VERSION ""

NS_ :

BS_:

BU_: PowertrainControlModule AtmosphericSensor SafetyRestraintSystem2 Aftertreatment_2_GasOutlet Aftertreatment_2_GasIntake DieselParticulateFilterControl Turbocharger SafetyRestraintSystem1 CabDisplay2 Aftertreatment_1_GasOutlet Aftertreatment_1_GasIntake OnBoardDataLogger OffBoardDiagnosticTool2 OffBoardDiagnosticTool1 FileServer ParkingBrakeController SeatController2 FanDriveController SteeringColumnUnit CommunicationUnitRadio CommunicationUnitSatellite CommunicationUnitCellular PropulsionBatteryCharger ChassisController2 ChassisController1 EngineValveControl AuxiliaryHeater2 AuxiliaryHeater1 ClutchUnit RampControl InformationSystem1 SuspensionSystemController2 OilSensor VehicleDynamicStability ExhaustEmissionController TransmissionDisplay2 TransmissionDisplay1 ClimateControl2 WaterPumpController RearAxleSteeringController LightingOperatorControl SeatController1 IgnitionController2 IgnitionController1 TirePressureController CabController2 CabController1 PneumaticSystemController SuspensionSystemController1 HydraulicPumpController EnduranceBrakingSystem RetarderExhaustEngine2 OnBoardDiagnosticUnit HeadwayController RetarderExhaustEngine1 CabDisplay1 ManagementComputer VirtualTerminal OffVehicleGateway PowerTakeOffFront HitchControl AuxiliaryValveControl BodyController TractorTrailerBridge1 StarterSystem ElectricalSystem VehicleSecurity VehicleNavigation AerodynamicControl ElectricalChargingSystem ClimateControl1 TripRecorder InstrumentCluster SuspensionDriveAxle2 SuspensionDriveAxle1 SuspensionSteerAxle SteeringController FuelSystem CruiseControl RetarderDriveline RetarderEngine BrakesDriveAxle2 BrakesDriveAxle1 BrakesSystemController BrakesSteerAxle AxleDrive2 AxleDrive1 AxleSteering PowerTakeOff ShiftConsoleSecondary ShiftConsolePrimary Transmission2 Transmission1 Engine2 Engine1

BO_ 2365446142 EJM1: 8 Vector__XXX
 SG_ Joystick1Button13PressedStatus : 62|2@1+ (1,0) [0|3] "" Vector__XXX
 SG_ Joystick1Button14PressedStatus : 60|2@1+ (1,0) [0|3] "" Vector__XXX
 SG_ Joystick1Button15PressedStatus : 58|2@1+ (1,0) [0|3] "" Vector__XXX
 SG_ Joystick1Button16PressedStatus : 56|2@1+ (1,0) [0|3] "" Vector__XXX
 SG_ Jystick1GripXAxisDetentPosStatus : 54|2@1+ (1,0) [0|3] "" Vector__XXX
 SG_ Jystick1GripYAxisDetentPosStatus : 52|2@1+ (1,0) [0|3] "" Vector__XXX
 SG_ Jystick1ThetaAxisDetentPosStatus : 50|2@1+ (1,0) [0|3] "" Vector__XXX
 SG_ Joystick1ThetaAxisPos : 38|10@1+ (0.1,0) [0|100] "%" Vector__XXX
 SG_ Jystck1ThtAxsClckwsPstvPosStatus : 36|2@1+ (1,0) [0|3] "" Vector__XXX
 SG_ Jystck1ThetaAxisNeutralPosStatus : 32|2@1+ (1,0) [0|3] "" Vector__XXX
 SG_ Joystick1GripYAxisPos : 22|10@1+ (0.1,0) [0|100] "%" Vector__XXX
 SG_ Jystck1GrpYAxsLvrFrwrdPstvPsStts : 20|2@1+ (1,0) [0|3] "" Vector__XXX
 SG_ Jystck1GrpYAxsLvrBckNgtvPsStatus : 18|2@1+ (1,0) [0|3] "" Vector__XXX
 SG_ Aftrtrtmnt1DslExhstFldPrprtsPrlm : 16|2@1+ (1,0) [0|3] "" Vector__XXX
 SG_ Joystick1GripXAxisPos : 6|10@1+ (0.1,0) [0|100] "%" Vector__XXX
 SG_ Jystck1GrpXAxsLvrRghtPstvPsSttus : 4|2@1+ (1,0) [0|3] "" Vector__XXX
 SG_ Jystck1GrpXAxsLvrLftNgtvPsStatus : 2|2@1+ (1,0) [0|3] "" Vector__XXX
 SG_ Jystck1GripXAxisNeutralPosStatus : 0|2@1+ (1,0) [0|3] "" Vector__XXX
 SG_ Jystck1ThtAxsCntrClckwsNgtvPsStt : 34|2@1+ (1,0) [0|3] "" Vector__XXX

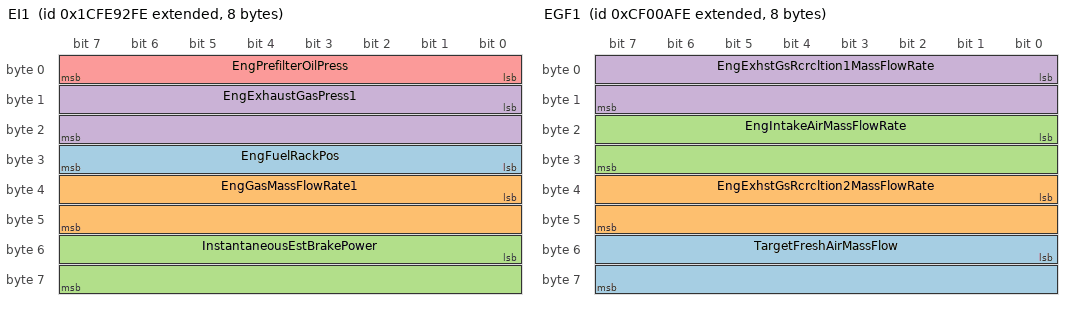
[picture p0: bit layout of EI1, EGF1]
BO_ 2633929470 EI1: 8 Vector__XXX
 SG_ EngFuelRackPos : 24|8@1+ (0.4,0) [0|100] "%" Vector__XXX
 SG_ EngGasMassFlowRate1 : 32|16@1+ (0.05,0) [0|3212.75] "kg/h" Vector__XXX
 SG_ InstantaneousEstBrakePower : 48|16@1+ (0.5,0) [0|32127.5] "kW" Vector__XXX
 SG_ EngExhaustGasPress1 : 8|16@1+ (0.0078125,-250) [-250|251.9921875] "kPa" Vector__XXX
 SG_ EngPrefilterOilPress : 0|8@1+ (4,0) [0|1000] "kPa" Vector__XXX

BO_ 2633937406 EH: 8 Vector__XXX
 SG_ TotalECURunTime : 32|32@1+ (0.05,0) [0|210554060.75] "h" Vector__XXX
 SG_ TotalECUDistance : 0|32@1+ (0.125,0) [0|526385151.875] "km" Vector__XXX

BO_ 2364541694 EGF1: 8 Vector__XXX
 SG_ TargetFreshAirMassFlow : 48|16@1+ (0.05,0) [0|3212.75] "kg/h" Vector__XXX
 SG_ EngExhstGsRcrcltion2MassFlowRate : 32|16@1+ (0.05,0) [0|3212.75] "kg/h" Vector__XXX
 SG_ EngIntakeAirMassFlowRate : 16|16@1+ (0.05,0) [0|3212.75] "kg/h" Vector__XXX
 SG_ EngExhstGsRcrcltion1MassFlowRate : 0|16@1+ (0.05,0) [0|3212.75] "kg/h" Vector__XXX

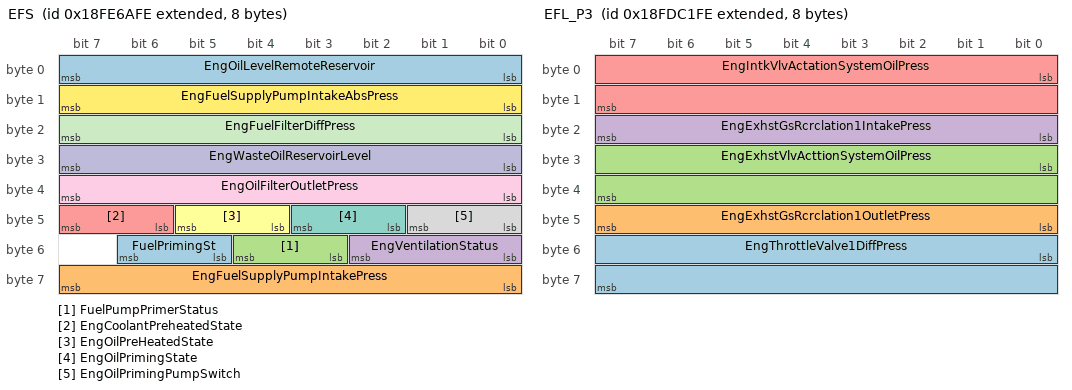
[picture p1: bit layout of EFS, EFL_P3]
BO_ 2566810366 EFS: 8 Vector__XXX
 SG_ FuelPrimingSt : 53|2@1+ (1,0) [0|3] "" Vector__XXX
 SG_ EngFuelSupplyPumpIntakePress : 56|8@1+ (2,0) [0|500] "kPa" Vector__XXX
 SG_ FuelPumpPrimerStatus : 51|2@1+ (1,0) [0|3] "" Vector__XXX
 SG_ EngVentilationStatus : 48|3@1+ (1,0) [0|7] "" Vector__XXX
 SG_ EngCoolantPreheatedState : 46|2@1+ (1,0) [0|3] "" Vector__XXX
 SG_ EngOilPreHeatedState : 44|2@1+ (1,0) [0|3] "" Vector__XXX
 SG_ EngOilPrimingState : 42|2@1+ (1,0) [0|3] "" Vector__XXX
 SG_ EngOilPrimingPumpSwitch : 40|2@1+ (1,0) [0|3] "" Vector__XXX
 SG_ EngOilFilterOutletPress : 32|8@1+ (4,0) [0|1000] "kPa" Vector__XXX
 SG_ EngWasteOilReservoirLevel : 24|8@1+ (0.4,0) [0|100] "%" Vector__XXX
 SG_ EngFuelFilterDiffPress : 16|8@1+ (2,0) [0|500] "kPa" Vector__XXX
 SG_ EngFuelSupplyPumpIntakeAbsPress : 8|8@1+ (2,0) [0|500] "kPa" Vector__XXX
 SG_ EngOilLevelRemoteReservoir : 0|8@1+ (0.4,0) [0|100] "%" Vector__XXX

BO_ 2566767102 EFL_P3: 8 Vector__XXX
 SG_ EngThrottleValve1DiffPress : 48|16@1+ (0.1,0) [0|6425.5] "kPa" Vector__XXX
 SG_ EngExhstGsRcrclation1OutletPress : 40|8@1+ (2,0) [0|500] "kPa" Vector__XXX
 SG_ EngExhstVlvActtionSystemOilPress : 24|16@1+ (0.00390625,0) [0|250.99609375] "MPa" Vector__XXX
 SG_ EngExhstGsRcrclation1IntakePress : 16|8@1+ (2,0) [0|500] "kPa" Vector__XXX
 SG_ EngIntkVlvActationSystemOilPress : 0|16@1+ (0.00390625,0) [0|250.99609375] "MPa" Vector__XXX

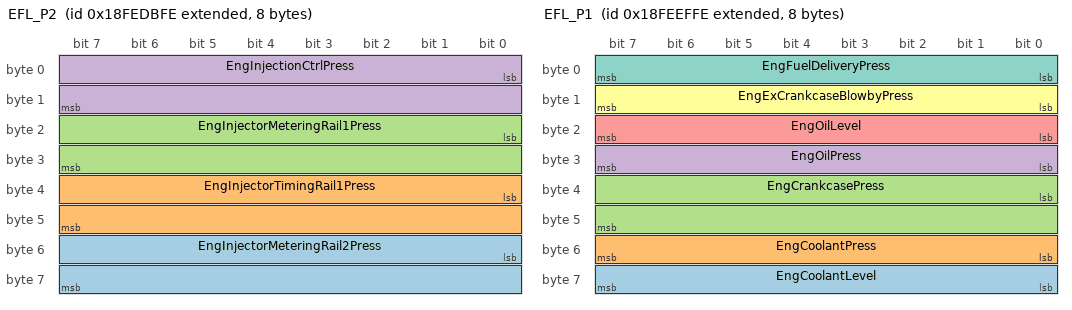
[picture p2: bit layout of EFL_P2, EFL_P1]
BO_ 2566839294 EFL_P2: 8 Vector__XXX
 SG_ EngInjectorMeteringRail2Press : 48|16@1+ (0.00390625,0) [0|250.99609375] "MPa" Vector__XXX
 SG_ EngInjectorTimingRail1Press : 32|16@1+ (0.00390625,0) [0|250.99609375] "MPa" Vector__XXX
 SG_ EngInjectorMeteringRail1Press : 16|16@1+ (0.00390625,0) [0|250.99609375] "MPa" Vector__XXX
 SG_ EngInjectionCtrlPress : 0|16@1+ (0.00390625,0) [0|250.99609375] "MPa" Vector__XXX

BO_ 2566844414 EFL_P1: 8 Vector__XXX
 SG_ EngCoolantLevel : 56|8@1+ (0.4,0) [0|100] "%" Vector__XXX
 SG_ EngCoolantPress : 48|8@1+ (2,0) [0|500] "kPa" Vector__XXX
 SG_ EngCrankcasePress : 32|16@1+ (0.0078125,-250) [-250|251.9921875] "kPa" Vector__XXX
 SG_ EngOilPress : 24|8@1+ (4,0) [0|1000] "kPa" Vector__XXX
 SG_ EngOilLevel : 16|8@1+ (0.4,0) [0|100] "%" Vector__XXX
 SG_ EngExCrankcaseBlowbyPress : 8|8@1+ (0.05,0) [0|12.5] "kPa" Vector__XXX
 SG_ EngFuelDeliveryPress : 0|8@1+ (4,0) [0|1000] "kPa" Vector__XXX

BO_ 2633929726 EES: 8 Vector__XXX
 SG_ SafetyWireStatus : 16|2@1+ (1,0) [0|3] "" Vector__XXX
 SG_ ElectricalLoad : 0|16@1+ (0.5,0) [0|32127.5] "kW" Vector__XXX

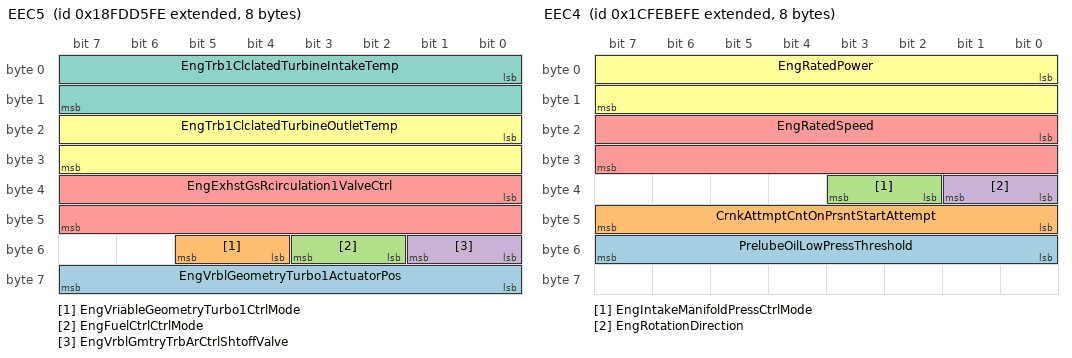
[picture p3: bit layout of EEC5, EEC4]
BO_ 2566772222 EEC5: 8 Vector__XXX
 SG_ EngVrblGeometryTurbo1ActuatorPos : 56|8@1+ (0.4,0) [0|100] "%" Vector__XXX
 SG_ EngVriableGeometryTurbo1CtrlMode : 52|2@1+ (1,0) [0|3] "" Vector__XXX
 SG_ EngFuelCtrlCtrlMode : 50|2@1+ (1,0) [0|3] "" Vector__XXX
 SG_ EngVrblGmtryTrbArCtrlShtoffValve : 48|2@1+ (1,0) [0|3] "" Vector__XXX
 SG_ EngExhstGsRcirculation1ValveCtrl : 32|16@1+ (0.0025,0) [0|100] "%" Vector__XXX
 SG_ EngTrb1ClclatedTurbineOutletTemp : 16|16@1+ (0.03125,-273) [-273|1734.96875] "°C" Vector__XXX
 SG_ EngTrb1ClclatedTurbineIntakeTemp : 0|16@1+ (0.03125,-273) [-273|1734.96875] "°C" Vector__XXX

BO_ 2633940734 EEC4: 8 Vector__XXX
 SG_ PrelubeOilLowPressThreshold : 48|8@1+ (4,0) [0|1000] "kPa" Vector__XXX
 SG_ CrnkAttmptCntOnPrsntStartAttempt : 40|8@1+ (1,0) [0|250] "" Vector__XXX
 SG_ EngIntakeManifoldPressCtrlMode : 34|2@1+ (1,0) [0|3] "" Vector__XXX
 SG_ EngRotationDirection : 32|2@1+ (1,0) [0|3] "" Vector__XXX
 SG_ EngRatedSpeed : 16|16@1+ (0.125,0) [0|8031.875] "rpm" Vector__XXX
 SG_ EngRatedPower : 0|16@1+ (0.5,0) [0|32127.5] "kW" Vector__XXX

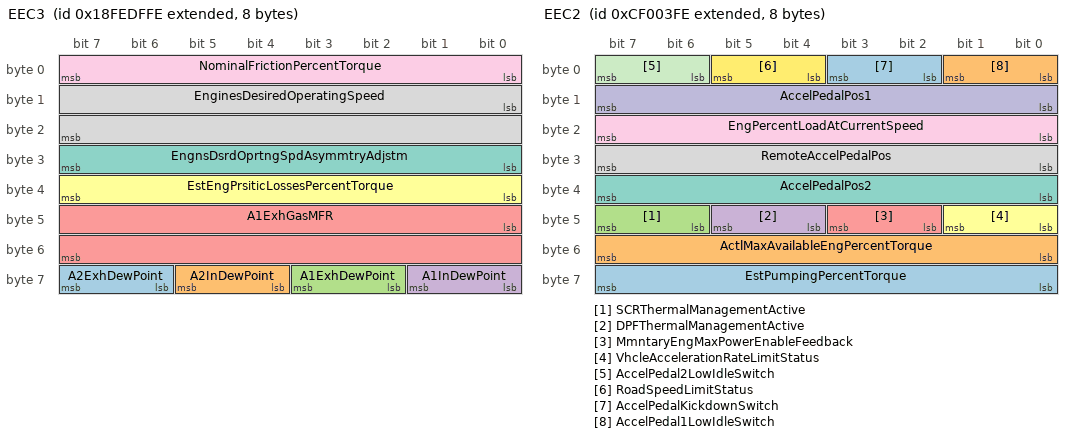
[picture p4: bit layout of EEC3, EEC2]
BO_ 2566840318 EEC3: 8 Vector__XXX
 SG_ A2ExhDewPoint : 62|2@1+ (1,0) [0|3] "" Vector__XXX
 SG_ A2InDewPoint : 60|2@1+ (1,0) [0|3] "" Vector__XXX
 SG_ A1ExhDewPoint : 58|2@1+ (1,0) [0|3] "" Vector__XXX
 SG_ A1InDewPoint : 56|2@1+ (1,0) [0|3] "" Vector__XXX
 SG_ A1ExhGasMFR : 40|16@1+ (0.2,0) [0|12851] "kg/h" Vector__XXX
 SG_ EstEngPrsiticLossesPercentTorque : 32|8@1+ (1,-125) [0|125] "%" Vector__XXX
 SG_ EngnsDsrdOprtngSpdAsymmtryAdjstm : 24|8@1+ (1,0) [0|250] "" Vector__XXX
 SG_ EnginesDesiredOperatingSpeed : 8|16@1+ (0.125,0) [0|8031.875] "rpm" Vector__XXX
 SG_ NominalFrictionPercentTorque : 0|8@1+ (1,-125) [-125|125] "%" Vector__XXX

BO_ 2364539902 EEC2: 8 Vector__XXX
 SG_ EstPumpingPercentTorque : 56|8@1+ (1,-125) [-125|125] "%" Vector__XXX
 SG_ ActlMaxAvailableEngPercentTorque : 48|8@1+ (0.4,0) [0|100] "%" Vector__XXX
 SG_ SCRThermalManagementActive : 46|2@1+ (1,0) [0|3] "" Vector__XXX
 SG_ DPFThermalManagementActive : 44|2@1+ (1,0) [0|3] "" Vector__XXX
 SG_ MmntaryEngMaxPowerEnableFeedback : 42|2@1+ (1,0) [0|3] "" Vector__XXX
 SG_ VhcleAccelerationRateLimitStatus : 40|2@1+ (1,0) [0|3] "" Vector__XXX
 SG_ AccelPedalPos2 : 32|8@1+ (0.4,0) [0|100] "%" Vector__XXX
 SG_ RemoteAccelPedalPos : 24|8@1+ (0.4,0) [0|100] "%" Vector__XXX
 SG_ EngPercentLoadAtCurrentSpeed : 16|8@1+ (1,0) [0|125] "%" Vector__XXX
 SG_ AccelPedalPos1 : 8|8@1+ (0.4,0) [0|100] "%" Vector__XXX
 SG_ AccelPedal2LowIdleSwitch : 6|2@1+ (1,0) [0|3] "" Vector__XXX
 SG_ RoadSpeedLimitStatus : 4|2@1+ (1,0) [0|3] "" Vector__XXX
 SG_ AccelPedalKickdownSwitch : 2|2@1+ (1,0) [0|3] "" Vector__XXX
 SG_ AccelPedal1LowIdleSwitch : 0|2@1+ (1,0) [0|3] "" Vector__XXX

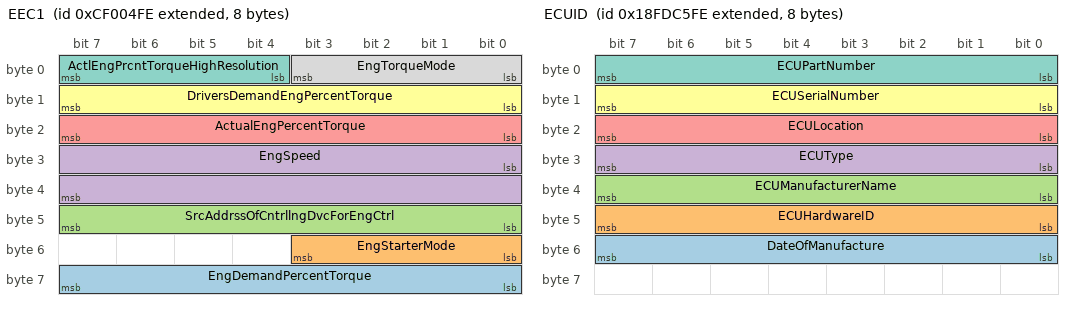
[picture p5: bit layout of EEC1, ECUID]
BO_ 2364540158 EEC1: 8 Vector__XXX
 SG_ EngDemandPercentTorque : 56|8@1+ (1,-125) [-125|125] "%" Vector__XXX
 SG_ EngStarterMode : 48|4@1+ (1,0) [0|15] "" Vector__XXX
 SG_ SrcAddrssOfCntrllngDvcForEngCtrl : 40|8@1+ (1,0) [0|253] "" Vector__XXX
 SG_ EngSpeed : 24|16@1+ (0.125,0) [0|8031.875] "rpm" Vector__XXX
 SG_ ActualEngPercentTorque : 16|8@1+ (1,-125) [0|125] "%" Vector__XXX
 SG_ DriversDemandEngPercentTorque : 8|8@1+ (1,-125) [0|125] "%" Vector__XXX
 SG_ ActlEngPrcntTorqueHighResolution : 4|4@1+ (0.125,0) [0|0.875] "%" Vector__XXX
 SG_ EngTorqueMode : 0|4@1+ (1,0) [0|15] "" Vector__XXX

BO_ 2566768126 ECUID: 8 Vector__XXX
 SG_ DateOfManufacture : 48|8@1+ (1,0) [0|255] "" Vector__XXX
 SG_ ECUHardwareID : 40|8@1+ (1,0) [0|255] "" Vector__XXX
 SG_ ECUManufacturerName : 32|8@1+ (1,0) [0|255] "" Vector__XXX
 SG_ ECUType : 24|8@1+ (1,0) [0|255] "" Vector__XXX
 SG_ ECULocation : 16|8@1+ (1,0) [0|255] "" Vector__XXX
 SG_ ECUSerialNumber : 8|8@1+ (1,0) [0|255] "" Vector__XXX
 SG_ ECUPartNumber : 0|8@1+ (1,0) [0|255] "" Vector__XXX

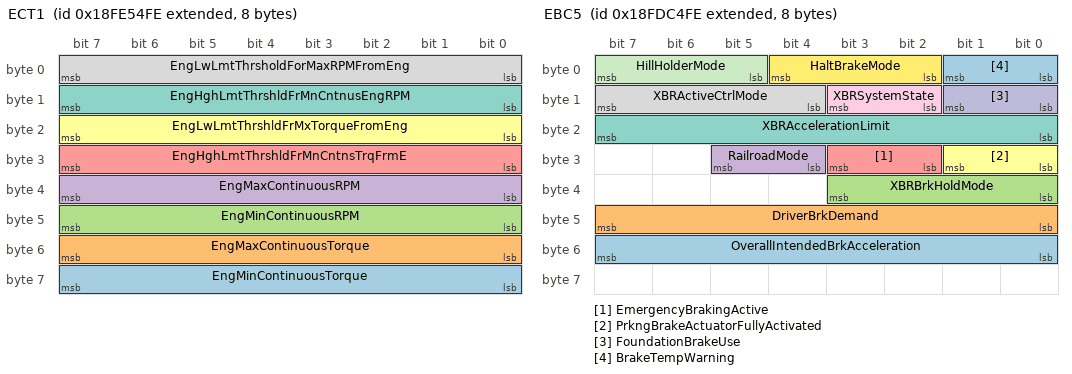
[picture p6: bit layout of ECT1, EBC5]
BO_ 2566804734 ECT1: 8 Vector__XXX
 SG_ EngMinContinuousTorque : 56|8@1+ (1,-125) [-125|125] "%" Vector__XXX
 SG_ EngMaxContinuousTorque : 48|8@1+ (1,-125) [-125|125] "%" Vector__XXX
 SG_ EngMinContinuousRPM : 40|8@1+ (32,0) [0|8000] "rpm" Vector__XXX
 SG_ EngMaxContinuousRPM : 32|8@1+ (32,0) [0|8000] "rpm" Vector__XXX
 SG_ EngHghLmtThrshldFrMnCntnsTrqFrmE : 24|8@1+ (1,-125) [-125|125] "%" Vector__XXX
 SG_ EngLwLmtThrshldFrMxTorqueFromEng : 16|8@1+ (1,-125) [-125|125] "%" Vector__XXX
 SG_ EngHghLmtThrshldFrMnCntnusEngRPM : 8|8@1+ (32,0) [0|8000] "rpm" Vector__XXX
 SG_ EngLwLmtThrsholdForMaxRPMFromEng : 0|8@1+ (32,0) [0|8000] "rpm" Vector__XXX

BO_ 2566841342 EC1: 40 Vector__XXX
 SG_ DefaultIdleTrqLmt : 312|8@1+ (1,-125) [0|125] "%" Vector__XXX
 SG_ SupportTSC1CtrlPurposeGroup4 : 304|8@1+ (1,0) [0|255] "" Vector__XXX
 SG_ SupportTSC1CtrlPurposeGroup3 : 296|8@1+ (1,0) [0|255] "" Vector__XXX
 SG_ SupportTSC1CtrlPurposeGroup2 : 288|8@1+ (1,0) [0|255] "" Vector__XXX
 SG_ SupportTSC1CtrlPurposeGroup1 : 280|8@1+ (1,0) [0|255] "" Vector__XXX
 SG_ SupportVariableRateTSC1Message : 272|8@1+ (1,0) [0|255] "" Vector__XXX
 SG_ EngDefaultTorqueLimit : 256|16@1+ (1,0) [0|64255] "Nm" Vector__XXX
 SG_ EngMomentOfInertia : 240|16@1+ (0.004,0) [0|257.02] "kg*m²" Vector__XXX
 SG_ EngExRngRqstdSpdCtrlRngUpprLimit : 224|16@1+ (0.125,0) [0|8031.875] "rpm" Vector__XXX
 SG_ EngRqstdTrqueCtrlRangeUpperLimit : 216|8@1+ (1,-125) [0|125] "%" Vector__XXX
 SG_ EngRqstdTrqueCtrlRangeLowerLimit : 208|8@1+ (1,-125) [0|125] "%" Vector__XXX
 SG_ EngRqstdSpeedCtrlRangeUpperLimit : 200|8@1+ (10,0) [0|2500] "rpm" Vector__XXX
 SG_ EngRqstdSpeedCtrlRangeLowerLimit : 192|8@1+ (10,0) [0|2500] "rpm" Vector__XXX
 SG_ EngMaxMomentaryOverrideTimeLimit : 184|8@1+ (0.1,0) [0|25] "s" Vector__XXX
 SG_ EngMxMmentaryOverrideSpeedPoint7 : 168|16@1+ (0.125,0) [0|8031.875] "rpm" Vector__XXX
 SG_ EngReferenceTorque : 152|16@1+ (1,0) [0|64255] "Nm" Vector__XXX
 SG_ EngGain : 136|16@1+ (0.00078125,0) [0|50.19921875] "%/rpm" Vector__XXX
 SG_ EngSpeedAtHighIdlePoint6 : 120|16@1+ (0.125,0) [0|8031.875] "rpm" Vector__XXX
 SG_ EngPercentTorqueAtPoint5 : 112|8@1+ (1,-125) [0|125] "%" Vector__XXX
 SG_ EngSpeedAtPoint5 : 96|16@1+ (0.125,0) [0|8031.875] "rpm" Vector__XXX
 SG_ EngPercentTorqueAtPoint4 : 88|8@1+ (1,-125) [0|125] "%" Vector__XXX
 SG_ EngSpeedAtPoint4 : 72|16@1+ (0.125,0) [0|8031.875] "rpm" Vector__XXX
 SG_ EngPercentTorqueAtPoint3 : 64|8@1+ (1,-125) [0|125] "%" Vector__XXX
 SG_ EngSpeedAtPoint3 : 48|16@1+ (0.125,0) [0|8031.875] "rpm" Vector__XXX
 SG_ EngPercentTorqueAtPoint2 : 40|8@1+ (1,-125) [0|125] "%" Vector__XXX
 SG_ EngSpeedAtPoint2 : 24|16@1+ (0.125,0) [0|8031.875] "rpm" Vector__XXX
 SG_ EngPercentTorqueAtIdlePoint1 : 16|8@1+ (1,-125) [0|125] "%" Vector__XXX
 SG_ EngSpeedAtIdlePoint1 : 0|16@1+ (0.125,0) [0|8031.875] "rpm" Vector__XXX

BO_ 2566767870 EBC5: 8 Vector__XXX
 SG_ OverallIntendedBrkAcceleration : 48|8@1+ (0.1,-12.5) [-12.5|12.5] "m/s²" Vector__XXX
 SG_ DriverBrkDemand : 40|8@1+ (0.1,-12.5) [-12.5|12.5] "m/s²" Vector__XXX
 SG_ XBRBrkHoldMode : 32|4@1+ (1,0) [0|15] "" Vector__XXX
 SG_ RailroadMode : 28|2@1+ (1,0) [0|3] "" Vector__XXX
 SG_ EmergencyBrakingActive : 26|2@1+ (1,0) [0|3] "" Vector__XXX
 SG_ PrkngBrakeActuatorFullyActivated : 24|2@1+ (1,0) [0|3] "" Vector__XXX
 SG_ XBRAccelerationLimit : 16|8@1+ (0.1,-12.5) [-10|10] "m/s²" Vector__XXX
 SG_ XBRActiveCtrlMode : 12|4@1+ (1,0) [0|15] "" Vector__XXX
 SG_ XBRSystemState : 10|2@1+ (1,0) [0|3] "" Vector__XXX
 SG_ FoundationBrakeUse : 8|2@1+ (1,0) [0|3] "" Vector__XXX
 SG_ HillHolderMode : 5|3@1+ (1,0) [0|7] "" Vector__XXX
 SG_ HaltBrakeMode : 2|3@1+ (1,0) [0|7] "" Vector__XXX
 SG_ BrakeTempWarning : 0|2@1+ (1,0) [0|3] "" Vector__XXX

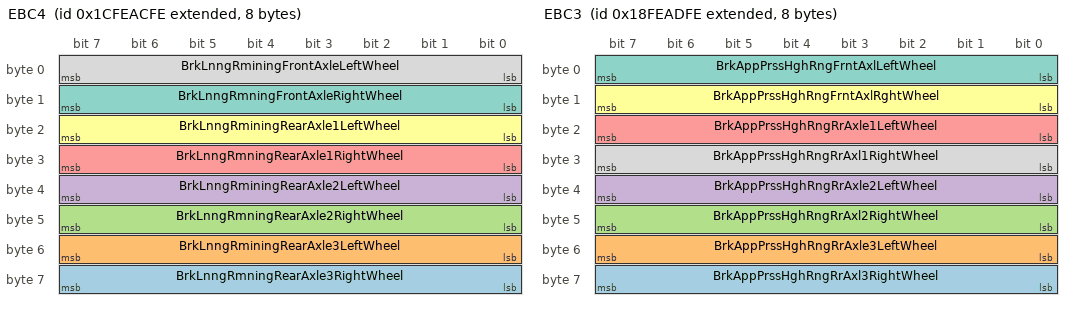
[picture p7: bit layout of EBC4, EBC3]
BO_ 2633936126 EBC4: 8 Vector__XXX
 SG_ BrkLnngRmningRearAxle3RightWheel : 56|8@1+ (0.4,0) [0|100] "%" Vector__XXX
 SG_ BrkLnngRminingRearAxle3LeftWheel : 48|8@1+ (0.4,0) [0|100] "%" Vector__XXX
 SG_ BrkLnngRmningRearAxle2RightWheel : 40|8@1+ (0.4,0) [0|100] "%" Vector__XXX
 SG_ BrkLnngRminingRearAxle2LeftWheel : 32|8@1+ (0.4,0) [0|100] "%" Vector__XXX
 SG_ BrkLnngRmningRearAxle1RightWheel : 24|8@1+ (0.4,0) [0|100] "%" Vector__XXX
 SG_ BrkLnngRminingRearAxle1LeftWheel : 16|8@1+ (0.4,0) [0|100] "%" Vector__XXX
 SG_ BrkLnngRmningFrontAxleRightWheel : 8|8@1+ (0.4,0) [0|100] "%" Vector__XXX
 SG_ BrkLnngRminingFrontAxleLeftWheel : 0|8@1+ (0.4,0) [0|100] "%" Vector__XXX

BO_ 2566827518 EBC3: 8 Vector__XXX
 SG_ BrkAppPrssHghRngRrAxl3RightWheel : 56|8@1+ (5,0) [0|1250] "kPa" Vector__XXX
 SG_ BrkAppPrssHghRngRrAxle3LeftWheel : 48|8@1+ (5,0) [0|1250] "kPa" Vector__XXX
 SG_ BrkAppPrssHghRngRrAxl2RightWheel : 40|8@1+ (5,0) [0|1250] "kPa" Vector__XXX
 SG_ BrkAppPrssHghRngRrAxle2LeftWheel : 32|8@1+ (5,0) [0|1250] "kPa" Vector__XXX
 SG_ BrkAppPrssHghRngRrAxle1LeftWheel : 16|8@1+ (5,0) [0|1250] "kPa" Vector__XXX
 SG_ BrkAppPrssHghRngFrntAxlRghtWheel : 8|8@1+ (5,0) [0|1250] "kPa" Vector__XXX
 SG_ BrkAppPrssHghRngFrntAxlLeftWheel : 0|8@1+ (5,0) [0|1250] "kPa" Vector__XXX
 SG_ BrkAppPrssHghRngRrAxl1RightWheel : 24|8@1+ (5,0) [0|1250] "kPa" Vector__XXX

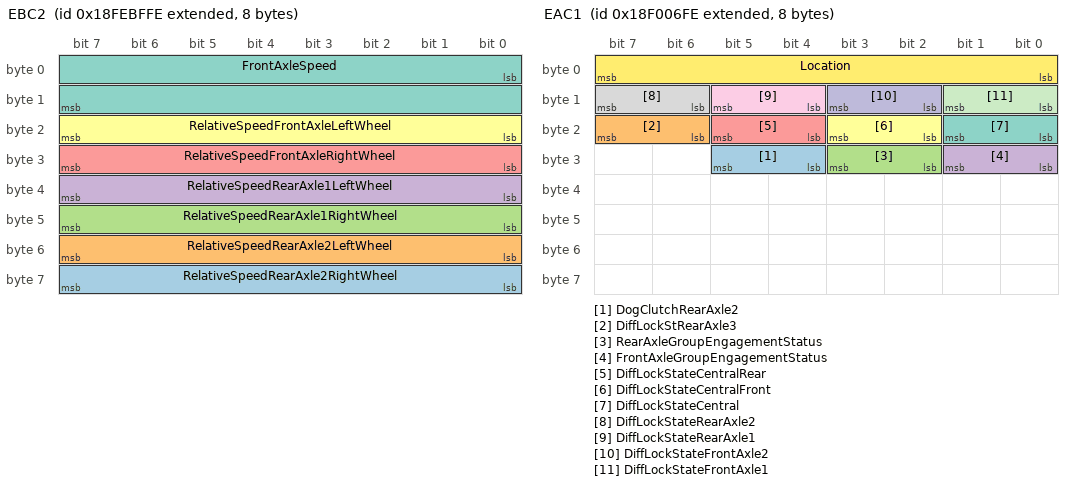
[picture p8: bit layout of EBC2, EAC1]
BO_ 2566832126 EBC2: 8 Vector__XXX
 SG_ RelativeSpeedRearAxle2RightWheel : 56|8@1+ (0.0625,-7.8125) [-7.8125|7.8125] "km/h" Vector__XXX
 SG_ RelativeSpeedRearAxle2LeftWheel : 48|8@1+ (0.0625,-7.8125) [-7.8125|7.8125] "km/h" Vector__XXX
 SG_ RelativeSpeedRearAxle1RightWheel : 40|8@1+ (0.0625,-7.8125) [-7.8125|7.8125] "km/h" Vector__XXX
 SG_ RelativeSpeedRearAxle1LeftWheel : 32|8@1+ (0.0625,-7.8125) [-7.8125|7.8125] "km/h" Vector__XXX
 SG_ RelativeSpeedFrontAxleRightWheel : 24|8@1+ (0.0625,-7.8125) [-7.8125|7.8125] "km/h" Vector__XXX
 SG_ RelativeSpeedFrontAxleLeftWheel : 16|8@1+ (0.0625,-7.8125) [-7.8125|7.8125] "km/h" Vector__XXX
 SG_ FrontAxleSpeed : 0|16@1+ (0.00390625,0) [0|250.99609375] "km/h" Vector__XXX

BO_ 2565865982 EBC1: 8 Vector__XXX
 SG_ RailroadModeSw : 56|2@1+ (1,0) [0|3] "" Vector__XXX
 SG_ TrctrMntdTrailerABSWarningSignal : 62|2@1+ (1,0) [0|3] "" Vector__XXX
 SG_ TrailerABSStatus : 60|2@1+ (1,0) [0|3] "" Vector__XXX
 SG_ HaltBrakeSwitch : 58|2@1+ (1,0) [0|3] "" Vector__XXX
 SG_ SrcAddrssOfCntrllngDvcFrBrkeCtrl : 48|8@1+ (1,0) [0|253] "" Vector__XXX
 SG_ ATC_ASRInformationSignal : 46|2@1+ (1,0) [0|3] "" Vector__XXX
 SG_ ABS_EBSAmberWarningSignal : 44|2@1+ (1,0) [0|3] "" Vector__XXX
 SG_ EBSRedWarningSignal : 42|2@1+ (1,0) [0|3] "" Vector__XXX
 SG_ ABSFullyOperational : 40|2@1+ (1,0) [0|3] "" Vector__XXX
 SG_ EngRetarderSelection : 32|8@1+ (0.4,0) [0|100] "%" Vector__XXX
 SG_ RemoteAccelEnableSwitch : 30|2@1+ (1,0) [0|3] "" Vector__XXX
 SG_ EngAuxShutdownSwitch : 28|2@1+ (1,0) [0|3] "" Vector__XXX
 SG_ EngDerateSwitch : 26|2@1+ (1,0) [0|3] "" Vector__XXX
 SG_ AccelInterlockSwitch : 24|2@1+ (1,0) [0|3] "" Vector__XXX
 SG_ TractionCtrlOverrideSwitch : 22|2@1+ (1,0) [0|3] "" Vector__XXX
 SG_ ASRHillHolderSwitch : 20|2@1+ (1,0) [0|3] "" Vector__XXX
 SG_ ASROffroadSwitch : 18|2@1+ (1,0) [0|3] "" Vector__XXX
 SG_ ABSOffroadSwitch : 16|2@1+ (1,0) [0|3] "" Vector__XXX
 SG_ BrakePedalPos : 8|8@1+ (0.4,0) [0|100] "%" Vector__XXX
 SG_ EBSBrakeSwitch : 6|2@1+ (1,0) [0|3] "" Vector__XXX
 SG_ AntiLockBrakingActive : 4|2@1+ (1,0) [0|3] "" Vector__XXX
 SG_ ASRBrakeCtrlActive : 2|2@1+ (1,0) [0|3] "" Vector__XXX
 SG_ ASREngCtrlActive : 0|2@1+ (1,0) [0|3] "" Vector__XXX

BO_ 2565867262 EAC1: 8 Vector__XXX
 SG_ DogClutchRearAxle2 : 28|2@1+ (1,0) [0|3] "" Vector__XXX
 SG_ DiffLockStRearAxle3 : 22|2@1+ (1,0) [0|3] "" Vector__XXX
 SG_ RearAxleGroupEngagementStatus : 26|2@1+ (1,0) [0|3] "" Vector__XXX
 SG_ FrontAxleGroupEngagementStatus : 24|2@1+ (1,0) [0|3] "" Vector__XXX
 SG_ DiffLockStateCentralRear : 20|2@1+ (1,0) [0|3] "" Vector__XXX
 SG_ DiffLockStateCentralFront : 18|2@1+ (1,0) [0|3] "" Vector__XXX
 SG_ DiffLockStateCentral : 16|2@1+ (1,0) [0|3] "" Vector__XXX
 SG_ DiffLockStateRearAxle2 : 14|2@1+ (1,0) [0|3] "" Vector__XXX
 SG_ DiffLockStateRearAxle1 : 12|2@1+ (1,0) [0|3] "" Vector__XXX
 SG_ DiffLockStateFrontAxle2 : 10|2@1+ (1,0) [0|3] "" Vector__XXX
 SG_ DiffLockStateFrontAxle1 : 8|2@1+ (1,0) [0|3] "" Vector__XXX
 SG_ Location : 0|8@1+ (1,0) [0|255] "" Vector__XXX

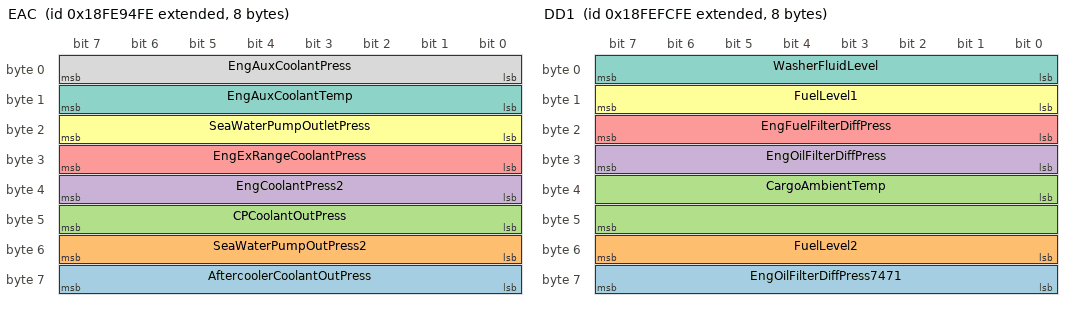
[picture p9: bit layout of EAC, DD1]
BO_ 2566821118 EAC: 8 Vector__XXX
 SG_ AftercoolerCoolantOutPress : 56|8@1+ (4,0) [0|1000] "kPa" Vector__XXX
 SG_ SeaWaterPumpOutPress2 : 48|8@1+ (2,0) [0|500] "kPa" Vector__XXX
 SG_ CPCoolantOutPress : 40|8@1+ (2,0) [0|500] "kPa" Vector__XXX
 SG_ EngCoolantPress2 : 32|8@1+ (4,0) [0|1000] "kPa" Vector__XXX
 SG_ EngExRangeCoolantPress : 24|8@1+ (4,0) [0|1000] "kPa" Vector__XXX
 SG_ SeaWaterPumpOutletPress : 16|8@1+ (2,0) [0|500] "kPa" Vector__XXX
 SG_ EngAuxCoolantTemp : 8|8@1+ (1,-40) [-40|210] "°C" Vector__XXX
 SG_ EngAuxCoolantPress : 0|8@1+ (4,0) [0|1000] "kPa" Vector__XXX

BO_ 2566810622 DI: 8 Vector__XXX
 SG_ Driver2Identification : 8|8@1+ (1,0) [0|255] "" Vector__XXX
 SG_ Driver1Identification : 0|8@1+ (1,0) [0|255] "" Vector__XXX

BO_ 2566847742 DD1: 8 Vector__XXX
 SG_ EngOilFilterDiffPress7471 : 56|8@1+ (5,0) [0|1250] "kPa" Vector__XXX
 SG_ FuelLevel2 : 48|8@1+ (0.4,0) [0|100] "%" Vector__XXX
 SG_ CargoAmbientTemp : 32|16@1+ (0.03125,-273) [-273|1734.96875] "°C" Vector__XXX
 SG_ EngOilFilterDiffPress : 24|8@1+ (0.5,0) [0|125] "kPa" Vector__XXX
 SG_ EngFuelFilterDiffPress : 16|8@1+ (2,0) [0|500] "kPa" Vector__XXX
 SG_ FuelLevel1 : 8|8@1+ (0.4,0) [0|100] "%" Vector__XXX
 SG_ WasherFluidLevel : 0|8@1+ (0.4,0) [0|100] "%" Vector__XXX

BO_ 2314732030 GNSSPositionRapidUpdate: 8 Vector__XXX
 SG_ Longitude : 32|32@1- (1E-007,0) [-180|180] "deg" Vector__XXX
 SG_ Latitude : 0|32@1- (1E-007,0) [-90|90] "deg" Vector__XXX

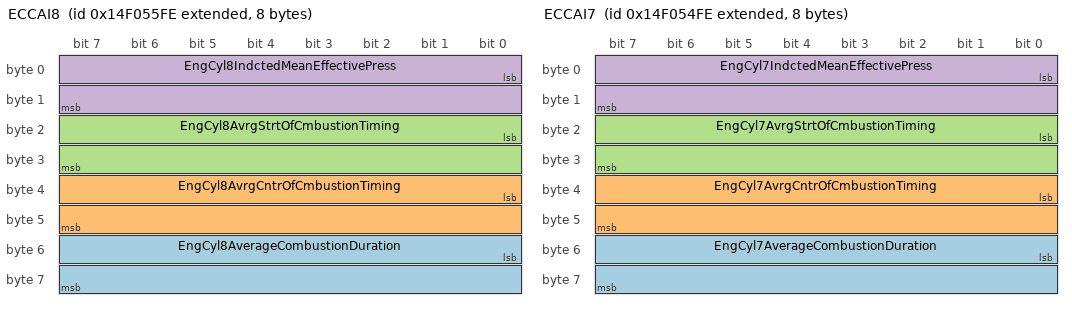
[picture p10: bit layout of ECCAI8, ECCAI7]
BO_ 2498778622 ECCAI8: 8 Vector__XXX
 SG_ EngCyl8AverageCombustionDuration : 48|16@1+ (0.0078125,0) [0|501.9921875] "deg" Vector__XXX
 SG_ EngCyl8AvrgCntrOfCmbustionTiming : 32|16@1+ (0.0078125,-250) [-250|251.9921875] "deg" Vector__XXX
 SG_ EngCyl8AvrgStrtOfCmbustionTiming : 16|16@1+ (0.0078125,-250) [-250|251.9921875] "deg" Vector__XXX
 SG_ EngCyl8IndctedMeanEffectivePress : 0|16@1+ (0.0001220703125,-1) [-1|6.8436279296875] "MPa" Vector__XXX

BO_ 2498778366 ECCAI7: 8 Vector__XXX
 SG_ EngCyl7AverageCombustionDuration : 48|16@1+ (0.0078125,0) [0|501.9921875] "deg" Vector__XXX
 SG_ EngCyl7AvrgCntrOfCmbustionTiming : 32|16@1+ (0.0078125,-250) [-250|251.9921875] "deg" Vector__XXX
 SG_ EngCyl7AvrgStrtOfCmbustionTiming : 16|16@1+ (0.0078125,-250) [-250|251.9921875] "deg" Vector__XXX
 SG_ EngCyl7IndctedMeanEffectivePress : 0|16@1+ (0.0001220703125,-1) [-1|6.8436279296875] "MPa" Vector__XXX

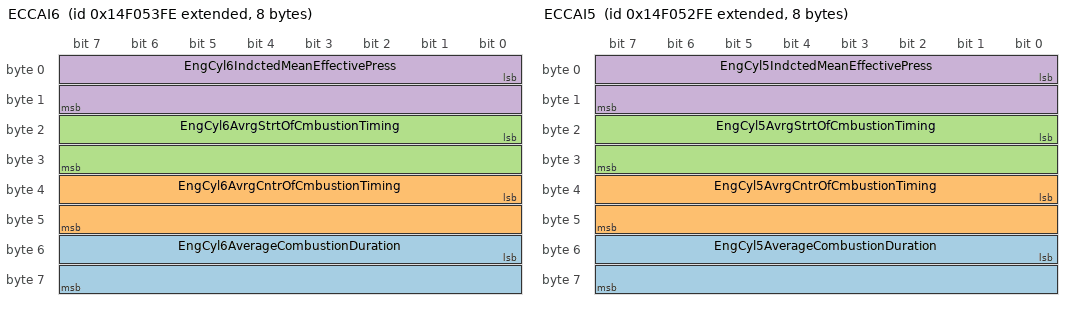
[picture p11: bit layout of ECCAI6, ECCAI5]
BO_ 2498778110 ECCAI6: 8 Vector__XXX
 SG_ EngCyl6AverageCombustionDuration : 48|16@1+ (0.0078125,0) [0|501.9921875] "deg" Vector__XXX
 SG_ EngCyl6AvrgCntrOfCmbustionTiming : 32|16@1+ (0.0078125,-250) [-250|251.9921875] "deg" Vector__XXX
 SG_ EngCyl6AvrgStrtOfCmbustionTiming : 16|16@1+ (0.0078125,-250) [-250|251.9921875] "deg" Vector__XXX
 SG_ EngCyl6IndctedMeanEffectivePress : 0|16@1+ (0.0001220703125,-1) [-1|6.8436279296875] "MPa" Vector__XXX

BO_ 2498777854 ECCAI5: 8 Vector__XXX
 SG_ EngCyl5AverageCombustionDuration : 48|16@1+ (0.0078125,0) [0|501.9921875] "deg" Vector__XXX
 SG_ EngCyl5AvrgCntrOfCmbustionTiming : 32|16@1+ (0.0078125,-250) [-250|251.9921875] "deg" Vector__XXX
 SG_ EngCyl5AvrgStrtOfCmbustionTiming : 16|16@1+ (0.0078125,-250) [-250|251.9921875] "deg" Vector__XXX
 SG_ EngCyl5IndctedMeanEffectivePress : 0|16@1+ (0.0001220703125,-1) [-1|6.8436279296875] "MPa" Vector__XXX

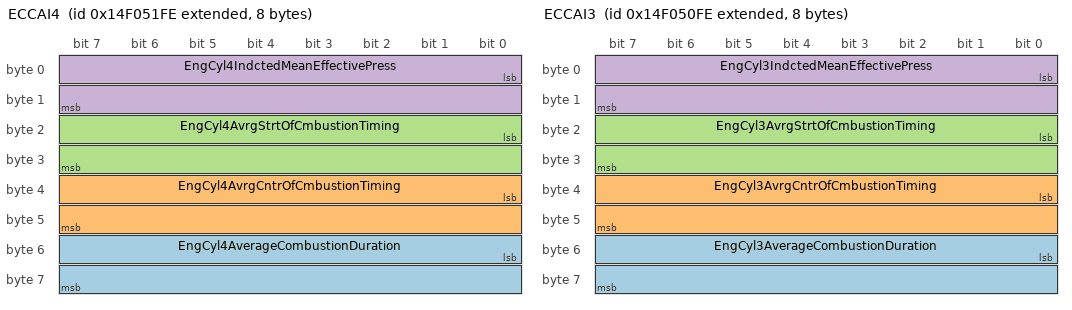
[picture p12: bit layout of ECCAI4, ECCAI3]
BO_ 2498777598 ECCAI4: 8 Vector__XXX
 SG_ EngCyl4AverageCombustionDuration : 48|16@1+ (0.0078125,0) [0|501.9921875] "deg" Vector__XXX
 SG_ EngCyl4AvrgCntrOfCmbustionTiming : 32|16@1+ (0.0078125,-250) [-250|251.9921875] "deg" Vector__XXX
 SG_ EngCyl4AvrgStrtOfCmbustionTiming : 16|16@1+ (0.0078125,-250) [-250|251.9921875] "deg" Vector__XXX
 SG_ EngCyl4IndctedMeanEffectivePress : 0|16@1+ (0.0001220703125,-1) [-1|6.8436279296875] "MPa" Vector__XXX

BO_ 2498777342 ECCAI3: 8 Vector__XXX
 SG_ EngCyl3AverageCombustionDuration : 48|16@1+ (0.0078125,0) [0|501.9921875] "deg" Vector__XXX
 SG_ EngCyl3AvrgCntrOfCmbustionTiming : 32|16@1+ (0.0078125,-250) [-250|251.9921875] "deg" Vector__XXX
 SG_ EngCyl3AvrgStrtOfCmbustionTiming : 16|16@1+ (0.0078125,-250) [-250|251.9921875] "deg" Vector__XXX
 SG_ EngCyl3IndctedMeanEffectivePress : 0|16@1+ (0.0001220703125,-1) [-1|6.8436279296875] "MPa" Vector__XXX

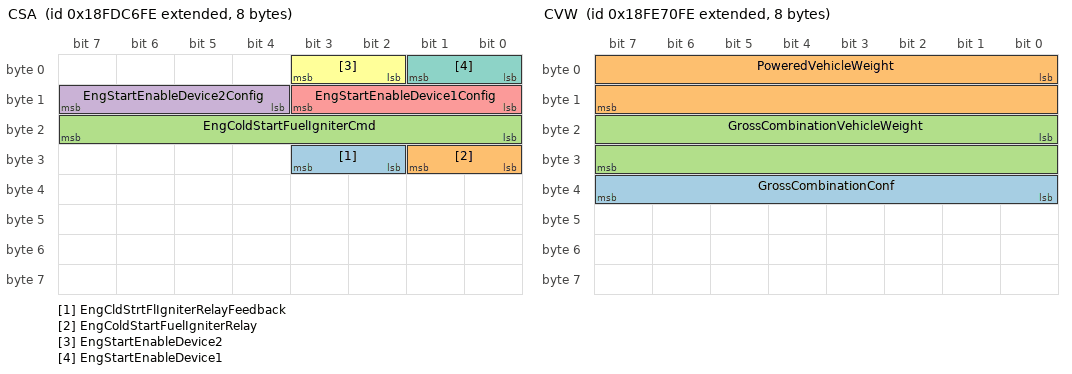
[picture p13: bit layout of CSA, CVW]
BO_ 2566768382 CSA: 8 Vector__XXX
 SG_ EngCldStrtFlIgniterRelayFeedback : 26|2@1+ (1,0) [0|3] "" Vector__XXX
 SG_ EngColdStartFuelIgniterRelay : 24|2@1+ (1,0) [0|3] "" Vector__XXX
 SG_ EngColdStartFuelIgniterCmd : 16|8@1+ (0.4,0) [0|100] "%" Vector__XXX
 SG_ EngStartEnableDevice2Config : 12|4@1+ (1,0) [0|15] "" Vector__XXX
 SG_ EngStartEnableDevice1Config : 8|4@1+ (1,0) [0|15] "" Vector__XXX
 SG_ EngStartEnableDevice2 : 2|2@1+ (1,0) [0|3] "" Vector__XXX
 SG_ EngStartEnableDevice1 : 0|2@1+ (1,0) [0|3] "" Vector__XXX

BO_ 2566811902 CVW: 8 Vector__XXX
 SG_ GrossCombinationConf : 32|8@1+ (0.5,0) [0|100] "%" Vector__XXX
 SG_ PoweredVehicleWeight : 0|16@1+ (10,0) [0|642550] "kg" Vector__XXX
 SG_ GrossCombinationVehicleWeight : 16|16@1+ (10,0) [0|642550] "kg" Vector__XXX

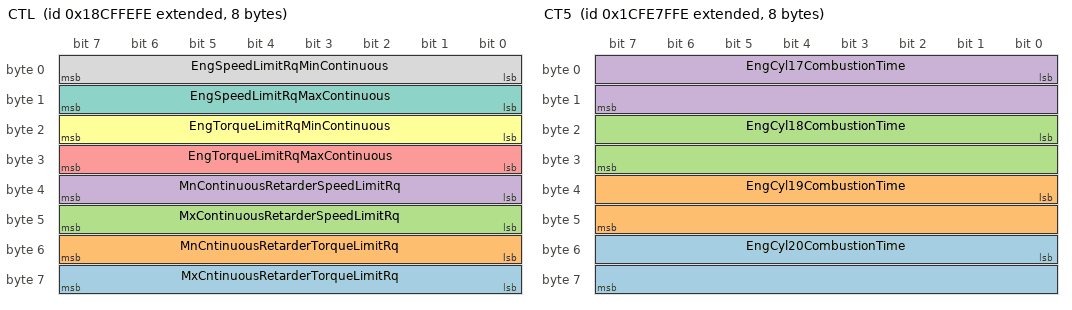
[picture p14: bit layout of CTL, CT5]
BO_ 2563768062 CTL: 8 Vector__XXX
 SG_ MxCntinuousRetarderTorqueLimitRq : 56|8@1+ (1,-125) [-125|0] "%" Vector__XXX
 SG_ MnCntinuousRetarderTorqueLimitRq : 48|8@1+ (1,-125) [-125|0] "%" Vector__XXX
 SG_ MxContinuousRetarderSpeedLimitRq : 40|8@1+ (32,0) [0|8000] "rpm" Vector__XXX
 SG_ MnContinuousRetarderSpeedLimitRq : 32|8@1+ (32,0) [0|8000] "rpm" Vector__XXX
 SG_ EngTorqueLimitRqMaxContinuous : 24|8@1+ (1,-125) [0|125] "%" Vector__XXX
 SG_ EngTorqueLimitRqMinContinuous : 16|8@1+ (1,-125) [0|125] "%" Vector__XXX
 SG_ EngSpeedLimitRqMaxContinuous : 8|8@1+ (32,0) [0|8000] "rpm" Vector__XXX
 SG_ EngSpeedLimitRqMinContinuous : 0|8@1+ (32,0) [0|8000] "rpm" Vector__XXX

BO_ 2633924862 CT6: 8 Vector__XXX
 SG_ EngAverageCombustionTime : 16|16@1+ (0.01,0) [0|642.55] "ms" Vector__XXX
 SG_ EngDesiredCombustionTime : 0|16@1+ (0.01,0) [0|642.55] "ms" Vector__XXX

BO_ 2633924606 CT5: 8 Vector__XXX
 SG_ EngCyl20CombustionTime : 48|16@1+ (0.01,0) [0|642.55] "ms" Vector__XXX
 SG_ EngCyl19CombustionTime : 32|16@1+ (0.01,0) [0|642.55] "ms" Vector__XXX
 SG_ EngCyl18CombustionTime : 16|16@1+ (0.01,0) [0|642.55] "ms" Vector__XXX
 SG_ EngCyl17CombustionTime : 0|16@1+ (0.01,0) [0|642.55] "ms" Vector__XXX

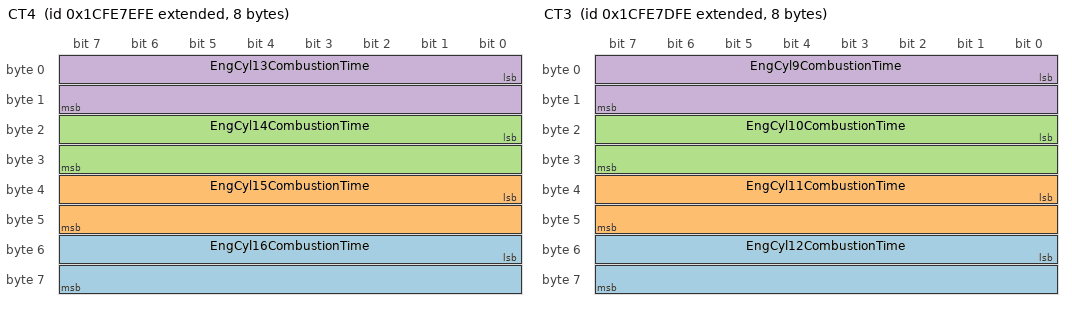
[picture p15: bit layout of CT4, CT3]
BO_ 2633924350 CT4: 8 Vector__XXX
 SG_ EngCyl16CombustionTime : 48|16@1+ (0.01,0) [0|642.55] "ms" Vector__XXX
 SG_ EngCyl15CombustionTime : 32|16@1+ (0.01,0) [0|642.55] "ms" Vector__XXX
 SG_ EngCyl14CombustionTime : 16|16@1+ (0.01,0) [0|642.55] "ms" Vector__XXX
 SG_ EngCyl13CombustionTime : 0|16@1+ (0.01,0) [0|642.55] "ms" Vector__XXX

BO_ 2633924094 CT3: 8 Vector__XXX
 SG_ EngCyl12CombustionTime : 48|16@1+ (0.01,0) [0|642.55] "ms" Vector__XXX
 SG_ EngCyl11CombustionTime : 32|16@1+ (0.01,0) [0|642.55] "ms" Vector__XXX
 SG_ EngCyl10CombustionTime : 16|16@1+ (0.01,0) [0|642.55] "ms" Vector__XXX
 SG_ EngCyl9CombustionTime : 0|16@1+ (0.01,0) [0|642.55] "ms" Vector__XXX

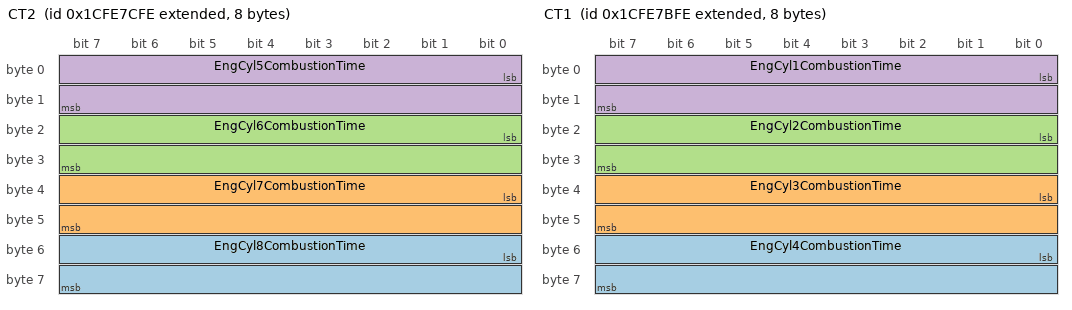
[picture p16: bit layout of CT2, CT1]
BO_ 2633923838 CT2: 8 Vector__XXX
 SG_ EngCyl8CombustionTime : 48|16@1+ (0.01,0) [0|642.55] "ms" Vector__XXX
 SG_ EngCyl7CombustionTime : 32|16@1+ (0.01,0) [0|642.55] "ms" Vector__XXX
 SG_ EngCyl6CombustionTime : 16|16@1+ (0.01,0) [0|642.55] "ms" Vector__XXX
 SG_ EngCyl5CombustionTime : 0|16@1+ (0.01,0) [0|642.55] "ms" Vector__XXX

BO_ 2633923582 CT1: 8 Vector__XXX
 SG_ EngCyl4CombustionTime : 48|16@1+ (0.01,0) [0|642.55] "ms" Vector__XXX
 SG_ EngCyl3CombustionTime : 32|16@1+ (0.01,0) [0|642.55] "ms" Vector__XXX
 SG_ EngCyl2CombustionTime : 16|16@1+ (0.01,0) [0|642.55] "ms" Vector__XXX
 SG_ EngCyl1CombustionTime : 0|16@1+ (0.01,0) [0|642.55] "ms" Vector__XXX

BO_ 2633878014 CMI: 8 Vector__XXX
 SG_ TotalCountOfConfigChangesMade : 0|16@1+ (1,0) [0|64255] "" Vector__XXX

BO_ 2566771966 CM3: 8 Vector__XXX
 SG_ RemoteKeyFobFunctionReq : 40|5@1+ (1,0) [0|31] "" Vector__XXX
 SG_ OpKeySwOff : 34|2@1+ (1,0) [0|3] "" Vector__XXX
 SG_ OpKeySwSvc : 32|2@1+ (1,0) [0|3] "" Vector__XXX
 SG_ EngAirShutoffManualSw : 30|2@1+ (1,0) [0|3] "" Vector__XXX
 SG_ EngAirShutoffTestSw : 28|2@1+ (1,0) [0|3] "" Vector__XXX
 SG_ HornSw : 26|2@1+ (1,0) [0|3] "" Vector__XXX
 SG_ OpKeySwDelayedBatOff : 24|2@1+ (1,0) [0|3] "" Vector__XXX
 SG_ OpKeySwStart : 22|2@1+ (1,0) [0|3] "" Vector__XXX
 SG_ OpKeySwIgntPwr : 20|2@1+ (1,0) [0|3] "" Vector__XXX
 SG_ OpKeySwAccessoryPwr : 18|2@1+ (1,0) [0|3] "" Vector__XXX
 SG_ OpKeyDetected : 14|2@1+ (1,0) [0|3] "" Vector__XXX
 SG_ MomentaryOpKeySw : 6|2@1+ (1,0) [0|3] "" Vector__XXX
 SG_ AFTSCRDosingModeCmd : 3|3@1+ (1,0) [0|7] "" Vector__XXX
 SG_ VehTrailerStatus : 12|2@1+ (1,0) [0|3] "" Vector__XXX
 SG_ TransOilLevelRq : 16|2@1+ (1,0) [0|3] "" Vector__XXX
 SG_ FifthWheelReleaseCtrl : 8|2@1+ (1,0) [0|3] "" Vector__XXX
 SG_ FfthWhlRleaseCtrlSecurityLockout : 10|2@1+ (1,0) [0|3] "" Vector__XXX
 SG_ TransferCaseSelectorSwitch : 0|3@1+ (1,0) [0|7] "" Vector__XXX

BO_ 2564882174 CM1: 8 Vector__XXX
 SG_ SelectedMaxVehicleSpeedLimit : 56|8@1+ (1,0) [0|250] "" Vector__XXX
 SG_ RqCabZoneHeating : 54|2@1+ (1,0) [0|3] "" Vector__XXX
 SG_ RqEngZoneHeating : 52|2@1+ (1,0) [0|3] "" Vector__XXX
 SG_ AuxHeaterModeRq : 48|4@1+ (1,0) [0|15] "" Vector__XXX
 SG_ EngAutomaticStartEnableSwitch : 46|2@1+ (1,0) [0|3] "" Vector__XXX
 SG_ AtomaticGearShiftingEnableSwitch : 44|2@1+ (1,0) [0|3] "" Vector__XXX
 SG_ AFTRegenForceSw : 42|2@1+ (1,0) [0|3] "" Vector__XXX
 SG_ AFTRegenInhSw : 40|2@1+ (1,0) [0|3] "" Vector__XXX
 SG_ VhclLmtngSpdGovernorEnableSwitch : 38|2@1+ (1,0) [0|3] "" Vector__XXX
 SG_ VhclLmtngSpdGvrnrIncrementSwitch : 36|2@1+ (1,0) [0|3] "" Vector__XXX
 SG_ VhclLmtngSpdGvrnrDecrementSwitch : 34|2@1+ (1,0) [0|3] "" Vector__XXX
 SG_ ParkBrakeCmd : 32|2@1+ (1,0) [0|3] "" Vector__XXX
 SG_ SeatBeltSwitch : 30|2@1+ (1,0) [0|3] "" Vector__XXX
 SG_ OperatorSeatDirectionSwitch : 28|2@1+ (1,0) [0|3] "" Vector__XXX
 SG_ BatteryMainSwitchHoldRq : 26|2@1+ (1,0) [0|3] "" Vector__XXX
 SG_ AuxHeaterCoolantPumpRq : 24|2@1+ (1,0) [0|3] "" Vector__XXX
 SG_ CabInteriorTempCmd : 8|16@1+ (0.03125,-273) [-273|1734.96875] "°C" Vector__XXX
 SG_ RequestedPercentFanSpeed : 0|8@1+ (0.4,0) [0|100] "%" Vector__XXX

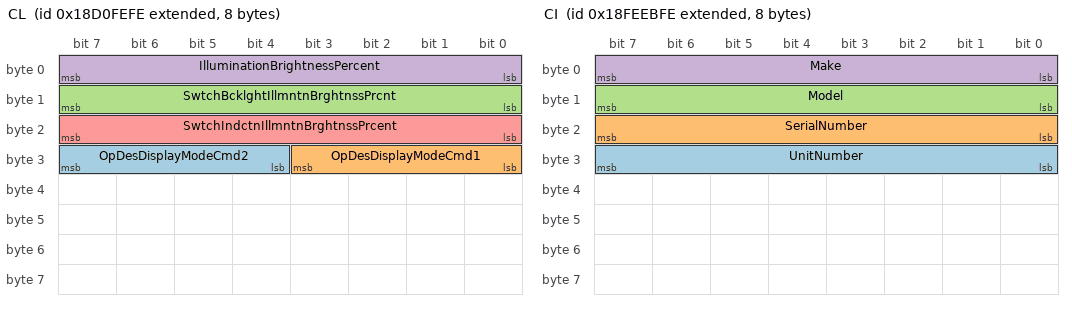
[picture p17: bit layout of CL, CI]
BO_ 2563833598 CL: 8 Vector__XXX
 SG_ OpDesDisplayModeCmd2 : 28|4@1+ (1,0) [0|15] "" Vector__XXX
 SG_ OpDesDisplayModeCmd1 : 24|4@1+ (1,0) [0|15] "" Vector__XXX
 SG_ SwtchBcklghtIllmntnBrghtnssPrcnt : 8|8@1+ (0.4,0) [0|100] "%" Vector__XXX
 SG_ IlluminationBrightnessPercent : 0|8@1+ (0.4,0) [0|100] "%" Vector__XXX
 SG_ SwtchIndctnIllmntnBrghtnssPrcent : 16|8@1+ (0.4,0) [0|100] "%" Vector__XXX

BO_ 2566843390 CI: 8 Vector__XXX
 SG_ UnitNumber : 24|8@1+ (1,0) [0|255] "" Vector__XXX
 SG_ SerialNumber : 16|8@1+ (1,0) [0|255] "" Vector__XXX
 SG_ Model : 8|8@1+ (1,0) [0|255] "" Vector__XXX
 SG_ Make : 0|8@1+ (1,0) [0|255] "" Vector__XXX

BO_ 2566844926 CCVS1: 8 Vector__XXX
 SG_ EngShutdownOverrideSwitch : 62|2@1+ (1,0) [0|3] "" Vector__XXX
 SG_ EngTestModeSwitch : 60|2@1+ (1,0) [0|3] "" Vector__XXX
 SG_ EngIdleDecrementSwitch : 58|2@1+ (1,0) [0|3] "" Vector__XXX
 SG_ EngIdleIncrementSwitch : 56|2@1+ (1,0) [0|3] "" Vector__XXX
 SG_ CruiseCtrlStates : 53|3@1+ (1,0) [0|7] "" Vector__XXX
 SG_ PTOGovernorState : 48|5@1+ (1,0) [0|31] "" Vector__XXX
 SG_ CruiseCtrlSetSpeed : 40|8@1+ (1,0) [0|250] "km/h" Vector__XXX
 SG_ CruiseCtrlAccelerateSwitch : 38|2@1+ (1,0) [0|3] "" Vector__XXX
 SG_ CruiseCtrlResumeSwitch : 36|2@1+ (1,0) [0|3] "" Vector__XXX
 SG_ CruiseCtrlCoastSwitch : 34|2@1+ (1,0) [0|3] "" Vector__XXX
 SG_ CruiseCtrlSetSwitch : 32|2@1+ (1,0) [0|3] "" Vector__XXX
 SG_ ClutchSwitch : 30|2@1+ (1,0) [0|3] "" Vector__XXX
 SG_ BrakeSwitch : 28|2@1+ (1,0) [0|3] "" Vector__XXX
 SG_ CruiseCtrlEnableSwitch : 26|2@1+ (1,0) [0|3] "" Vector__XXX
 SG_ CruiseCtrlActive : 24|2@1+ (1,0) [0|3] "" Vector__XXX
 SG_ WheelBasedVehicleSpeed : 8|16@1+ (0.00390625,0) [0|250.99609375] "km/h" Vector__XXX
 SG_ ParkBrakeReleaseInhibitRq : 6|2@1+ (1,0) [0|3] "" Vector__XXX
 SG_ CruiseCtrlPauseSwitch : 4|2@1+ (1,0) [0|3] "" Vector__XXX
 SG_ ParkingBrakeSwitch : 2|2@1+ (1,0) [0|3] "" Vector__XXX
 SG_ TwoSpeedAxleSwitch : 0|2@1+ (1,0) [0|3] "" Vector__XXX

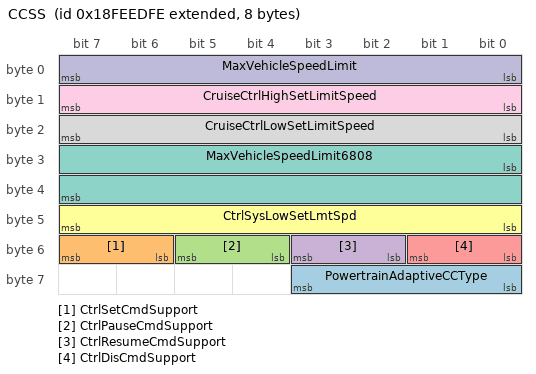
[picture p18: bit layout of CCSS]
BO_ 2566843902 CCSS: 8 Vector__XXX
 SG_ PowertrainAdaptiveCCType : 56|4@1+ (1,0) [0|15] "" Vector__XXX
 SG_ CtrlSetCmdSupport : 54|2@1+ (1,0) [0|3] "" Vector__XXX
 SG_ CtrlPauseCmdSupport : 52|2@1+ (1,0) [0|3] "" Vector__XXX
 SG_ CtrlResumeCmdSupport : 50|2@1+ (1,0) [0|3] "" Vector__XXX
 SG_ CtrlDisCmdSupport : 48|2@1+ (1,0) [0|3] "" Vector__XXX
 SG_ CtrlSysLowSetLmtSpd : 40|8@1+ (1,0) [0|250] "km/h" Vector__XXX
 SG_ MaxVehicleSpeedLimit6808 : 24|16@1+ (0.00390625,0) [0|250.99609375] "km/h" Vector__XXX
 SG_ CruiseCtrlLowSetLimitSpeed : 16|8@1+ (1,0) [0|250] "km/h" Vector__XXX
 SG_ CruiseCtrlHighSetLimitSpeed : 8|8@1+ (1,0) [0|250] "km/h" Vector__XXX
 SG_ MaxVehicleSpeedLimit : 0|8@1+ (1,0) [0|250] "km/h" Vector__XXX

BO_ 2566809598 CCC: 8 Vector__XXX
 SG_ AuxHeaterMaxOutputPower : 0|16@1+ (2,0) [0|128510] "W" Vector__XXX

BO_ 2633940222 CBI: 16 Vector__XXX
 SG_ TripServiceBrakeApplications : 96|32@1+ (1,0) [0|4211081215] "" Vector__XXX
 SG_ TripServiceBrakeDistance : 64|32@1+ (0.125,0) [0|526385151.875] "km" Vector__XXX
 SG_ TripCompressionBrakeDistance : 32|32@1+ (0.125,0) [0|526385151.875] "km" Vector__XXX
 SG_ TotalCompressionBrakeDistance : 0|32@1+ (0.125,0) [0|526385151.875] "km" Vector__XXX

CM_ BO_ 2365446142 "Extended Joystick Message 1
Used to transfer information about the measured status of three additional axes of a joystick and switches of the joystick grip or handle.  The joystick axial motion information is available in the Basic Joystick ...";
CM_ SG_ 2365446142 Joystick1Button13PressedStatus "Reports when the joystick button has been pressed.

00b = Button not pressed
01b = Button pressed
10b = Error Indicator
11b = Not Available";
CM_ SG_ 2365446142 Joystick1Button14PressedStatus "Reports when the joystick button has been pressed.

00b = Button not pressed
01b = Button pressed
10b = Error Indicator
11b = Not Available";
CM_ SG_ 2365446142 Joystick1Button15PressedStatus "Reports when the joystick button has been pressed.

00b = Button not pressed
01b = Button pressed
10b = Error Indicator
11b = Not Available";
CM_ SG_ 2365446142 Joystick1Button16PressedStatus "Reports when the joystick button has been pressed.

00b = Button not pressed
01b = Button pressed
10b = Error Indicator
11b = Not Available";
CM_ SG_ 2365446142 Jystick1GripXAxisDetentPosStatus "Reports when the current joystick grip position is in the detent position for that axis of travel.

00b = Not in the Detent Position
01b = In the Detent Position
10b = Error Indicator
11b = Not Available";
CM_ SG_ 2365446142 Jystick1GripYAxisDetentPosStatus "Reports when the current joystick grip position is in the detent position for that axis of travel.

00b = Not in the Detent Position
01b = In the Detent Position
10b = Error Indicator
11b = Not Available";
CM_ SG_ 2365446142 Jystick1ThetaAxisDetentPosStatus "Reports when the current joystick position is in the detent position for that axis of travel.

00b = Not in the Detent Position
01b = In the Detent Position
10b = Error Indicator
11b = Not Available";
CM_ SG_ 2365446142 Joystick1ThetaAxisPos "The position of the joystick in the relative motion of travel from the neutral position.  Position value of 0 is Neutral and position value 1000 (100%) is the end of linear zone.  Value of 1022 indicates an error has occurred.";
CM_ SG_ 2365446142 Jystck1ThtAxsClckwsPstvPosStatus "Reports when the current joystick position is on the positive travel side (forward, right, clockwise, up) relative to the neutral position for that axis of travel.
00b = Not on Positive side of Neutral
01b = On positive side of Neutral
10b = ...";
CM_ SG_ 2365446142 Jystck1ThetaAxisNeutralPosStatus "Reports when the current joystick position is in the neutral position for that axis of travel.  The neutral position measurement must be determined from some mechanism other than the axis position measurement device.
00b = Not in Neutral Position
 ...";
CM_ SG_ 2365446142 Joystick1GripYAxisPos "The position of the joystick grip in the relative motion of travel from the neutral position.  Position value of 0 is Neutral and position value 1000 (100%) is the end of linear zone.  Value of 1022 indicates an error has occurred.";
CM_ SG_ 2365446142 Jystck1GrpYAxsLvrFrwrdPstvPsStts "Reports when the current joystick grip position is on the positive travel side (forward, right, clockwise, up) relative to the neutral position for that axis of travel.
00b = Not on Positive side of Neutral
01b = On positive side of Neutral
10b = ...";
CM_ SG_ 2365446142 Jystck1GrpYAxsLvrBckNgtvPsStatus "Reports when the current joystick grip position is on the negative travel side (back, left, counterclockwise, down) relative to the neutral position for that axis of travel.
00b = Not on negative side of Neutral
01b = On negative side of Neutral
 ...";
CM_ SG_ 2365446142 Aftrtrtmnt1DslExhstFldPrprtsPrlm "Reports when the current joystick grip position is in the neutral position for that axis of travel.  The neutral position measurement must be determined from some mechanism other than the axis position measurement device.
00b = Not in Neutral ...";
CM_ SG_ 2365446142 Joystick1GripXAxisPos "The position of the joystick grip in the relative motion of travel from the neutral position.  Position value of 0 is Neutral and position value 1000 (100%) is the end of linear zone.  Value of 1022 indicates an error has occurred.";
CM_ SG_ 2365446142 Jystck1GrpXAxsLvrRghtPstvPsSttus "Reports when the current joystick grip position is on the positive travel side (forward, right, clockwise, up) relative to the neutral position for that axis of travel.
00b = Not on Positive side of Neutral
01b = On positive side of Neutral
10b = ...";
CM_ SG_ 2365446142 Jystck1GrpXAxsLvrLftNgtvPsStatus "Reports when the current joystick grip position is on the negative travel side (back, left, counterclockwise, down) relative to the neutral position for that axis of travel.
00b = Not on negative side of Neutral
01b = On negative side of Neutral
 ...";
CM_ SG_ 2365446142 Jystck1GripXAxisNeutralPosStatus "Reports when the current joystick grip position is in the neutral position for that axis of travel.  The neutral position measurement must be determined from some mechanism other than the axis position measurement device.
00b = Not in Neutral ...";
CM_ SG_ 2365446142 Jystck1ThtAxsCntrClckwsNgtvPsStt "Reports when the current joystick position is on the negative travel side (back, left, counterclockwise, down) relative to the neutral position for that axis of travel.
00b = Not on negative side of Neutral
01b = On negative side of Neutral
10b = ...";
CM_ BO_ 2633929470 "Engine Information 1";
CM_ SG_ 2633929470 EngFuelRackPos "Measured position of the engine fuel rack.  A value of 0% rack represents no fueling and a value of 100% rack represents maximum fueling.";
CM_ SG_ 2633929470 EngGasMassFlowRate1 "Gas mass flow rate delivered to an engine through its first fuel control system.  See SPN 3467 for the second fuel control system.";
CM_ SG_ 2633929470 InstantaneousEstBrakePower "Estimate of the power developed by the engine.";
CM_ SG_ 2633929470 EngExhaustGasPress1 "Gage pressure of the exhaust gases as measured at the turbine intake of the turbocharger. This SP to be used for inline engines or exhaust bank 1 of multiple bank engines.  See SPN 5749 for exhaust bank 2 and See SPN 6384 for alternate range and ...";
CM_ SG_ 2633929470 EngPrefilterOilPress "Gage pressure of the engine oil before the oil reaches the oil filter.   See SPN 7470 for alternate resolution.";
CM_ BO_ 2633937406 "ECU History";
CM_ SG_ 2633937406 TotalECURunTime "Total time accumulated over the life of the ECU, from ignition switch ON to ignition switch OFF.  When the ECU is replaced this value shall be reset.";
CM_ SG_ 2633937406 TotalECUDistance "Total distance accumulated over the life of the ECU.  When the ECU is replaced this value shall be reset.";
CM_ BO_ 2364541694 "Engine Gas Flow Rate
Flow rates of Air and mixed gasses into the engine cylinders.";
CM_ SG_ 2364541694 TargetFreshAirMassFlow "The intended mass flow rate of fresh air entering the engine air intake, before any EGR mixer, if used.";
CM_ SG_ 2364541694 EngExhstGsRcrcltion2MassFlowRate "Flow rate of gas through the second EGR system. Flow rate of the exhaust gas being recirculated from the 2nd EGR system into combustion air.";
CM_ SG_ 2364541694 EngIntakeAirMassFlowRate "Mass flow rate of fresh air entering the engine air intake, before any EGR mixer, if used.  Flow rate of fresh air conducted to the engine cylinders to support combustion.";
CM_ SG_ 2364541694 EngExhstGsRcrcltion1MassFlowRate "Flow rate of gas through the EGR system. Flow rate of the exhaust gas being recirculated into the combustion air.";
CM_ BO_ 2566810366 "Engine Fuel/Lube Systems";
CM_ SG_ 2566810366 FuelPrimingSt "Determination of whether or not the engine fuel system is (or has recently been) sufficiently primed with fuel for starting purposes.
00b = Not sufficiently primed
01b = Sufficiently primed
10b = Unable to determine if sufficiently primed
11b = ...";
CM_ SG_ 2566810366 EngFuelSupplyPumpIntakePress "Gage pressure of fuel at the fuel supply pump intake.  See Figures SPN16_A & SPN16_B.

See also SPN 1381.";
CM_ SG_ 2566810366 FuelPumpPrimerStatus "Parameter used to transmit the actual status of the fuel priming system.  The fuel priming system is a system that purges air in the fuel lines and may assist fuel delivery to a second pump at lower speeds.
00b = Off
01b = On
10b = Error
11b = ...";
CM_ SG_ 2566810366 EngVentilationStatus "Engine ventilation control states.
000b = Sufficiently vented (all combustible gases have been evacuated from intake and exhaust systems)
001b = Ventilation needed (combustible gases may be present in intake and exhaust systems)
010b = ...";
CM_ SG_ 2566810366 EngCoolantPreheatedState "Indicates whether the engine coolant is pre-heated sufficiently for starting purposes.
00b = Not sufficiently pre-heated
01b = Sufficiently pre-heated
10b = Unable to determine  engine coolant pre-heated sufficiently
11b = Not available or not ...";
CM_ SG_ 2566810366 EngOilPreHeatedState "Indicates whether the engine oil pre-heated sufficiently for starting purposes.
00b = Not sufficiently pre-heated
01b = Sufficiently pre-heated
10b = Unable to determine if engine oil is pre-heated sufficiently
11b = Not available or not ...";
CM_ SG_ 2566810366 EngOilPrimingState "Determination of whether or not the engine is (or has recently been) sufficiently lubricated for starting purposes.
00b = Not sufficiently lubricated
01b = Sufficiently lubricated
10b = Unable to determine if sufficiently lubricated
11b = Not ...";
CM_ SG_ 2566810366 EngOilPrimingPumpSwitch "Switch input for activating the engine oil priming pump.

00b = Off
01b = On
10b = Error
11b = Not available or not installed";
CM_ SG_ 2566810366 EngOilFilterOutletPress "Oil pressure (gage) measured just downstream of oil filter.Used in conjunction with SPN1208 (pre-filter oil pressure) to determine oil filter health.";
CM_ SG_ 2566810366 EngWasteOilReservoirLevel "Level of crankcase blowby emulsion collected by a container.  Normalized to percent, 0% represents completely empty and 100% represents completely full.";
CM_ SG_ 2566810366 EngFuelFilterDiffPress "Differential pressure measured across the fuel filter located between the fuel tank and the supply pump.  See Figures SPN16_A and SPN16_B.
See SPN 22745 (Engine Fuel Filter (suction side) Differential Pressure (High Resolution) for alternate ...";
CM_ SG_ 2566810366 EngFuelSupplyPumpIntakeAbsPress "Absolute pressure of fuel at the fuel supply pump intake.  See Figures SPN16_A & SPN16_B.  See SPN 7472 for alternate resolution.";
CM_ SG_ 2566810366 EngOilLevelRemoteReservoir "Ratio of current volume of engine oil in a remote reservoir to the maximum required volume.  If a single switch (on/off) is used, 20% and 100% respectively will be used where 100% means no oil needs to be added and 20% means oil needs to be added ...";
CM_ BO_ 2566767102 "Engine Fluid Level/Pressure 3
3rd PG which identifies parameters that are either measuring various pressures within the engine or identifying engine fluid levels";
CM_ SG_ 2566767102 EngThrottleValve1DiffPress "The differential pressure between the intake and outlet of the throttle valve 1 (SPN 51).  The differential pressure is measured from the intake with respect to the outlet of the throttle valve.";
CM_ SG_ 2566767102 EngExhstGsRcrclation1OutletPress "EGR outlet pressure is measured immediately after the EGR valve.";
CM_ SG_ 2566767102 EngExhstVlvActtionSystemOilPress "The absolute pressure of the oil in the hydraulic system that powers the engine exhaust valve actuation system";
CM_ SG_ 2566767102 EngExhstGsRcrclation1IntakePress "EGR intake gage pressure is measured after the EGR cooler and before the EGR valve.";
CM_ SG_ 2566767102 EngIntkVlvActationSystemOilPress "The gage pressure of the oil in the hydraulic system that powers the engine intake valve actuation system";
CM_ BO_ 2566839294 "Engine Fluid Level/Pressure 2
2nd PG which identifies parameters that are either measuring various pressures within the engine or identifying engine fluid levels";
CM_ SG_ 2566839294 EngInjectorMeteringRail2Press "The gage pressure of fuel in the metering rail #2 as delivered from the supply pump to the injector metering intake.  See Figure SPN16_A for fuel system related parameters.  Although the figure does not show rail #2 it does show the relationship of ...";
CM_ SG_ 2566839294 EngInjectorTimingRail1Press "The gage pressure of fuel in the timing rail delivered from the supply pump to the injector timing intake.";
CM_ SG_ 2566839294 EngInjectorMeteringRail1Press "The gage pressure of fuel in the primary, or first, metering rail as delivered from the supply pump to the injector metering intake.";
CM_ SG_ 2566839294 EngInjectionCtrlPress "The gage pressure of the engine oil in the hydraulic accumulator that powers an intensifier used for fuel injection.";
CM_ BO_ 2566844414 "Engine Fluid Level/Pressure 1
PG which identifies parameters that are either measuring various pressures within the engine or identifying engine fluid levels";
CM_ SG_ 2566844414 EngCoolantLevel "Ratio of volume of liquid found in engine cooling system to total cooling system volume.  Typical monitoring location is in the coolant expansion tank.";
CM_ SG_ 2566844414 EngCoolantPress "Gage pressure of liquid found in engine cooling system.

See SPN 20 for alternate range and resolution.";
CM_ SG_ 2566844414 EngCrankcasePress "First instance of the gage pressure inside engine crankcase.";
CM_ SG_ 2566844414 EngOilPress "Gage pressure of oil in engine lubrication system as provided by oil pump.  See SPN 7468 for alternate resolution.";
CM_ SG_ 2566844414 EngOilLevel "Ratio of current volume of engine sump oil to maximum required volume.";
CM_ SG_ 2566844414 EngExCrankcaseBlowbyPress "Differential crankcase blow-by pressure as measured through a tube with a venturi. 

(SPN 1264 is not to be used - obsolete)";
CM_ SG_ 2566844414 EngFuelDeliveryPress "Gage pressure of fuel in system as delivered from supply pump to the injection pump.  See SPN 7469 for alternate resolution.

See also SPN 5578 for Fuel Delivery Absolute Pressure.";
CM_ BO_ 2633929726 "Engine Electrical System/Module Information";
CM_ SG_ 2633929726 SafetyWireStatus "Status signal which indicates that the safety wire has been activated.  When the safety wire is activated, the engine will not operate.  This is used for maintenance purposes.
00b = Safety wire has not been activated
01b = Safety wire has been ...";
CM_ SG_ 2633929726 ElectricalLoad "Electrical power delivered by the engine to the electrical system connected to the generator.";
CM_ BO_ 2566772222 "Electronic Engine Controller 5
Engine related parameters";
CM_ SG_ 2566772222 EngVrblGeometryTurbo1ActuatorPos "Sensor that measures the position of the variable geometry turbocharger actuator.  A  position of 0% indicates the actuator is in the position creating the smallest geometry turbocharger. A position of 100% represents the largest geometry ...";
CM_ SG_ 2566772222 EngVriableGeometryTurbo1CtrlMode "Indicates if the variable geometry turbocharger control status is either open loop or closed loop.

00b = open loop
01b = closed loop
10b = SAE reserved
11b = not available";
CM_ SG_ 2566772222 EngFuelCtrlCtrlMode "Indicates whether the Engine Fuel Control System is in open loop or closed loop.

00b = Open loop
01b = Closed loop
10b = SAE reserved
11b = Not available";
CM_ SG_ 2566772222 EngVrblGmtryTrbArCtrlShtoffValve "Isolates vehicle brake air from the Variable Geometry Turbocharger (VGT) system when engine is not running.  This valve prevents vehicle air from bleeding off through the VGT Control Valve when engine is not in use.  Primary vehicle air system from ...";
CM_ SG_ 2566772222 EngExhstGsRcirculation1ValveCtrl "Desired percentage of maximum Exhaust Gas Recirculation (EGR) valve 1 opening.  0% means valve is closed. 100% means maximum valve opening (full gas flow).";
CM_ SG_ 2566772222 EngTrb1ClclatedTurbineOutletTemp "Calculated value of turbocharger compressor outlet air temperature.  Temperature of air exiting the turbocharger compressor and before entering charge air cooler.  The estimate is based on turbo speed and measured turbocharger compressor intake ...";
CM_ SG_ 2566772222 EngTrb1ClclatedTurbineIntakeTemp "Calculated value of turbine intake temperature based on engine operating conditions, such as intake manifold temperature, charge fuel ratio, injection timing, and engine speed.  Use SPN 1180 for actual measured intake temperature.";
CM_ BO_ 2633940734 "Electronic Engine Controller 4";
CM_ SG_ 2633940734 PrelubeOilLowPressThreshold "The minimum value that the engine oil pressure (SPN 100 and SPN 7468) must exceed in order to start the engine.

This parameter is intended for applications that have an external means of lubricating the engine before starting the engine.";
CM_ SG_ 2633940734 CrnkAttmptCntOnPrsntStartAttempt "Reports the number of cranking cycles undergone during the present start attempt.
Note:  This is intended to be used in conjunction with Maximum Crank Attempts per Start Attempt, in order to give a FMI 0 diagnostic on this parameter when the count ...";
CM_ SG_ 2633940734 EngIntakeManifoldPressCtrlMode "Indicates that the Boost Pressure Closed Loop Control status either open loop or closed loop.

00b = Open loop 
01b = Closed loop 
10b = SAE reserved
11b = Not available";
CM_ SG_ 2633940734 EngRotationDirection "Direction of engine rotation, as reported by the engine.  Direction convention as viewed by an observer standing at the rear of the engine, viewing the flywheel.
00b = CounterClockWise (CCW)
01b = ClockWise (CW)
10b = Unknown  (Rotation Direction ...";
CM_ SG_ 2633940734 EngRatedSpeed "The maximum governed rotational velocity of the engine crankshaft under full load conditions.  Note that the engine speed at point 2 (SPN 528) is equal to rated engine speed only in the case when the engine has not been derated.  Please also ...";
CM_ SG_ 2633940734 EngRatedPower "Net brake power that the engine will deliver continuously, specified for a given application at a rated speed.";
CM_ BO_ 2566840318 "Electronic Engine Controller 3";
CM_ SG_ 2566840318 A2ExhDewPoint "Indicates that the temperature on the exhaust side of the aftertreatment has exceeded the dew point, as estimated by the ECU in exhaust bank 2.

00b = Not exceeded the dew point
01b = Exceeded the dew point
10b = Error
11b = Not available";
CM_ SG_ 2566840318 A2InDewPoint "Indicates that the temperature on the intake side of the aftertreatment system has exceeded the dew point, as estimated by the ECU in exhaust bank 2.

00b = Not exceeded the dew point
01b = Exceeded the dew point
10b = Error
11b = Not available";
CM_ SG_ 2566840318 A1ExhDewPoint "Indicates that the temperature on the exhaust side of the aftertreatment has exceeded the dew point, as estimated by the ECU in exhaust bank 1.

00b = Not exceeded the dew point
01b = Exceeded the dew point
10b = Error
11b = Not available";
CM_ SG_ 2566840318 A1InDewPoint "Indicates that the temperature on the intake side of the aftertreatment system has exceeded the dew point, as estimated by the ECU in exhaust bank 1.

00b = Not exceeded the dew point
01b = Exceeded the dew point
10b = Error
11b = Not available";
CM_ SG_ 2566840318 A1ExhGasMFR "Measured/calculated exhaust gas mass upstream of the aftertreatment system in exhaust bank 1 and 2.";
CM_ SG_ 2566840318 EstEngPrsiticLossesPercentTorque "The calculated torque that indicates the estimated amount of torque loss due to engine parasitics, such as cooling fan, air compressor, air conditioning, etc. It is expressed as a percent of Engine Reference Torque.
If there are multiple devices on ...";
CM_ SG_ 2566840318 EngnsDsrdOprtngSpdAsymmtryAdjstm "This byte is utilized in transmission gear selection routines and indicates the engine's preference of lower versus higher engine speeds should its desired speed not be achievable.  This is a scaled ratio such that 125 represents an equal preference ...";
CM_ SG_ 2566840318 EnginesDesiredOperatingSpeed "An indication by the engine of the optimal operating speed of the engine for the current existing conditions.  These conditions may include the torque generated to accommodate powertrain demands from the operator (via the accelerator pedal), cruise ...";
CM_ SG_ 2566840318 NominalFrictionPercentTorque "The calculated torque that indicates the amount of torque required by the basic engine itself added by the loss torque of accessories.  It contains the frictional and thermodynamic loss of the engine itself, pumping torque loss (SPN 5398), and the ...";
CM_ BO_ 2364539902 "Electronic Engine Controller 2
Identifies electronic engine control related parameters.";
CM_ SG_ 2364539902 EstPumpingPercentTorque "The calculated torque that indicates the estimated amount of torque loss due to the engine air handling system. The value transmitted in this parameter is included in SPN 514 (Nominal Friction - Percent Torque).  The data is transmitted as a percent ...";
CM_ SG_ 2364539902 ActlMaxAvailableEngPercentTorque "This is the maximum amount of torque that the engine can immediately deliver as a percentage of the reference engine torque (SPN 544).  The Actual Maximum Available Engine - Percent Torque shall take into consideration all engine torque derates ...";
CM_ SG_ 2364539902 SCRThermalManagementActive "Indicates that the exhaust temperatures have been elevated for regeneration of the SCR aftertreatment system or in preparation of regeneration of the SCR aftertreatment system.
00b = SCR Thermal Management is not active
01b = SCR Thermal ...";
CM_ SG_ 2364539902 DPFThermalManagementActive "Indicates that the exhaust temperatures have been elevated for regeneration of the diesel particulate filter aftertreatment system or in preparation of regeneration of the diesel particulate aftertreatment system.
00b = DPF Thermal Management is ...";
CM_ SG_ 2364539902 MmntaryEngMaxPowerEnableFeedback "Momentarily requesting Engine Maximum Power Enable - feature support feedback

00b = disabled
01b = supported 
10b = reserved
11b = don't care";
CM_ SG_ 2364539902 VhcleAccelerationRateLimitStatus "Status (active or not active) of the system used to limit maximum forward vehicle acceleration.
00b = Limit not active
01b = Limit active
10b = Reserved
11b = Not available
NOTE:  The effects of emission control limits, such as engine exhaust ...";
CM_ SG_ 2364539902 AccelPedalPos2 "The ratio of actual position of the second analog engine speed/torque request input device (such as an accelerator pedal or throttle lever) to the maximum position of the input device.  This parameter is intended for secondary accelerator control in ...";
CM_ SG_ 2364539902 RemoteAccelPedalPos "The ratio of actual position of the remote analog engine speed/torque request input device (such as an accelerator pedal or throttle lever) to the maximum position of the input device.
For example, in on-highway vehicles this could be an ...";
CM_ SG_ 2364539902 EngPercentLoadAtCurrentSpeed "The ratio of actual engine percent torque (indicated) to maximum indicated torque available at the current engine speed, clipped to zero torque during engine braking.";
CM_ SG_ 2364539902 AccelPedalPos1 "This parameter is intended for the primary accelerator control in an application. SPN 91 is the calculated ratio of actual position of the operator's [engine] speed request or [engine] torque request input device (most commonly an accelerator pedal ...";
CM_ SG_ 2364539902 AccelPedal2LowIdleSwitch "Switch signal which indicates the state of the accelerator pedal 2 low idle switch.  The low idle switch is defined in SAE J1843.
00b = Accelerator pedal 2 not in low idle condition
01b = Accelerator pedal 2 in low idle condition
10b = Error
11b ...";
CM_ SG_ 2364539902 RoadSpeedLimitStatus "Status (active or not active) of the system used to limit maximum vehicle velocity.
00b = Active
01b = Not Active
10b = Error
11b = Not available
NOTE - While somewhat inconsistent with other J1939 status parameters, the states defining 00b = ...";
CM_ SG_ 2364539902 AccelPedalKickdownSwitch "Switch signal which indicates whether the accelerator pedal kickdown switch is opened or closed.  The kickdown switch is defined in SAE J1843.

00b = Kickdown passive
01b = Kickdown active
10b = Error
11b = Not available";
CM_ SG_ 2364539902 AccelPedal1LowIdleSwitch "Switch signal which indicates the state of the accelerator pedal 1 low idle switch.  The low idle switch is defined in SAE Recommended Practice J1843.
00b = Accelerator pedal 1 not in low idle condition
01b = Accelerator pedal 1 in low idle ...";
CM_ BO_ 2364540158 "Electronic Engine Controller 1
Engine related parameters";
CM_ SG_ 2364540158 EngDemandPercentTorque "The requested torque output of the engine by all dynamic internal inputs, including smoke control, noise control and low and high speed governing.";
CM_ SG_ 2364540158 EngStarterMode "There are several phases in a starting action and different reasons why a start cannot take place.
0000b = start not requested
0001b = starter active but not engaged
0010b = starter active and engaged
0011b = start finished; starter not active ...";
CM_ SG_ 2364540158 SrcAddrssOfCntrllngDvcForEngCtrl "The source address of the SAE J1939 device currently controlling the engine.  It is used to expand the torque mode parameter (see SPN 899) in cases where control is in response to an ECU that is not listed in Table SPN899_A.  Its value may be the ...";
CM_ SG_ 2364540158 EngSpeed "Actual engine speed which is calculated over a minimum crankshaft angle of 720 degrees divided by the number of cylinders.";
CM_ SG_ 2364540158 ActualEngPercentTorque "The calculated output torque of the engine.  The data is transmitted in indicated torque as a percent of reference engine torque (see the engine configuration message, PGN 65251).  The engine percent torque value will not be less than zero and it ...";
CM_ SG_ 2364540158 DriversDemandEngPercentTorque "The requested torque output of the engine by the driver. It is based on input from the following requestors external to the powertrain: operator (via the accelerator pedal), cruise control and/or road speed limit governor. Dynamic commands from ...";
CM_ SG_ 2364540158 ActlEngPrcntTorqueHighResolution "This parameter displays an additional torque in percent of the reference engine torque.
When the MSB is set to 1, this parameter is not available.  When the MSB is set to 0, bits 1 to 3 indicate the desired torque with resolution of 0.125%/bit  ...";
CM_ SG_ 2364540158 EngTorqueMode "State signal which indicates which engine torque mode is currently generating, limiting, or controlling the torque.  Note that the modes are not in prioritized order. Not all modes may be relevant for a given device.  Some devices may not implement ...";
CM_ BO_ 2566768126 "ECU Identification Information
Message for reporting identification and information about the physical ECU and its hardware, such as the ECU's part number, serial number, build date, etc.  Information about the software within the ECU should be ...";
CM_ SG_ 2566768126 DateOfManufacture "The date of manufacture for the physical ECU. Devices supporting this field are recommended to observe the date formats as described in ISO 8601.";
CM_ SG_ 2566768126 ECUHardwareID "The ECU Hardware ID provides information to identify a specific ECU hardware version.
As an example, on a CAN network, this parameter can be used to uniquely identify the hardware version that is relevant for the interface of the ECU to the CAN ...";
CM_ SG_ 2566768126 ECUManufacturerName "The name of the manufacturer of the physical ECU.

This name may be different than the manufacturer identified by the Manufacturer Code (SPN 2838) and listed in table B10 of J1939.";
CM_ SG_ 2566768126 ECUType "The type of ECU.  One example of a use of the ECU type could be for classifying ECU capabilities, such as I/O.";
CM_ SG_ 2566768126 ECULocation "The location of the ECU within a network.";
CM_ SG_ 2566768126 ECUSerialNumber "The serial number of the physical ECU.";
CM_ SG_ 2566768126 ECUPartNumber "The part number of the physical ECU.";
CM_ BO_ 2566804734 "Engine Continuous Torque & Speed Limit";
CM_ SG_ 2566804734 EngMinContinuousTorque "Applied limit for minimum continuous engine torque";
CM_ SG_ 2566804734 EngMaxContinuousTorque "Applied limit for maximum continuous engine torque.";
CM_ SG_ 2566804734 EngMinContinuousRPM "Applied limit for minimum continuous engine RPM";
CM_ SG_ 2566804734 EngMaxContinuousRPM "Applied limit for maximum continuous engine RPM";
CM_ SG_ 2566804734 EngHghLmtThrshldFrMnCntnsTrqFrmE "Maximum allowable value for minimum continuous torque from engine";
CM_ SG_ 2566804734 EngLwLmtThrshldFrMxTorqueFromEng "Minimum allowable value for maximum continuous torque from engine";
CM_ SG_ 2566804734 EngHghLmtThrshldFrMnCntnusEngRPM "Maximum allowable value for minimum continuous RPM from engine";
CM_ SG_ 2566804734 EngLwLmtThrsholdForMaxRPMFromEng "Minimum allowable value for maximum continuous RPM from engine";
CM_ BO_ 2566841342 "Engine Configuration 1
This map describes the stationary behavior of the engine and the speed dependent available indicated torque.  This map should reflect the effect of changes due to barometric pressure, engine temperature, and any other ...";
CM_ SG_ 2566841342 DefaultIdleTrqLmt "Companion parameter to \"Transmission Communications Failure Idle Torque Limit\" (SPN 7827).  This \"echo\" parameter provides confirmation to the transmission that the engine has received and will invoke the requested SPN 7827 \"Transmission ...";
CM_ SG_ 2566841342 SupportTSC1CtrlPurposeGroup4 "This parameter indicates which TSC1 control purposes are supported in group 4 of 4. One bit is used to convey the support of each Control Purpose. A value of 0 equals supported and a value of 1 equals not supported. This bit logic is used to allow ...";
CM_ SG_ 2566841342 SupportTSC1CtrlPurposeGroup3 "This parameter indicates which TSC1 control purposes are supported in group 3 of 4. One bit is used to convey the support of each Control Purpose. A value of 0 equals supported and a value of 1 equals not supported. This bit logic is used to allow ...";
CM_ SG_ 2566841342 SupportTSC1CtrlPurposeGroup2 "This parameter indicates which TSC1 control purposes are supported in group 2 of 4. One bit is used to convey the support of each Control Purpose. A value of 0 equals supported and a value of 1 equals not supported. This bit logic is used to allow ...";
CM_ SG_ 2566841342 SupportTSC1CtrlPurposeGroup1 "This parameter indicates which TSC1 control purposes are supported in group 1 of 4. One bit is used to convey the support of each Control Purpose. A value of 0 equals supported and a value of 1 equals not supported. This bit logic is used to allow ...";
CM_ SG_ 2566841342 SupportVariableRateTSC1Message "This parameter indicates which TSC1 transmission rates are supported by the engine ECU in addition to the required 10ms transmission rate for temporary powertrain control purposes.
Bit Position      Transmission Rate
1                        1000 ...";
CM_ SG_ 2566841342 EngDefaultTorqueLimit "Companion parameter to Transmission Torque Limit (SPN 1845).  This \"echo\" parameter provides confirmation to the transmission that the engine has received and will invoke the requested Transmission Torque Limit in the event that J1939 communication ...";
CM_ SG_ 2566841342 EngMomentOfInertia "Moment of inertia for the engine, including items driven full-time by the engine such as fuel, oil and cooling pumps.  The inertia from the following items are not included: flywheel, alternator, compressor, fan, and other engine-driven accessories.";
CM_ SG_ 2566841342 EngExRngRqstdSpdCtrlRngUpprLimit "The maximum engine speed regardless of load that the engine will allow when operating in a speed control/limit mode, excluding any maximum momentary engine override speed, if supported.
When the limit is higher than 2500 RPM the 'Requested Speed ...";
CM_ SG_ 2566841342 EngRqstdTrqueCtrlRangeUpperLimit "The maximum engine torque that the engine will allow when operating in a torque control/limit mode.";
CM_ SG_ 2566841342 EngRqstdTrqueCtrlRangeLowerLimit "The minimum engine torque that the engine will allow when operating in a torque control/limit mode.";
CM_ SG_ 2566841342 EngRqstdSpeedCtrlRangeUpperLimit "The maximum engine speed regardless of load that the engine will allow when operating in a speed control/limit mode, excluding any maximum momentary engine override speed, if supported.";
CM_ SG_ 2566841342 EngRqstdSpeedCtrlRangeLowerLimit "The minimum engine speed that the engine will allow when operating in a speed control/limit mode.";
CM_ SG_ 2566841342 EngMaxMomentaryOverrideTimeLimit "The maximum time limit allowed to override the engine's high idle speed.

0 indicates that no override of high idle is allowed.  As value of 255 indicates no time restriction (not applicable)";
CM_ SG_ 2566841342 EngMxMmentaryOverrideSpeedPoint7 "The maximum engine speed above high idle allowed by the engine control during a momentary high idle override.  This duration of the override is limited by the maximum momentary override time limit, SPN 534.";
CM_ SG_ 2566841342 EngReferenceTorque "This parameter is the 100% reference value for all defined indicated engine torque parameters.  It is only defined once and doesn't change if a different engine torque map becomes valid.";
CM_ SG_ 2566841342 EngGain "The endspeed governor is defined as a linear line with the following equations (Capital letters mean physical values, small letters mean normalized values).  Refer to Figures PGN65251_A and PGN65251_B.
The gain (KP or kp) is defined as a positive ...";
CM_ SG_ 2566841342 EngSpeedAtHighIdlePoint6 "Engine speed of high idle (point 6) of the engine torque map (see PGN 65251 and supporting document).  In engine configuration mode 3 (see Figure PGN65251_C), point 6 is not defined by the engine torque map but by the governor characteristic and the ...";
CM_ SG_ 2566841342 EngPercentTorqueAtPoint5 "The torque limit that indicates the available engine torque which can be provided by the engine at point 3, 4, and 5 of the engine map (see PGN 65251 and supporting documents).  It is required that one of these points indicate the peak torque point ...";
CM_ SG_ 2566841342 EngSpeedAtPoint5 "Engine speed of point 3, 4, and 5 of the engine torque map (see PGN 65251 and supporting document).  It is recommended that one of these points indicate the peak torque point for the current engine torque map.  Points 3, 4, and 5 are optional and ...";
CM_ SG_ 2566841342 EngPercentTorqueAtPoint4 "The torque limit that indicates the available engine torque which can be provided by the engine at point 3, 4, and 5 of the engine map (see PGN 65251 and supporting documents).  It is required that one of these points indicate the peak torque point ...";
CM_ SG_ 2566841342 EngSpeedAtPoint4 "Engine speed of point 3, 4, and 5 of the engine torque map (see PGN 65251 and supporting document).  It is recommended that one of these points indicate the peak torque point for the current engine torque map.  Points 3, 4, and 5 are optional and ...";
CM_ SG_ 2566841342 EngPercentTorqueAtPoint3 "The torque limit that indicates the available engine torque which can be provided by the engine at point 3, 4, and 5 of the engine map (see PGN 65251 and supporting documents)..  It is required that one of these points indicate the peak torque point ...";
CM_ SG_ 2566841342 EngSpeedAtPoint3 "Engine speed of point 3, 4, and 5 of the engine torque map (see PGN 65251 and supporting document).  It is recommended that one of these points indicate the peak torque point for the current engine torque map.  Points 3, 4, and 5 are optional and ...";
CM_ SG_ 2566841342 EngPercentTorqueAtPoint2 "The torque limit that indicates the available engine torque which can be provided by the engine at point 2 of the engine map (see PGN 65251 and supporting documents).  In engine configuration mode 1 and 3 (see Table PGN65251_A see PGN 65251), point ...";
CM_ SG_ 2566841342 EngSpeedAtPoint2 "Engine speed of point 2 of the engine torque map (see PGN 65251 and supporting document).  In engine configuration mode 1 and 3, point 2 is defined as the kick-in point from which torque is reduced to zero.  In mode 2 (see Table PGN65251_A), there ...";
CM_ SG_ 2566841342 EngPercentTorqueAtIdlePoint1 "The torque limit that indicates the available engine torque which can be provided by the engine at idle speed.  This parameter may be influenced by engine temperature (after power up) and other stationary changes (calibration offsets, sensor ...";
CM_ SG_ 2566841342 EngSpeedAtIdlePoint1 "Stationary low idle speed of engine which includes influences due to engine temperature (after power up) and other stationary changes (calibration offsets, sensor failures, etc).  This parameter is point 1 of the engine configuration map (see PGN ...";
CM_ BO_ 2566767870 "Electronic Brake Controller 5
Used for information on brake control.";
CM_ SG_ 2566767870 OverallIntendedBrkAcceleration "The 'Overall Intended Brake Acceleration', is the total retardation the brake system is currently trying to achieve using available service and endurances brakes. The target retardation hence includes driver inputs, XBR requests, and in general any ...";
CM_ SG_ 2566767870 DriverBrkDemand "The retardation (deceleration caused by braking) expected to be realized by the brake system exclusively due to the driver inputs, (i.e. excluding demands from XBR requests). The actual retardation may be reduced due to limiting factors during the ...";
CM_ SG_ 2566767870 XBRBrkHoldMode "This parameter indicates the current state of XBR Brake Hold function (which holds the vehicle stationary using service brakes, based on a received XBR Brake Hold Request from an external source).
0000b = Inactive
0001b = Active
0010b = Active ...";
CM_ SG_ 2566767870 RailroadMode "Signal which indicates the current state of the Railroad Mode / Function.
00b = Inactive (Driving mode: Steer Axle on ground)
01b = Active (Railroad mode: Steer Axle lifted off ground)
10b = Error
11b = Not available
Note: This status signal ...";
CM_ SG_ 2566767870 EmergencyBrakingActive "Signal which indicates an emergency braking situation (ref. ECE Regulation 13 paragraph 5.2.1.31) with high  deceleration values.  This signal can be used to activate the hazard lights (ref ECE Regulation 48 paragraph 6.23) to
indicate other road ...";
CM_ SG_ 2566767870 PrkngBrakeActuatorFullyActivated "Signal which indicates when the parking brake actuator is fully activated.  (see also SPN 70 and 619).

00b = Parking Brake Actuator not fully activated
01b = Parking Brake Actuator fully activated
10b = Error
11b = Not available";
CM_ SG_ 2566767870 XBRAccelerationLimit "The brake system may temporarily or generally limit the maximum brake performance available for external systems. A temporary limit may be nessary due to high brake temperature; a general limit may be defined by the vehicle manufacturer, e.g. a ...";
CM_ SG_ 2566767870 XBRActiveCtrlMode "This parameter indicates which XBR Control Mode is executed by the brake system.
0000b = No brake demand being executed (default mode)
0001b = Driver's brake demand being executed, no external brake demand
0010b = Addition mode of XBR ...";
CM_ SG_ 2566767870 XBRSystemState "This parameter indicates which external brake control is allowed.
00b = Any external brake demand will be accepted (brake system fully operational)
01b = Only external brake demand of highest XBR Priority (00b) will be accepted  (e.g. because the ...";
CM_ SG_ 2566767870 FoundationBrakeUse "This parameter indicates if the brake system presently uses the foundation brakes.

00b = Foundation brakes not in use
01b = Foundation brakes in use
10b = Reserved
11b = Not available";
CM_ SG_ 2566767870 HillHolderMode "Signal which indicates the current mode of the hill holder function.
000b = Inactive
001b = Active
010b = Active, but will change to inactive in a short time.  (This mode may be used to warn the driver)
011b = Active, but may activate parking ...";
CM_ SG_ 2566767870 HaltBrakeMode "Signal which indicates the current mode of the halt brake function.
000b = Inactive
001b = Active
010b = Active, but not functioning properly.  (This mode may be used to warn the driver)
011b to 101b = Not defined
110b = Halt brake not ...";
CM_ SG_ 2566767870 BrakeTempWarning "This parameter indicates if the temperature in the service brakes exceeds a certain value. It can be used for a warning information for the driver. The temperature warning value is vehicle manufacturer specific.
00b = Not Active
01b = Active
10b ...";
CM_ BO_ 2633936126 "Wheel Brake Lining Remaining Information";
CM_ SG_ 2633936126 BrkLnngRmningRearAxle3RightWheel "The percentage of brake lining which can still be measured for the right wheel on the rear axle #3.  100% represents new brake linings, 0% represents totally worn brake linings.";
CM_ SG_ 2633936126 BrkLnngRminingRearAxle3LeftWheel "The percentage of brake lining which can still be measured for the left wheel on the rear axle #3.  100% represents new brake linings, 0% represents totally worn brake linings.";
CM_ SG_ 2633936126 BrkLnngRmningRearAxle2RightWheel "The percentage of brake lining which can still be measured for the right wheel on the rear axle #2.  100% represents new brake linings, 0% represents totally worn brake linings.";
CM_ SG_ 2633936126 BrkLnngRminingRearAxle2LeftWheel "The percentage of brake lining which can still be measured for the left wheel on the rear axle #2.  100% represents new brake linings, 0% represents totally worn brake linings.";
CM_ SG_ 2633936126 BrkLnngRmningRearAxle1RightWheel "The percentage of brake lining which can still be measured for the right wheel on the rear axle #1.  100% represents new brake linings, 0% represents totally worn brake linings.";
CM_ SG_ 2633936126 BrkLnngRminingRearAxle1LeftWheel "The percentage of brake lining which can still be measured for the left wheel on the rear axle #1.  100% represents new brake linings, 0% represents totally worn brake linings.";
CM_ SG_ 2633936126 BrkLnngRmningFrontAxleRightWheel "The percentage of brake lining which can still be measured for the right wheel on the front axle.  100% represents new brake linings, 0% represents totally worn brake linings.";
CM_ SG_ 2633936126 BrkLnngRminingFrontAxleLeftWheel "The percentage of brake lining which can still be measured for the left wheel on the front axle.  100% represents new brake linings, 0% represents totally worn brake linings.";
CM_ BO_ 2566827518 "Wheel Application Pressure High Range Information";
CM_ SG_ 2566827518 BrkAppPrssHghRngRrAxl3RightWheel "The brake application pressure for the right wheel on the rear axle #3.";
CM_ SG_ 2566827518 BrkAppPrssHghRngRrAxle3LeftWheel "The brake application pressure for the left wheel on the rear axle #3.";
CM_ SG_ 2566827518 BrkAppPrssHghRngRrAxl2RightWheel "The brake application pressure for the right wheel on the rear axle #2.";
CM_ SG_ 2566827518 BrkAppPrssHghRngRrAxle2LeftWheel "The brake application pressure for the left wheel on the rear axle #2.";
CM_ SG_ 2566827518 BrkAppPrssHghRngRrAxle1LeftWheel "The brake application pressure for the left wheel on the rear axle #1.";
CM_ SG_ 2566827518 BrkAppPrssHghRngFrntAxlRghtWheel "The brake application pressure for the right wheel on the front axle.";
CM_ SG_ 2566827518 BrkAppPrssHghRngFrntAxlLeftWheel "The brake application pressure for the left wheel on the front axle.";
CM_ SG_ 2566827518 BrkAppPrssHghRngRrAxl1RightWheel "The brake application pressure for the right wheel on the rear axle #1.";
CM_ BO_ 2566832126 "Wheel Speed Information";
CM_ SG_ 2566832126 RelativeSpeedRearAxle2RightWheel "The speed of the rear axle #2, right wheel relative to the front axle speed, SPN 904.";
CM_ SG_ 2566832126 RelativeSpeedRearAxle2LeftWheel "The speed of the rear axle #2, left wheel relative to the front axle speed, SPN 904.";
CM_ SG_ 2566832126 RelativeSpeedRearAxle1RightWheel "The speed of the rear axle #1, right wheel relative to the front axle speed, SPN 904.";
CM_ SG_ 2566832126 RelativeSpeedRearAxle1LeftWheel "The speed of the rear axle #1, left wheel relative to the front axle speed, SPN 904.";
CM_ SG_ 2566832126 RelativeSpeedFrontAxleRightWheel "The speed of the front axle, right wheel relative to the front axle speed, SPN 904.";
CM_ SG_ 2566832126 RelativeSpeedFrontAxleLeftWheel "The speed of the front axle, left wheel relative to the front axle speed, SPN 904.";
CM_ SG_ 2566832126 FrontAxleSpeed "The average speed of the two front wheels.";
CM_ BO_ 2565865982 "Electronic Brake Controller 1
Used for brake control information";
CM_ SG_ 2565865982 RailroadModeSw "Switch signal which indicates the position of the Railroad mode switch.
00b = Railroad mode switch passive (City/Highway mode)
01b = Railroad mode switch active (Railroad mode)
10b = Error
11b = Not available
Note:  This switch signal to be ...";
CM_ SG_ 2565865982 TrctrMntdTrailerABSWarningSignal "This parameter commands the tractor-mounted trailer ABS optical warning signal.

00b = Off
01b = On 
10b = Reserved
11b = Take no action";
CM_ SG_ 2565865982 TrailerABSStatus "State signal which indicates that ABS in the trailer is actively controlling the brakes.  A message is sent to the tractor from the trailer (i.e. by PLC). The receiving device in the tractor transfers this information to the J1939 network.  At the ...";
CM_ SG_ 2565865982 HaltBrakeSwitch "Switch signal which indicates the position of the halt brake switch.

00b = Halt brake switch passive
01b = Halt brake switch active
10b = Error
11b = Not available";
CM_ SG_ 2565865982 SrcAddrssOfCntrllngDvcFrBrkeCtrl "The source address of the SAE J1939 device currently controlling the brake system. Its value may be the source address of the ECU transmitting the message (which means that no external SAE J1939 message is providing the active command) or the source ...";
CM_ SG_ 2565865982 ATC_ASRInformationSignal "This parameter commands the ATC/ASR driver information signal, for example a dash lamp.

00b = Off
01b = On 
10b = Reserved
11b = Take no action";
CM_ SG_ 2565865982 ABS_EBSAmberWarningSignal "This parameter commands the ABS/EBS amber/yellow optical warning signal

00b = Off
01b = On
10b = Reserved
11b = Take no action";
CM_ SG_ 2565865982 EBSRedWarningSignal "This parameter commands the EBS red optical warning signal

00b = Off
01b = On
10b = Reserved
11b = Take no action";
CM_ SG_ 2565865982 ABSFullyOperational "Signal which indicates whether an ABS system is fully operational or whether its functionality is reduced by a defect or by an intended action (e.g., by activation of an ABS-off-road switch or during special diagnostic procedures).  There are cases ...";
CM_ SG_ 2565865982 EngRetarderSelection "The position of the operator controlled selector, expressed as a percentage and determined by the ratio of the current position of the selector to its maximum possible position. Zero percent means no braking torque is requested by the operator from ...";
CM_ SG_ 2565865982 RemoteAccelEnableSwitch "Switch signal which indicates that the remote accelerator has been enabled and controls the engine.
00b = Off
01b = On
10b = Error
11b = Not available
NOTE—The accelerator interlock switch (see SPN 972) must be disabled in order for the remote ...";
CM_ SG_ 2565865982 EngAuxShutdownSwitch "Switch signal which requests that all engine fueling stop.

00b = Off
01b = On
10b = Error
11b = Not available";
CM_ SG_ 2565865982 EngDerateSwitch "Switch signal used to activate the torque limiting feature of the engine.  The specific nature of torque limiting should be verified with the manufacturer.

00b = Off
01b = On
10b = Error
11b = Not available";
CM_ SG_ 2565865982 AccelInterlockSwitch "Switch signal used to disable the accelerator and remote accelerator inputs, causing the engine to return to idle.

00b = Off
01b = On
10b = Error
11b = Not available";
CM_ SG_ 2565865982 TractionCtrlOverrideSwitch "Switch signal which indicates the position of the traction control override switch.  The traction control override signal disables the automatic traction control function allowing the wheels to spin.
00b = Off
01b = On
10b = Error
11b = Not ...";
CM_ SG_ 2565865982 ASRHillHolderSwitch "Switch signal which indicates the position of the ASR \"hill holder\" switch.

00b = ASR \"hill holder\" switch passive
01b = ASR \"hill holder\" switch active
10b = Error
11b = Not available";
CM_ SG_ 2565865982 ASROffroadSwitch "Switch signal which indicates the position of the ASR off-road switch.

00b = ASR off-road switch passive
01b = ASR off-road switch active
10b = Error
11b = Not available";
CM_ SG_ 2565865982 ABSOffroadSwitch "Switch signal which indicates the position of the ABS off-road switch.

00b = ABS off-road switch passive
01b = ABS off-road switch active
10b = Error
11b = Not available";
CM_ SG_ 2565865982 BrakePedalPos "Ratio of brake pedal position to maximum pedal position.  Used for electric brake applications. 0% means no braking. Also when there are two brake pedals on the machine (Left Brake Pedal Position SPN 3033 and Right Brake Pedal Position SPN 3032) the ...";
CM_ SG_ 2565865982 EBSBrakeSwitch "Switch signal which indicates that the brake pedal is being pressed.  The EBS brake switch is independent of the brake light switch and has no provisions for external connections.
00b = Brake pedal is not being pressed
01b = Brake pedal is being ...";
CM_ SG_ 2565865982 AntiLockBrakingActive "State signal which indicates that the ABS is active.  The signal is set active when wheel brake pressure actually starts to be modulated by ABS and is reset to passive when all wheels are in a stable condition for a certain time.  The signal can ...";
CM_ SG_ 2565865982 ASRBrakeCtrlActive "State signal which indicates that ASR brake control is active. Active means that ASR actually controls wheel brake pressure at one or more wheels of the driven axle(s).
00b = ASR brake control passive but installed
01b = ASR brake control active
 ...";
CM_ SG_ 2565865982 ASREngCtrlActive "State signal which indicates that ASR engine control has been commanded to be active. Active means that ASR actually tries to control the engine. This state signal is independent of other control commands to the engine (e.g., from the transmission) ...";
CM_ BO_ 2565867262 "Electronic Axle Controller 1
NOTE - Request has to be responded to with as many messages as necessary to transmit all available information.";
CM_ SG_ 2565867262 DogClutchRearAxle2 "Status of the Dog Clutch Rear Axle 2.

00b = Dog Clutch Rear Axle 2 Disengaged
01b = Dog Clutch Rear Axle 2 Engaged
10b = Error
11b = Not Available";
CM_ SG_ 2565867262 DiffLockStRearAxle3 "State used which indicates the condition of the rear axle 3 differential lock. The differential locks are located as defined in figure SPN 564_A.
00b = Differential lock disengaged
01b = Differential lock engaged
10b = Error
11b = Not available
 ...";
CM_ SG_ 2565867262 RearAxleGroupEngagementStatus "Rear axle group engagement status

00b = rear axle group disengaged 
01b = rear axle group engaged
10b = error
11b = not available";
CM_ SG_ 2565867262 FrontAxleGroupEngagementStatus "Front axle group engagement status 

00b = front axle group disengaged 
01b = front axle group engaged
10b = error
11b = not available";
CM_ SG_ 2565867262 DiffLockStateCentralRear "State used which indicates the condition of the central rear differential lock.  The differential locks are located as defined in figure SPN564_A.
00b = Differential lock disengaged
01b = Differential lock engaged
10b = Error
11b = Not available
 ...";
CM_ SG_ 2565867262 DiffLockStateCentralFront "State used which indicates the condition of the central front differential lock.  The differential locks are located as defined in figure SPN564_A.
00b = Differential lock disengaged
01b = Differential lock engaged
10b = Error
11b = Not ...";
CM_ SG_ 2565867262 DiffLockStateCentral "State used which indicates the condition of the central differential lock.  The differential locks are located as defined in attached figure SPN564_A.
00b = Differential lock disengaged
01b = Differential lock engaged
10b = Error
11b = Not ...";
CM_ SG_ 2565867262 DiffLockStateRearAxle2 "State used which indicates the condition of the rear axle 2 differential lock.  The differential locks are located as defined in figure SPN 564_A.
00b = Differential lock disengaged
01b = Differential lock engaged
10b = Error
11b = Not available
 ...";
CM_ SG_ 2565867262 DiffLockStateRearAxle1 "State used which indicates the condition of the rear axle 1 differential lock.  The differential locks are located as defined in figure SPN 564_A.
00b = Differential lock disengaged
01b = Differential lock engaged
10b = Error
11b = Not available
 ...";
CM_ SG_ 2565867262 DiffLockStateFrontAxle2 "State used which indicates the condition of the front axle 2 differential lock. The differential locks are located as defined in figure SPN 564_A.
00b = Differential lock disengaged
01b = Differential lock engaged
10b = Error
11b = Not available
 ...";
CM_ SG_ 2565867262 DiffLockStateFrontAxle1 "State used which indicates the condition of the front axle 1 differential lock.  The differential locks are located as defined in figure SPN564_A.
00b = Differential lock disengaged
01b = Differential lock engaged
10b = Error
11b = Not available
 ...";
CM_ SG_ 2565867262 Location "To identify to which of several similar devices (such as tires or fuel tanks) the information applies.
The low order 4 bits represent a position number, counting left to right when facing in the direction of normal vehicle travel (forward).
The ...";
CM_ BO_ 2566821118 "Engine Auxiliary Coolant";
CM_ SG_ 2566821118 AftercoolerCoolantOutPress "The gage pressure of the engine coolant located at the aftercooler outlet.";
CM_ SG_ 2566821118 SeaWaterPumpOutPress2 "Gage pressure of liquid found at outlet of sea water pump in sea water cooling system - second instance.";
CM_ SG_ 2566821118 CPCoolantOutPress "Engine coolant pressure at the coolant pump outlet.";
CM_ SG_ 2566821118 EngCoolantPress2 "Gage pressure of liquid found in engine coolant system - second instance.

See also SPN 5708 for alternate range and resolution.";
CM_ SG_ 2566821118 EngExRangeCoolantPress "Gage pressure of liquid found in engine cooling system.

See also SPN 109 for alternate range and resolution.";
CM_ SG_ 2566821118 SeaWaterPumpOutletPress "Gauge pressure of liquid found at outlet of sea water pump in sea water cooling system.";
CM_ SG_ 2566821118 EngAuxCoolantTemp "Temperature of coolant found in the intercooler which is located after the turbocharger.";
CM_ SG_ 2566821118 EngAuxCoolantPress "Gage pressure of coolant found in the intercooler which is located after the turbocharger.";
CM_ BO_ 2566810622 "Driver's Identification
Field:
a Driver 1 Identification
Delimiter (ASCII “*”)
b Driver 2 Identification
Delimiter (ASCII “*”)
NOTE - If only driver card 1 is present, only the parameter driver 1 identification and two delimiters shall be ...";
CM_ SG_ 2566810622 Driver2Identification "Used to obtain the driver identity.";
CM_ SG_ 2566810622 Driver1Identification "Used to obtain the driver identity.";
CM_ BO_ 2566847742 "Dash Display 1";
CM_ SG_ 2566847742 EngOilFilterDiffPress7471 "Change in engine oil pressure, measured across the filter, due to the filter and any accumulation of solid or semisolid material on or in the filter. See SPN 99 for alternate resolution.";
CM_ SG_ 2566847742 FuelLevel2 "Ratio of volume of fuel to the total volume of fuel in the second or right-side storage container.  When Fuel Level 2 is not used, Fuel Level 1 (SPN 96) represents the total fuel in all fuel storage containers.";
CM_ SG_ 2566847742 CargoAmbientTemp "Temperature of air inside vehicle container used to accommodate cargo.";
CM_ SG_ 2566847742 EngOilFilterDiffPress "Change in engine oil pressure, measured across the filter, due to the filter and any accumulation of solid or semisolid material on or in the filter.  See SPN 7471 for alternate resolution.";
CM_ SG_ 2566847742 EngFuelFilterDiffPress "Change in fuel delivery pressure, measured across the filter, due to accumulation of solid or semisolid matter on the filter element.

See SPN 22744 (Engine Fuel Filter Differential Pressure (High Resolution) for alternate resolution.";
CM_ SG_ 2566847742 FuelLevel1 "Ratio of volume of fuel to the total volume of fuel storage container.
When Fuel Level 2 (SPN 38) is not used, Fuel Level 1 represents the total fuel in all fuel storage containers.  When Fuel Level 2 is used, Fuel Level 1 represents the fuel level ...";
CM_ SG_ 2566847742 WasherFluidLevel "Ratio of volume of liquid to total container volume of fluid reservoir in windshield wash system.";
CM_ BO_ 2314732030 "This PGN provides latitude and longitude referenced to WGS84";
CM_ BO_ 2498778622 "Engine Cylinder 8 Combustion Average Information
Used to transmit the average of combustion parameters of Engine Cylinder 8.
This PG is transmitted at a defined ratio of the engine speed. The transmission rate is dependent on
SPN 6394 - Number of ...";
CM_ SG_ 2498778622 EngCyl8AverageCombustionDuration "Average duration of combustion calculated over defined number of combustion cycles for engine cylinder 8 with reference to the crank angle.  Combustion duration is the difference between end of combustion and start of combustion expressed, in this ...";
CM_ SG_ 2498778622 EngCyl8AvrgCntrOfCmbustionTiming "Average timing calculated over defined number of combustion cycles for the center of combustion in engine cylinder 8 with reference to the crank angle.  Center of Combustion is used to indicate the combustion efficiency.  When the combustion happens ...";
CM_ SG_ 2498778622 EngCyl8AvrgStrtOfCmbustionTiming "Average start of combustion timing calculated over defined number of combustion cycles for engine cylinder 8 with reference to the crank angle.  When the combustion happens after the TDC (Top Dead Center) of this cylinder, the timing is referred in ...";
CM_ SG_ 2498778622 EngCyl8IndctedMeanEffectivePress "Average cylinder pressure calculated over defined number of combustion cycles for engine cylinder 8.  Negative range is to cover thermodynamic behavior during misfire.";
CM_ BO_ 2498778366 "Engine Cylinder 7 Combustion Average Information
Used to transmit the average of combustion parameters of Engine Cylinder 7.
This PG is transmitted at a defined ratio of the engine speed. The transmission rate is dependent on
SPN 6394 - Number of ...";
CM_ SG_ 2498778366 EngCyl7AverageCombustionDuration "Average duration of combustion calculated over defined number of combustion cycles for engine cylinder 7 with reference to the crank angle.  Combustion duration is the difference between end of combustion and start of combustion expressed, in this ...";
CM_ SG_ 2498778366 EngCyl7AvrgCntrOfCmbustionTiming "Average timing calculated over defined number of combustion cycles for the center of combustion in engine cylinder 7 with reference to the crank angle.  Center of Combustion is used to indicate the combustion efficiency.  When the combustion happens ...";
CM_ SG_ 2498778366 EngCyl7AvrgStrtOfCmbustionTiming "Average start of combustion timing calculated over defined number of combustion cycles for engine cylinder 7 with reference to the crank angle.  When the combustion happens after the TDC (Top Dead Center) of this cylinder, the timing is referred in ...";
CM_ SG_ 2498778366 EngCyl7IndctedMeanEffectivePress "Average cylinder pressure calculated over defined number of combustion cycles for engine cylinder 7.  Negative range is to cover thermodynamic behavior during misfire.";
CM_ BO_ 2498778110 "Engine Cylinder 6 Combustion Average Information
Used to transmit the average of combustion parameters of Engine Cylinder 6.
This PG is transmitted at a defined ratio of the engine speed. The transmission rate is dependent on
SPN 6394 - Number of ...";
CM_ SG_ 2498778110 EngCyl6AverageCombustionDuration "Average duration of combustion calculated over defined number of combustion cycles for engine cylinder 6 with reference to the crank angle.  Combustion duration is the difference between end of combustion and start of combustion expressed, in this ...";
CM_ SG_ 2498778110 EngCyl6AvrgCntrOfCmbustionTiming "Average timing calculated over defined number of combustion cycles for the center of combustion in engine cylinder 6 with reference to the crank angle.  Center of Combustion is used to indicate the combustion efficiency.  When the combustion happens ...";
CM_ SG_ 2498778110 EngCyl6AvrgStrtOfCmbustionTiming "Average start of combustion timing calculated over defined number of combustion cycles for engine cylinder 6 with reference to the crank angle.  When the combustion happens after the TDC (Top Dead Center) of this cylinder, the timing is referred in ...";
CM_ SG_ 2498778110 EngCyl6IndctedMeanEffectivePress "Average cylinder pressure calculated over defined number of combustion cycles for engine cylinder 6.  Negative range is to cover thermodynamic behavior during misfire.";
CM_ BO_ 2498777854 "Engine Cylinder 5 Combustion Average Information
Used to transmit the average of combustion parameters of Engine Cylinder 5.
This PG is transmitted at a defined ratio of the engine speed. The transmission rate is dependent on
SPN 6394 - Number of ...";
CM_ SG_ 2498777854 EngCyl5AverageCombustionDuration "Average duration of combustion calculated over defined number of combustion cycles for engine cylinder 5 with reference to the crank angle.  Combustion duration is the difference between end of combustion and start of combustion expressed, in this ...";
CM_ SG_ 2498777854 EngCyl5AvrgCntrOfCmbustionTiming "Average timing calculated over defined number of combustion cycles for the center of combustion in engine cylinder 5 with reference to the crank angle.  Center of Combustion is used to indicate the combustion efficiency.  When the combustion happens ...";
CM_ SG_ 2498777854 EngCyl5AvrgStrtOfCmbustionTiming "Average start of combustion timing calculated over defined number of combustion cycles for engine cylinder 5 with reference to the crank angle.  When the combustion happens after the TDC (Top Dead Center) of this cylinder, the timing is referred in ...";
CM_ SG_ 2498777854 EngCyl5IndctedMeanEffectivePress "Average cylinder pressure calculated over defined number of combustion cycles for engine cylinder 5.  Negative range is to cover thermodynamic behavior during misfire.";
CM_ BO_ 2498777598 "Engine Cylinder 4 Combustion Average Information
Used to transmit the average of combustion parameters of Engine Cylinder 4.
This PG is transmitted at a defined ratio of the engine speed. The transmission rate is dependent on
SPN 6394 - Number of ...";
CM_ SG_ 2498777598 EngCyl4AverageCombustionDuration "Average duration of combustion calculated over defined number of combustion cycles for engine cylinder 4 with reference to the crank angle.  Combustion duration is the difference between end of combustion and start of combustion expressed, in this ...";
CM_ SG_ 2498777598 EngCyl4AvrgCntrOfCmbustionTiming "Average timing calculated over defined number of combustion cycles for the center of combustion in engine cylinder 4 with reference to the crank angle.  Center of Combustion is used to indicate the combustion efficiency.  When the combustion happens ...";
CM_ SG_ 2498777598 EngCyl4AvrgStrtOfCmbustionTiming "Average start of combustion timing calculated over defined number of combustion cycles for engine cylinder 4 with reference to the crank angle.  When the combustion happens after the TDC (Top Dead Center) of this cylinder, the timing is referred in ...";
CM_ SG_ 2498777598 EngCyl4IndctedMeanEffectivePress "Average cylinder pressure calculated over defined number of combustion cycles for engine cylinder 4.  Negative range is to cover thermodynamic behavior during misfire.";
CM_ BO_ 2498777342 "Engine Cylinder 3 Combustion Average Information
Used to transmit the average of combustion parameters of Engine Cylinder 3.
This PG is transmitted at a defined ratio of the engine speed. The transmission rate is dependent on
SPN 6394 - Number of ...";
CM_ SG_ 2498777342 EngCyl3AverageCombustionDuration "Average duration of combustion calculated over defined number of combustion cycles for engine cylinder 3 with reference to the crank angle.  Combustion duration is the difference between end of combustion and start of combustion expressed, in this ...";
CM_ SG_ 2498777342 EngCyl3AvrgCntrOfCmbustionTiming "Average timing calculated over defined number of combustion cycles for the center of combustion in engine cylinder 3 with reference to the crank angle.  Center of Combustion is used to indicate the combustion efficiency.  When the combustion happens ...";
CM_ SG_ 2498777342 EngCyl3AvrgStrtOfCmbustionTiming "Average start of combustion timing calculated over defined number of combustion cycles for engine cylinder 3 with reference to the crank angle.  When the combustion happens after the TDC (Top Dead Center) of this cylinder, the timing is referred in ...";
CM_ SG_ 2498777342 EngCyl3IndctedMeanEffectivePress "Average cylinder pressure calculated over defined number of combustion cycles for engine cylinder 3.  Negative range is to cover thermodynamic behavior during misfire.";
CM_ BO_ 2566768382 "Cold Start Aids
Cold start aid information and settings.";
CM_ SG_ 2566768382 EngCldStrtFlIgniterRelayFeedback "Feedback state of the engine cold start fuel igniter relay which indicates the status of the relay output.

00b = Off
01b = On
10b = Error
11b = Not available";
CM_ SG_ 2566768382 EngColdStartFuelIgniterRelay "The engine cold start fuel igniter relay control command.  This command controls the relay, not the igniter.

00b = Off
01b = On
10b = Reserved
11b = Don't care/take no action";
CM_ SG_ 2566768382 EngColdStartFuelIgniterCmd "The engine cold start fuel igniter control command, normalized to %, where 0% represents fully off and 100% represents fully on.";
CM_ SG_ 2566768382 EngStartEnableDevice2Config "The start enable device installed for start enable device 2.
0000b = no start enable device 2 installed
0001b = glow plugs installed
0010b = fuelled start installed
0011b = ether injection installed
0100b = electric intake air heater installed
 ...";
CM_ SG_ 2566768382 EngStartEnableDevice1Config "The start enable device installed for start enable device 1.
0000b = no start enable device 1 installed
0001b = glow plugs installed
0010b = fuelled start installed
0011b = ether injection installed
0100b = electric intake air heater installed
 ...";
CM_ SG_ 2566768382 EngStartEnableDevice2 "Devices that assist an engine in starting, e.g. intake heaters, ether, or an alternate/secondary starting aid.  May be of the same type or different than Start Enable Device 1 (SPN 626). Parameter indicating whether the start enable device 2 is ON ...";
CM_ SG_ 2566768382 EngStartEnableDevice1 "Devices that assist an Engine in starting, e.g. intake heaters and ether.  Primary starting aid.
Parameter indicating whether the start enable device 1 is ON or OFF
00b = start enable OFF
01b = start enable ON
10b = reserved
11b = not available
 ...";
CM_ BO_ 2566811902 "Combination Vehicle Weight";
CM_ SG_ 2566811902 GrossCombinationConf "Represents the confidence in % of the estimated gross combination vehicle weight (SPN 1760) and shall reflect to what degree the mass estimator function has had the opportunity to evaluate sufficiently many driving situations to estimate a correct ...";
CM_ SG_ 2566811902 PoweredVehicleWeight "Total mass imposed by the tires of the powered vehicle on the road surface.  Does not include the trailer.";
CM_ SG_ 2566811902 GrossCombinationVehicleWeight "The total weight of the truck and all attached trailers.";
CM_ BO_ 2563768062 "Continuous Torque & Speed Limit Request";
CM_ SG_ 2563768062 MxCntinuousRetarderTorqueLimitRq "Requested maximum continuous retarder torque (operating range: -125 to 0%)";
CM_ SG_ 2563768062 MnCntinuousRetarderTorqueLimitRq "Requested minimum continuous retarder torque (operating range: -125 to 0%)";
CM_ SG_ 2563768062 MxContinuousRetarderSpeedLimitRq "Requested maximum continuous retarder speed";
CM_ SG_ 2563768062 MnContinuousRetarderSpeedLimitRq "Requested minimum continuous retarder speed";
CM_ SG_ 2563768062 EngTorqueLimitRqMaxContinuous "Requested maximum continuous engine torque (operating range: 0 to 125%)";
CM_ SG_ 2563768062 EngTorqueLimitRqMinContinuous "Requested minimum continuous engine torque (operating range: 0 to 125%)";
CM_ SG_ 2563768062 EngSpeedLimitRqMaxContinuous "Requested maximum continuous engine speed";
CM_ SG_ 2563768062 EngSpeedLimitRqMinContinuous "Requested minimum continuous engine speed";
CM_ BO_ 2633924862 "Combustion Time 6";
CM_ SG_ 2633924862 EngAverageCombustionTime "The average combustion time of all cylinders of an engine.";
CM_ SG_ 2633924862 EngDesiredCombustionTime "The desired combustion time based upon engine load and speed lookup maps.";
CM_ BO_ 2633924606 "Combustion Time 5";
CM_ SG_ 2633924606 EngCyl20CombustionTime "The amount of time from when the ignition of the fuel is initiated to when the fuel is completely ignited (i.e., the flame front has propagated across the cylinder).";
CM_ SG_ 2633924606 EngCyl19CombustionTime "The amount of time from when the ignition of the fuel is initiated to when the fuel is completely ignited (i.e., the flame front has propagated across the cylinder).";
CM_ SG_ 2633924606 EngCyl18CombustionTime "The amount of time from when the ignition of the fuel is initiated to when the fuel is completely ignited (i.e., the flame front has propagated across the cylinder).";
CM_ SG_ 2633924606 EngCyl17CombustionTime "The amount of time from when the ignition of the fuel is initiated to when the fuel is completely ignited (i.e., the flame front has propagated across the cylinder).";
CM_ BO_ 2633924350 "Combustion Time 4";
CM_ SG_ 2633924350 EngCyl16CombustionTime "The amount of time from when the ignition of the fuel is initiated to when the fuel is completely ignited (i.e., the flame front has propagated across the cylinder).";
CM_ SG_ 2633924350 EngCyl15CombustionTime "The amount of time from when the ignition of the fuel is initiated to when the fuel is completely ignited (i.e., the flame front has propagated across the cylinder).";
CM_ SG_ 2633924350 EngCyl14CombustionTime "The amount of time from when the ignition of the fuel is initiated to when the fuel is completely ignited (i.e., the flame front has propagated across the cylinder).";
CM_ SG_ 2633924350 EngCyl13CombustionTime "The amount of time from when the ignition of the fuel is initiated to when the fuel is completely ignited (i.e., the flame front has propagated across the cylinder).";
CM_ BO_ 2633924094 "Combustion Time 3";
CM_ SG_ 2633924094 EngCyl12CombustionTime "The amount of time from when the ignition of the fuel is initiated to when the fuel is completely ignited (i.e., the flame front has propagated across the cylinder).";
CM_ SG_ 2633924094 EngCyl11CombustionTime "The amount of time from when the ignition of the fuel is initiated to when the fuel is completely ignited (i.e., the flame front has propagated across the cylinder).";
CM_ SG_ 2633924094 EngCyl10CombustionTime "The amount of time from when the ignition of the fuel is initiated to when the fuel is completely ignited (i.e., the flame front has propagated across the cylinder).";
CM_ SG_ 2633924094 EngCyl9CombustionTime "The amount of time from when the ignition of the fuel is initiated to when the fuel is completely ignited (i.e., the flame front has propagated across the cylinder).";
CM_ BO_ 2633923838 "Combustion Time 2";
CM_ SG_ 2633923838 EngCyl8CombustionTime "The amount of time from when the ignition of the fuel is initiated to when the fuel is completely ignited (i.e., the flame front has propagated across the cylinder).";
CM_ SG_ 2633923838 EngCyl7CombustionTime "The amount of time from when the ignition of the fuel is initiated to when the fuel is completely ignited (i.e., the flame front has propagated across the cylinder).";
CM_ SG_ 2633923838 EngCyl6CombustionTime "The amount of time from when the ignition of the fuel is initiated to when the fuel is completely ignited (i.e., the flame front has propagated across the cylinder).";
CM_ SG_ 2633923838 EngCyl5CombustionTime "The amount of time from when the ignition of the fuel is initiated to when the fuel is completely ignited (i.e., the flame front has propagated across the cylinder).";
CM_ BO_ 2633923582 "Combustion Time 1";
CM_ SG_ 2633923582 EngCyl4CombustionTime "The amount of time from when the ignition of the fuel is initiated to when the fuel is completely ignited (i.e., the flame front has propagated across the cylinder).";
CM_ SG_ 2633923582 EngCyl3CombustionTime "The amount of time from when the ignition of the fuel is initiated to when the fuel is completely ignited (i.e., the flame front has propagated across the cylinder).";
CM_ SG_ 2633923582 EngCyl2CombustionTime "The amount of time from when the ignition of the fuel is initiated to when the fuel is completely ignited (i.e., the flame front has propagated across the cylinder).";
CM_ SG_ 2633923582 EngCyl1CombustionTime "The amount of time from when the ignition of the fuel is initiated to when the fuel is completely ignited (i.e., the flame front has propagated across the cylinder).";
CM_ BO_ 2633878014 "Electronic Control Module Information
Information relating to electronic control modules";
CM_ SG_ 2633878014 TotalCountOfConfigChangesMade "Total number of times changes have been made to any of the configurable parameters.";
CM_ BO_ 2566771966 "Cab Message 3
Provides information from Cab mounted operator inputs.";
CM_ SG_ 2566771966 RemoteKeyFobFunctionReq "Indicates the function or action that was last requested from the vehicle's key fob.
00h = No Request
01h = Door Unlock Request
02h = Door Lock Request
03h = Start Request
04h = Stop Request
05h = Front Closure Release Request
06h = Rear ...";
CM_ SG_ 2566771966 OpKeySwOff "Indicates that the operator key switch is in the Off state. In this state, the vehicle is inactive and not receiving power or propulsion.
This parameter represents the capability of a rotary key switch position (or lack of a physical key present), ...";
CM_ SG_ 2566771966 OpKeySwSvc "Indicates that the Service state of the operator key switch is active. In this state, the vehicle has full power, but propulsion is not allowed and the engine is not active. This state is commonly used for engineering and service purposes.
This ...";
CM_ SG_ 2566771966 EngAirShutoffManualSw "This switch will be used by the operator to activate the engine air shutoff valve, which will cause the engine to shut down.

00b = Off
01b = On
10b = Error
11b = Not available";
CM_ SG_ 2566771966 EngAirShutoffTestSw "This switch, commonly a momentary switch, when activated will enable the test mode for the engine air shutoff valve. When all applicable criteria are true, the air shutoff valve will activate and shut down the engine.
00b = Off
01b = On
10b = ...";
CM_ SG_ 2566771966 HornSw "Activates the vehicle (city) horn

00b = Horn switch is off
01b = Horn switch is on
10b = Error
11b = Not Available";
CM_ SG_ 2566771966 OpKeySwDelayedBatOff "Indicates a state in which the main battery switch will be opened after a short delay. This allows the battery to be disconnected (as may be required by ADR regulations) while avoiding memory corruption due to unexpected loss of battery power.
This ...";
CM_ SG_ 2566771966 OpKeySwStart "Indicates that the start state of the operator key switch is active. This state is also known in DIN 75552 as \"KL50\".
This parameter represents the capability of a rotary key switch position, a keyless switch state, or a state determined by the ...";
CM_ SG_ 2566771966 OpKeySwIgntPwr "Indicates that the ignition (or \"run\") state of the operator key switch is active. This state is also known in DIN 75552 as \"KL15\". Devices should use SPN 158 to report voltage at their switched battery input.
This parameter represents the ...";
CM_ SG_ 2566771966 OpKeySwAccessoryPwr "Indicates that the accessory state of the operator key switch is active.
This parameter represents the capability of a rotary key switch position, a keyless switch state, or a state determined by the Momentary Operator Key Switch button ...";
CM_ SG_ 2566771966 OpKeyDetected "Indicates that a key is physically inserted in the key switch, or for keyless systems, that a valid key is within activation range.

00b = No key detected
01b = Key is detected
10b = Error
11b = Not Available";
CM_ SG_ 2566771966 MomentaryOpKeySw "Momentary switch (possibly a push button switch) that indicates the operator's desire to enter accessory mode, enter run mode, enter crank mode, activate the propulsion system, or initiate another behavior as determined by the manufacturer. This ...";
CM_ SG_ 2566771966 AFTSCRDosingModeCmd "Request the aftertreatment system to run in standard or reduced mode.
Standard indicates that the system will dose at higher capacity where the reduced mode will dose at a lower capacity.  (e.g., IMO 3 to IMO 2 in Marine Applications)
000b = ...";
CM_ SG_ 2566771966 VehTrailerStatus "Indicates a trailer is connected to the towing mechanism.  This is not intended to indicate that the trailer is latched.

00b = Trailer is not detected
01b = Trailer is detected
10b = Error
11b = Not available";
CM_ SG_ 2566771966 TransOilLevelRq "Conveys operator or vehicle system desire for a transmission oil level reading to be taken. 

00b = No transmission oil level reading desired
01b = Transmission oil level reading desired
10b = Reserved
11b = Don't care / take no action";
CM_ SG_ 2566771966 FifthWheelReleaseCtrl "Operator input used to release the fifth wheel. Fifth Wheel Release Control Security Lockout and other conditions must be properly enabled before this will function.
00b = Coupler Locked
01b = Coupler Unlocked, trailer can be unhitched or hitched
 ...";
CM_ SG_ 2566771966 FfthWhlRleaseCtrlSecurityLockout "Operator's fifth wheel release control interlock. This operator input must be enabled prior to activating the fifth wheel release control (SPN 3314).
00b = Fifth wheel release Disabled
01b = Fifth wheel release Enabled
10b = Error
11b = Not ...";
CM_ SG_ 2566771966 TransferCaseSelectorSwitch "Operator switch to select the condition of the transfer case.  States 000b and 001b should be used if the transfer case only functions to switch between 2-wheel and 4-wheel drive.  If the transfer case includes a High / Low Range function, states ...";
CM_ BO_ 2564882174 "Cab Message 1
Message containing parameters originating from the vehicle cab.";
CM_ SG_ 2564882174 SelectedMaxVehicleSpeedLimit "User selected maximum vehicle speed.  If one is selected, then this SP must equal one of the maximum vehicle speeds #1-#7 from PGN 64997 - Maximum Vehicle Speed Limit Status. If different maximum vehicle speed requests are present from different ...";
CM_ SG_ 2564882174 RqCabZoneHeating "Request to activate cab zone heating.

00b = Do not heat cab engine zone
01b = Heat cab zone
10b = Reserved
11b = Don't care/take no action";
CM_ SG_ 2564882174 RqEngZoneHeating "Request to activate engine zone heating.

00b = Do not heat engine zone
01b = Heat engine zone
10b = Reserved
11b = Don't care/take no action";
CM_ SG_ 2564882174 AuxHeaterModeRq "Request to activate the auxiliary heater.
0000b = De-activate auxiliary heater
0001b = Off due to ADR per European Regulations for Transport of hazardous materials
0010b = Economy mode
0011b = Normal mode
0100b = Heater pump up-keep
0101b to ...";
CM_ SG_ 2564882174 EngAutomaticStartEnableSwitch "Switch signal which enables the idle management system to be enabled. When this system is enabled with the engine in an idle mode and safe operating conditions existing, then the engine may be started or stopped automatically.
00b = Switch in the ...";
CM_ SG_ 2564882174 AtomaticGearShiftingEnableSwitch "Indicates that automated gear shifting is enabled via a switch

00b = Automated Gear Shifting is disabled
01b = Automated Gear Shifting is enabled
10b = Error
11b = Not available";
CM_ SG_ 2564882174 AFTRegenForceSw "Indicates the state of a switch available to the operator that forces aftertreatment regeneration.
00b = not active
01b = active
10b = error
11b = not available
This SP would be \"not active\" when aftertreatment regeneration is allowed to occur ...";
CM_ SG_ 2564882174 AFTRegenInhSw "Indicates the state of a switch available to the operator that inhibits aftertreatment regeneration.
00b = not active
01b = active
10b = error
11b = not available
This SP would be \"not active\" when aftertreatment regeneration is allowed to ...";
CM_ SG_ 2564882174 VhclLmtngSpdGovernorEnableSwitch "Switch signal which enables the Vehicle Limiting Speed Governor (VLSG) such that the vehicle speed may be either increased or decreased when the engine is off idle.

00b = Switch disabled
01b = Switched enabled
10b = Error
11b = Not available";
CM_ SG_ 2564882174 VhclLmtngSpdGvrnrIncrementSwitch "Switch signal which increases the Vehicle Limiting Speed Governor (VLSG).

00b = Switch in the off state
01b = Switch in the on state - increase
10b = Error
11b = Not available";
CM_ SG_ 2564882174 VhclLmtngSpdGvrnrDecrementSwitch "Switch signal which decreases the Vehicle Limiting Speed Governor (VLSG).

00b = Switch in the off state
01b = Switch in the on state - decrease
10b = Error
11b = Not available";
CM_ SG_ 2564882174 ParkBrakeCmd "Request by a secondary device to command the Park Brake.  The Park Brake controller should treat this as a request and should apply the Park Brake as determined by the controller.
Feedback of the park brake actuation may utilize SPN 70, SPN 619 or ...";
CM_ SG_ 2564882174 SeatBeltSwitch "State of switch used to determine if Seat Belt is buckled

00b = NOT Buckled
01b = OK - Seat Belt is buckled
10b = Error - Switch state cannot be determined
11b = Not Available";
CM_ SG_ 2564882174 OperatorSeatDirectionSwitch "Senses whether the operator seat is in the forward driving position

00b = Operator seat not facing forward
01b = Operator seat is facing forward
10b = Error
11b = Not Available";
CM_ SG_ 2564882174 BatteryMainSwitchHoldRq "Request to hold the battery main switch.

00b = Release Battery Main Switch
01b = Hold Battery Main Switch
10b = undefined
11b = Don't care/take no action";
CM_ SG_ 2564882174 AuxHeaterCoolantPumpRq "Indicates whether to activate the auxiliary heater coolant water pump.

00b = Deactivate water pump
01b = Activate water pump
10b = Reserved
11b = Don't care/take no action";
CM_ SG_ 2564882174 CabInteriorTempCmd "Parameter used to command a certain cab interior temperature.

Note: See also SPN 170.  SPN 1662 is an additional diagnostic SP associated with cab temperature.";
CM_ SG_ 2564882174 RequestedPercentFanSpeed "Fan speed of the first or only fan in the system as a ratio of the actual fan drive (current speed) to the fully engaged fan drive (maximum fan speed). A two state fan (off/on) will use 0% and 100% respectively. A three state fan ...";
CM_ BO_ 2563833598 "Cab Illumination Message
This message contains information that controls illumination devices inside the vehicle's cab.";
CM_ SG_ 2563833598 OpDesDisplayModeCmd2 "The desired mode of the operator's display.  Allows the operator to select different day/night modes and broadcast desired setting to other displays in the system.  Display modes may include brightness, color, etc.
0000b = Mode 1 (default: \"day ...";
CM_ SG_ 2563833598 OpDesDisplayModeCmd1 "The desired mode of the operator's display.  Allows the operator to select different day/night modes and broadcast desired setting to other displays in the system.  Display modes may include brightness, color, etc.
0000b = Mode 1 (default: \"day ...";
CM_ SG_ 2563833598 SwtchBcklghtIllmntnBrghtnssPrcnt "Commanded switch backlight brightness level for all operator control switches.  This is separate from the cab display illumination Brightness Percent parameter.
Note:  If a single device is used to control both the backlight brightness level of the ...";
CM_ SG_ 2563833598 IlluminationBrightnessPercent "Commanded backlight brightness level for all cab displays.  

Note:  If a separate device is used to independently control the switch backlight brightness level, see SPN 5532.";
CM_ SG_ 2563833598 SwtchIndctnIllmntnBrghtnssPrcent "Commanded switch indication illumination brightness level for all operator control switches. This is separate from the cab display illumination Brightness Percent parameter.
Note: If a single device is used to control both the indication brightness ...";
CM_ BO_ 2566843390 "Component Identification
NOTE - The make, model, serial number and unit number fields in this message are optional and separated by an ASCII “*”.  It is not necessary to include all fields; however, the delimiter (“*”) is always required.
Field:
 ...";
CM_ SG_ 2566843390 UnitNumber "Owner assigned unit number for the power unit of the vehicle.

NOTE: The ASCII character \"*\" is reserved as a delimiter.";
CM_ SG_ 2566843390 SerialNumber "Serial number of the component.

NOTE - The ASCII character \"*\" is reserved as a delimiter.";
CM_ SG_ 2566843390 Model "Model of the component.

NOTE - The ASCII character \"*\" is reserved as a delimiter.";
CM_ SG_ 2566843390 Make "Make of the component corresponding to the codes defined in the American Trucking Association Vehicle Maintenance Reporting Standard (ATA/VMRS).
Note:  This parameter is typically a 5 character ASCII string.  If not available, it should be ...";
CM_ BO_ 2566844926 "Cruise Control/Vehicle Speed 1
Cruise Control/Vehicle Speed 1";
CM_ SG_ 2566844926 EngShutdownOverrideSwitch "Switch signal which indicates the position of the engine shutdown override switch.  This switch function allows the operator to override an impending engine shutdown.

00b = Off
01b = On
10b = Error
11b = Not available";
CM_ SG_ 2566844926 EngTestModeSwitch "Switch signal which indicates the position of the engine diagnostic test mode switch.

00b = Off
01b = On
10b = Error
11b = Not available";
CM_ SG_ 2566844926 EngIdleDecrementSwitch "Switch signal which indicates the position of the idle decrement switch.

00b = Off
01b = On
10b = Error
11b = Not available";
CM_ SG_ 2566844926 EngIdleIncrementSwitch "Switch signal which indicates the position of the idle increment switch.

00b = Off
01b = On
10b = Error
11b = Not available";
CM_ SG_ 2566844926 CruiseCtrlStates "This parameter is used to indicate the current state, or mode, of operation by the cruise control device.  This is a status parameter.
000b = Off/Disabled
001b = Hold
010b = Accelerate
011b = Decelerate
100b = Resume
101b = Set
110b = ...";
CM_ SG_ 2566844926 PTOGovernorState "This parameter is used to indicate the current state or mode of operation by the power takeoff (PTO) governor.  In lieu of support for PTO Drive Engagement parameters, this parameter may represent the status of a PTO drive.  The broadcasting device ...";
CM_ SG_ 2566844926 CruiseCtrlSetSpeed "Value of set (chosen) velocity of velocity control system.  See SPN 6809 for an alternate resolution.
If an algorithm that can modify the cruise control set point exists in the system, such as Predictive Cruise Control or Adaptive Cruise Control, ...";
CM_ SG_ 2566844926 CruiseCtrlAccelerateSwitch "Switch signal of the cruise control activator which indicates that the activator is in the position \"accelerate.\"
00b = Cruise control activator not in the position \"accelerate\"
01b = Cruise control activator in position \"accelerate\"
10b = Error
 ...";
CM_ SG_ 2566844926 CruiseCtrlResumeSwitch "Switch signal of the cruise control activator which indicates that the activator is in the position \"resume.\"
00b = Cruise control activator not in the position \"resume\"
01b = Cruise control activator in position \"resume\"
10b = Error
11b = Not ...";
CM_ SG_ 2566844926 CruiseCtrlCoastSwitch "Switch signal of the cruise control activator which indicates that the activator is in the position \"coast (decelerate).\"
00b = Cruise control activator not in the position \"coast\"
01b = Cruise control activator in position \"coast\"
10b = Error
 ...";
CM_ SG_ 2566844926 CruiseCtrlSetSwitch "Switch signal of the cruise control activator which indicates that the activator is in the position \"set.\"
00b = Cruise control activator not in the position \"set\"
01b = Cruise control activator in position \"set\"
10b = Error
11b = Not available
 ...";
CM_ SG_ 2566844926 ClutchSwitch "Switch signal which indicates that the clutch pedal is being pressed. It is necessary for a safe drivetrain behavior that the clutch switch is set before the clutch is opened (cruise control function).
00b = Clutch pedal released
01b = Clutch ...";
CM_ SG_ 2566844926 BrakeSwitch "Switch signal which indicates that the driver operated brake foot pedal is being pressed.  This brake foot pedal is controlling the vehicles' service brake (total vehicle braking application, not park brakes).  It is necessary for safe drivetrain ...";
CM_ SG_ 2566844926 CruiseCtrlEnableSwitch "Switch signal which indicates that it is possible to manage the cruise control function.

00b = Cruise control disabled
01b = Cruise control enabled
10b = Error
11b = Not available";
CM_ SG_ 2566844926 CruiseCtrlActive "Cruise control is switched on.  It is not ensured that the engine is controlled by cruise control, as in the case of a large driver's demand the engine is controlled by the driver while cruise control is active (maximum selection of cruise control ...";
CM_ SG_ 2566844926 WheelBasedVehicleSpeed "Speed of the vehicle as calculated from wheel or tailshaft speed.";
CM_ SG_ 2566844926 ParkBrakeReleaseInhibitRq "Park Brake Release Inhibit Request signals the desire that an applied park brake remain applied and limit the ability of the vehicle to be moved.
00b = Park Brake Release Inhibit not requested
01b = Park Brake Release Inhibit requested
10b = SAE ...";
CM_ SG_ 2566844926 CruiseCtrlPauseSwitch "Switch signal which indicates the position of the Cruise Control Pause Switch used on Remote Cruise Control applications. The Cruise Control Pause Switch signal temporarily disables the Cruise Control function.
00b = Off
01b = On
10b = Error ...";
CM_ SG_ 2566844926 ParkingBrakeSwitch "Switch signal which indicates when the parking brake is set. In general the switch actuated by the operator's park brake control, whether a pedal, lever or other control mechanism  (see also SPN 619 and 5275).
00b = Parking brake not set
01b = ...";
CM_ SG_ 2566844926 TwoSpeedAxleSwitch "Switch signal which indicates the current axle range.

00b = Low speed range
01b = High speed range
10b = Error
11b = Not available";
CM_ BO_ 2566843902 "Cruise Control/Vehicle Speed Setup";
CM_ SG_ 2566843902 PowertrainAdaptiveCCType "Status to indicate the type of adaptive cruise control that is supported by the powertrain and the controller that manages cruise control and its ability to support the Cruise Control Pause/Resume Command parameters (SPN 5605, SPN 5604) within the ...";
CM_ SG_ 2566843902 CtrlSetCmdSupport "Indicates support for SPN 9843 Cruise Control Set Command by the system that manages cruise control.
00b = System does not support the “Cruise Control Set Command” feature
01b = System does support the \"Cruise Control Set Command\" feature
10b = ...";
CM_ SG_ 2566843902 CtrlPauseCmdSupport "Indicates support for SPN 5605 Cruise Control Pause Command by the system that manages cruise control.
00b = System does not support the “Cruise Control Pause Command” feature
01b = System does support the \"Cruise Control Pause Command\" feature
 ...";
CM_ SG_ 2566843902 CtrlResumeCmdSupport "Indicates support for SPN 5604 Cruise Control Resume Command by the system that manages cruise control.
00b = System does not support the “Cruise Control Resume Command” feature
01b = System does support the \"Cruise Control Resume Command\" feature
 ...";
CM_ SG_ 2566843902 CtrlDisCmdSupport "Indicates support for SPN 5603 Cruise Control Disable Command by the system that manages cruise control.
00b = System does not support the “Cruise Control Disable Command”
01b = System does support the \"Cruise Control Disable Command\" feature
10b ...";
CM_ SG_ 2566843902 CtrlSysLowSetLmtSpd "Minimum vehicle velocity at which cruise can be set or resumed by a source other than the operator.
Associated with the CCVS2 signals SPN 5604 - Cruise Control Resume Command and SPN 9843 - Cruise Control Set Command.
If this parameter is not ...";
CM_ SG_ 2566843902 MaxVehicleSpeedLimit6808 "Maximum vehicle velocity allowed. See SPN 74 for an alternate resolution.";
CM_ SG_ 2566843902 CruiseCtrlLowSetLimitSpeed "Minimum vehicle velocity at which cruise can be set by the operator or minimum vehicle velocity for cruise operation before it will exit cruise control operation.
Associated with the CCVS1 signals SPN 599 - Cruise Control Set Switch and SPN 601 - ...";
CM_ SG_ 2566843902 CruiseCtrlHighSetLimitSpeed "Maximum vehicle velocity at which cruise can be set.

If Cruise Control Adjusted Maximum Speed (SPN 7495) is supported, then SPN 7495 has priority over SPN 87. See the definition for SPN 7495 for more details.";
CM_ SG_ 2566843902 MaxVehicleSpeedLimit "Maximum vehicle velocity allowed.   See SPN 6808 for an alternate resolution.";
CM_ BO_ 2566809598 "Climate Control Configuration";
CM_ SG_ 2566809598 AuxHeaterMaxOutputPower "The maximum output power of the auxiliary heater.";
CM_ BO_ 2633940222 "Compression/Service Brake Information";
CM_ SG_ 2633940222 TripServiceBrakeApplications "Total number of times the service brakes have been activated since the last trip reset.  Brake applications of less than 0.5 s are not counted and lengthy brake applications (longer than 0.5 s) are counted as a single event.
NOTE - Definition and ...";
CM_ SG_ 2633940222 TripServiceBrakeDistance "Total distance over which the service brakes have been active since the last trip reset.";
CM_ SG_ 2633940222 TripCompressionBrakeDistance "Total distance over which the compression brakes have been active since the last trip reset.";
CM_ SG_ 2633940222 TotalCompressionBrakeDistance "Total distance over which the compression brakes have been active for the life of the engine.";
BA_DEF_ SG_  "GenSigInactiveValue" INT 0 0;
BA_DEF_ SG_  "SigType" ENUM  "Default","Range","RangeSigned","ASCII","Discrete","Control","ReferencePGN","DTC","StringDelimiter","StringLength","StringLengthControl","MessageCounter","MessageChecksum";
BA_DEF_ SG_  "GenSigStartValue" INT 0 2147483647;
BA_DEF_ SG_  "GenSigSendType" ENUM  "Cyclic","OnWrite","OnWriteWithRepetition","OnChange","OnChangeWithRepetition","IfActive","IfActiveWithRepetition","NoSigSendType";
BA_DEF_ SG_  "GenSigILSupport" ENUM  "No","Yes";
BA_DEF_ SG_  "SPN" INT 0 524287;
BA_DEF_ BO_  "J1939CPgSendTimeout" INT -1 3600000;
BA_DEF_ BO_  "J1939CPgTOS" INT 0 7;
BA_DEF_ BO_  "J1939PgAppearanceOnBus" ENUM  "Default","CAN_Extended","CANFD_Extended";
BA_DEF_ BO_  "FsJ1939UseCrcAndCounter" STRING ;
BA_DEF_ BO_  "TpJ1939VarDlc" ENUM  "No","Yes";
BA_DEF_ BO_  "GenMsgNrOfRepetition" INT 0 1000000;
BA_DEF_ BO_  "GenMsgCycleTimeFast" INT 0 3600000;
BA_DEF_ BO_  "GenMsgFastOnStart" INT 0 100000;
BA_DEF_ BO_  "GenMsgStartDelayTime" INT 0 100000;
BA_DEF_ BO_  "GenMsgILSupport" ENUM  "No","Yes";
BA_DEF_ BO_  "GenMsgDelayTime" INT 0 1000;
BA_DEF_ BO_  "GenMsgRequestable" INT 0 1;
BA_DEF_ BO_  "GenMsgSendType" ENUM  "cyclic","NotUsed","NotUsed","NotUsed","NotUsed","NotUsed","NotUsed","IfActive","noMsgSendType";
BA_DEF_ BO_  "VFrameFormat" ENUM  "StandardCAN","ExtendedCAN","reserved","J1939PG","reserved","reserved","reserved","reserved","reserved","reserved","reserved","reserved","reserved","reserved","StandardCAN_FD","ExtendedCAN_FD";
BA_DEF_ BO_  "SingleFrame" INT 0 1;
BA_DEF_ BO_  "GenMsgCycleTime" INT 0 3600000;
BA_DEF_ SG_  "SystemSignalLongSymbol" STRING ;
BA_DEF_DEF_  "GenSigInactiveValue" 0;
BA_DEF_DEF_  "SigType" "Default";
BA_DEF_DEF_  "GenSigStartValue" 0;
BA_DEF_DEF_  "GenSigSendType" "NoSigSendType";
BA_DEF_DEF_  "GenSigILSupport" "Yes";
BA_DEF_DEF_  "SPN" 0;
BA_DEF_DEF_  "J1939CPgSendTimeout" -1;
BA_DEF_DEF_  "J1939CPgTOS" 2;
BA_DEF_DEF_  "J1939PgAppearanceOnBus" "Default";
BA_DEF_DEF_  "FsJ1939UseCrcAndCounter" "";
BA_DEF_DEF_  "TpJ1939VarDlc" "No";
BA_DEF_DEF_  "GenMsgNrOfRepetition" 0;
BA_DEF_DEF_  "GenMsgCycleTimeFast" 0;
BA_DEF_DEF_  "GenMsgFastOnStart" 0;
BA_DEF_DEF_  "GenMsgStartDelayTime" 0;
BA_DEF_DEF_  "GenMsgILSupport" "Yes";
BA_DEF_DEF_  "GenMsgDelayTime" 0;
BA_DEF_DEF_  "GenMsgRequestable" 1;
BA_DEF_DEF_  "GenMsgSendType" "noMsgSendType";
BA_DEF_DEF_  "VFrameFormat" "J1939PG";
BA_DEF_DEF_  "SingleFrame" 1;
BA_DEF_DEF_  "GenMsgCycleTime" 0;
BA_DEF_DEF_  "SystemSignalLongSymbol" "";
BA_ "GenMsgDelayTime" BO_ 2365446142 20;
BA_ "GenMsgSendType" BO_ 2365446142 0;
BA_ "GenMsgCycleTime" BO_ 2365446142 100;
BA_ "GenMsgSendType" BO_ 2633929470 0;
BA_ "GenMsgCycleTime" BO_ 2633929470 100;
BA_ "GenMsgSendType" BO_ 2364541694 0;
BA_ "GenMsgCycleTime" BO_ 2364541694 50;
BA_ "GenMsgSendType" BO_ 2566810366 0;
BA_ "GenMsgCycleTime" BO_ 2566810366 500;
BA_ "GenMsgSendType" BO_ 2566767102 0;
BA_ "GenMsgCycleTime" BO_ 2566767102 500;
BA_ "GenMsgSendType" BO_ 2566839294 0;
BA_ "GenMsgCycleTime" BO_ 2566839294 500;
BA_ "GenMsgSendType" BO_ 2566844414 0;
BA_ "GenMsgCycleTime" BO_ 2566844414 500;
BA_ "GenMsgSendType" BO_ 2633929726 0;
BA_ "GenMsgCycleTime" BO_ 2633929726 100;
BA_ "GenMsgSendType" BO_ 2566840318 0;
BA_ "GenMsgCycleTime" BO_ 2566840318 250;
BA_ "GenMsgSendType" BO_ 2364539902 0;
BA_ "GenMsgCycleTime" BO_ 2364539902 50;
BA_ "GenMsgSendType" BO_ 2364540158 0;
BA_ "GenMsgCycleTime" BO_ 2364540158 50;
BA_ "TpJ1939VarDlc" BO_ 2566768126 1;
BA_ "GenMsgSendType" BO_ 2566804734 0;
BA_ "GenMsgCycleTime" BO_ 2566804734 5000;
BA_ "GenMsgDelayTime" BO_ 2566841342 500;
BA_ "GenMsgSendType" BO_ 2566841342 0;
BA_ "GenMsgCycleTime" BO_ 2566841342 5000;
BA_ "GenMsgSendType" BO_ 2566767870 0;
BA_ "GenMsgCycleTime" BO_ 2566767870 100;
BA_ "GenMsgSendType" BO_ 2566827518 0;
BA_ "GenMsgCycleTime" BO_ 2566827518 100;
BA_ "GenMsgSendType" BO_ 2566832126 0;
BA_ "GenMsgCycleTime" BO_ 2566832126 100;
BA_ "GenMsgSendType" BO_ 2565865982 0;
BA_ "GenMsgCycleTime" BO_ 2565865982 100;
BA_ "GenMsgSendType" BO_ 2565867262 0;
BA_ "GenMsgCycleTime" BO_ 2565867262 500;
BA_ "GenMsgSendType" BO_ 2566821118 0;
BA_ "GenMsgCycleTime" BO_ 2566821118 500;
BA_ "TpJ1939VarDlc" BO_ 2566810622 1;
BA_ "GenMsgSendType" BO_ 2566847742 0;
BA_ "GenMsgCycleTime" BO_ 2566847742 1000;
BA_ "GenMsgCycleTime" BO_ 2314732030 100;
BA_ "GenMsgSendType" BO_ 2563768062 0;
BA_ "GenMsgCycleTime" BO_ 2563768062 5000;
BA_ "GenMsgDelayTime" BO_ 2566771966 100;
BA_ "GenMsgSendType" BO_ 2566771966 0;
BA_ "GenMsgCycleTime" BO_ 2566771966 10000;
BA_ "GenMsgDelayTime" BO_ 2564882174 100;
BA_ "GenMsgSendType" BO_ 2564882174 0;
BA_ "GenMsgCycleTime" BO_ 2564882174 1000;
BA_ "GenMsgDelayTime" BO_ 2563833598 100;
BA_ "GenMsgSendType" BO_ 2563833598 0;
BA_ "GenMsgCycleTime" BO_ 2563833598 5000;
BA_ "TpJ1939VarDlc" BO_ 2566843390 1;
BA_ "GenMsgSendType" BO_ 2566844926 0;
BA_ "GenMsgCycleTime" BO_ 2566844926 100;
BA_ "SigType" SG_ 2365446142 Joystick1Button13PressedStatus 4;
BA_ "SPN" SG_ 2365446142 Joystick1Button13PressedStatus 6731;
BA_ "SigType" SG_ 2365446142 Joystick1Button14PressedStatus 4;
BA_ "SPN" SG_ 2365446142 Joystick1Button14PressedStatus 6732;
BA_ "SigType" SG_ 2365446142 Joystick1Button15PressedStatus 4;
BA_ "SPN" SG_ 2365446142 Joystick1Button15PressedStatus 6733;
BA_ "SigType" SG_ 2365446142 Joystick1Button16PressedStatus 4;
BA_ "SPN" SG_ 2365446142 Joystick1Button16PressedStatus 6734;
BA_ "SigType" SG_ 2365446142 Jystick1GripXAxisDetentPosStatus 4;
BA_ "SPN" SG_ 2365446142 Jystick1GripXAxisDetentPosStatus 2682;
BA_ "SigType" SG_ 2365446142 Jystick1GripYAxisDetentPosStatus 4;
BA_ "SPN" SG_ 2365446142 Jystick1GripYAxisDetentPosStatus 2683;
BA_ "SigType" SG_ 2365446142 Jystick1ThetaAxisDetentPosStatus 4;
BA_ "SPN" SG_ 2365446142 Jystick1ThetaAxisDetentPosStatus 2684;
BA_ "SPN" SG_ 2365446142 Joystick1ThetaAxisPos 2664;
BA_ "SigType" SG_ 2365446142 Jystck1ThtAxsClckwsPstvPosStatus 4;
BA_ "SPN" SG_ 2365446142 Jystck1ThtAxsClckwsPstvPosStatus 2669;
BA_ "SigType" SG_ 2365446142 Jystck1ThetaAxisNeutralPosStatus 4;
BA_ "SPN" SG_ 2365446142 Jystck1ThetaAxisNeutralPosStatus 2679;
BA_ "SPN" SG_ 2365446142 Joystick1GripYAxisPos 2663;
BA_ "SigType" SG_ 2365446142 Jystck1GrpYAxsLvrFrwrdPstvPsStts 4;
BA_ "SPN" SG_ 2365446142 Jystck1GrpYAxsLvrFrwrdPstvPsStts 2668;
BA_ "SigType" SG_ 2365446142 Jystck1GrpYAxsLvrBckNgtvPsStatus 4;
BA_ "SPN" SG_ 2365446142 Jystck1GrpYAxsLvrBckNgtvPsStatus 2673;
BA_ "SigType" SG_ 2365446142 Aftrtrtmnt1DslExhstFldPrprtsPrlm 4;
BA_ "SPN" SG_ 2365446142 Aftrtrtmnt1DslExhstFldPrprtsPrlm 2678;
BA_ "SPN" SG_ 2365446142 Joystick1GripXAxisPos 2662;
BA_ "SigType" SG_ 2365446142 Jystck1GrpXAxsLvrRghtPstvPsSttus 4;
BA_ "SPN" SG_ 2365446142 Jystck1GrpXAxsLvrRghtPstvPsSttus 2667;
BA_ "SigType" SG_ 2365446142 Jystck1GrpXAxsLvrLftNgtvPsStatus 4;
BA_ "SPN" SG_ 2365446142 Jystck1GrpXAxsLvrLftNgtvPsStatus 2672;
BA_ "SigType" SG_ 2365446142 Jystck1GripXAxisNeutralPosStatus 4;
BA_ "SPN" SG_ 2365446142 Jystck1GripXAxisNeutralPosStatus 2677;
BA_ "SigType" SG_ 2365446142 Jystck1ThtAxsCntrClckwsNgtvPsStt 4;
BA_ "SPN" SG_ 2365446142 Jystck1ThtAxsCntrClckwsNgtvPsStt 2674;
BA_ "SigType" SG_ 2633929470 EngFuelRackPos 1;
BA_ "SPN" SG_ 2633929470 EngFuelRackPos 1210;
BA_ "SigType" SG_ 2633929470 EngGasMassFlowRate1 1;
BA_ "SPN" SG_ 2633929470 EngGasMassFlowRate1 1241;
BA_ "SigType" SG_ 2633929470 InstantaneousEstBrakePower 1;
BA_ "SPN" SG_ 2633929470 InstantaneousEstBrakePower 1242;
BA_ "SigType" SG_ 2633929470 EngExhaustGasPress1 1;
BA_ "SPN" SG_ 2633929470 EngExhaustGasPress1 1209;
BA_ "SigType" SG_ 2633929470 EngPrefilterOilPress 1;
BA_ "SPN" SG_ 2633929470 EngPrefilterOilPress 1208;
BA_ "SigType" SG_ 2633937406 TotalECURunTime 1;
BA_ "SPN" SG_ 2633937406 TotalECURunTime 1033;
BA_ "SigType" SG_ 2633937406 TotalECUDistance 1;
BA_ "SPN" SG_ 2633937406 TotalECUDistance 1032;
BA_ "SigType" SG_ 2364541694 TargetFreshAirMassFlow 1;
BA_ "SPN" SG_ 2364541694 TargetFreshAirMassFlow 12758;
BA_ "SigType" SG_ 2364541694 EngExhstGsRcrcltion2MassFlowRate 1;
BA_ "SPN" SG_ 2364541694 EngExhstGsRcrcltion2MassFlowRate 5257;
BA_ "SigType" SG_ 2364541694 EngIntakeAirMassFlowRate 1;
BA_ "SPN" SG_ 2364541694 EngIntakeAirMassFlowRate 132;
BA_ "SigType" SG_ 2364541694 EngExhstGsRcrcltion1MassFlowRate 1;
BA_ "SPN" SG_ 2364541694 EngExhstGsRcrcltion1MassFlowRate 2659;
BA_ "SigType" SG_ 2566810366 FuelPrimingSt 5;
BA_ "SPN" SG_ 2566810366 FuelPrimingSt 11732;
BA_ "SigType" SG_ 2566810366 EngFuelSupplyPumpIntakePress 1;
BA_ "SPN" SG_ 2566810366 EngFuelSupplyPumpIntakePress 7104;
BA_ "SigType" SG_ 2566810366 FuelPumpPrimerStatus 5;
BA_ "SPN" SG_ 2566810366 FuelPumpPrimerStatus 4083;
BA_ "SPN" SG_ 2566810366 EngVentilationStatus 3554;
BA_ "SigType" SG_ 2566810366 EngCoolantPreheatedState 5;
BA_ "SPN" SG_ 2566810366 EngCoolantPreheatedState 3553;
BA_ "SigType" SG_ 2566810366 EngOilPreHeatedState 5;
BA_ "SPN" SG_ 2566810366 EngOilPreHeatedState 3552;
BA_ "SigType" SG_ 2566810366 EngOilPrimingState 5;
BA_ "SPN" SG_ 2566810366 EngOilPrimingState 3551;
BA_ "SigType" SG_ 2566810366 EngOilPrimingPumpSwitch 4;
BA_ "SPN" SG_ 2566810366 EngOilPrimingPumpSwitch 3550;
BA_ "SigType" SG_ 2566810366 EngOilFilterOutletPress 1;
BA_ "SPN" SG_ 2566810366 EngOilFilterOutletPress 3549;
BA_ "SigType" SG_ 2566810366 EngWasteOilReservoirLevel 1;
BA_ "SPN" SG_ 2566810366 EngWasteOilReservoirLevel 3548;
BA_ "SigType" SG_ 2566810366 EngFuelFilterDiffPress 1;
BA_ "SPN" SG_ 2566810366 EngFuelFilterDiffPress 1382;
BA_ "SigType" SG_ 2566810366 EngFuelSupplyPumpIntakeAbsPress 1;
BA_ "SPN" SG_ 2566810366 EngFuelSupplyPumpIntakeAbsPress 1381;
BA_ "SigType" SG_ 2566810366 EngOilLevelRemoteReservoir 1;
BA_ "SPN" SG_ 2566810366 EngOilLevelRemoteReservoir 1380;
BA_ "SigType" SG_ 2566767102 EngThrottleValve1DiffPress 1;
BA_ "SPN" SG_ 2566767102 EngThrottleValve1DiffPress 5631;
BA_ "SigType" SG_ 2566767102 EngExhstGsRcrclation1OutletPress 1;
BA_ "SPN" SG_ 2566767102 EngExhstGsRcrclation1OutletPress 5019;
BA_ "SigType" SG_ 2566767102 EngExhstVlvActtionSystemOilPress 1;
BA_ "SPN" SG_ 2566767102 EngExhstVlvActtionSystemOilPress 4287;
BA_ "SigType" SG_ 2566767102 EngExhstGsRcrclation1IntakePress 1;
BA_ "SPN" SG_ 2566767102 EngExhstGsRcrclation1IntakePress 3358;
BA_ "SigType" SG_ 2566767102 EngIntkVlvActationSystemOilPress 1;
BA_ "SPN" SG_ 2566767102 EngIntkVlvActationSystemOilPress 2948;
BA_ "SigType" SG_ 2566839294 EngInjectorMeteringRail2Press 1;
BA_ "SPN" SG_ 2566839294 EngInjectorMeteringRail2Press 1349;
BA_ "SigType" SG_ 2566839294 EngInjectorTimingRail1Press 1;
BA_ "SPN" SG_ 2566839294 EngInjectorTimingRail1Press 156;
BA_ "SigType" SG_ 2566839294 EngInjectorMeteringRail1Press 1;
BA_ "SPN" SG_ 2566839294 EngInjectorMeteringRail1Press 157;
BA_ "SigType" SG_ 2566839294 EngInjectionCtrlPress 1;
BA_ "SPN" SG_ 2566839294 EngInjectionCtrlPress 164;
BA_ "SigType" SG_ 2566844414 EngCoolantLevel 1;
BA_ "SPN" SG_ 2566844414 EngCoolantLevel 111;
BA_ "SigType" SG_ 2566844414 EngCoolantPress 1;
BA_ "SPN" SG_ 2566844414 EngCoolantPress 109;
BA_ "SigType" SG_ 2566844414 EngCrankcasePress 1;
BA_ "SPN" SG_ 2566844414 EngCrankcasePress 101;
BA_ "SigType" SG_ 2566844414 EngOilPress 1;
BA_ "SPN" SG_ 2566844414 EngOilPress 100;
BA_ "SigType" SG_ 2566844414 EngOilLevel 1;
BA_ "SPN" SG_ 2566844414 EngOilLevel 98;
BA_ "SigType" SG_ 2566844414 EngExCrankcaseBlowbyPress 1;
BA_ "SPN" SG_ 2566844414 EngExCrankcaseBlowbyPress 22;
BA_ "SigType" SG_ 2566844414 EngFuelDeliveryPress 1;
BA_ "SPN" SG_ 2566844414 EngFuelDeliveryPress 94;
BA_ "SigType" SG_ 2633929726 SafetyWireStatus 5;
BA_ "SPN" SG_ 2633929726 SafetyWireStatus 1205;
BA_ "SigType" SG_ 2633929726 ElectricalLoad 1;
BA_ "SPN" SG_ 2633929726 ElectricalLoad 1204;
BA_ "SigType" SG_ 2566772222 EngVrblGeometryTurbo1ActuatorPos 1;
BA_ "SPN" SG_ 2566772222 EngVrblGeometryTurbo1ActuatorPos 2795;
BA_ "SigType" SG_ 2566772222 EngVriableGeometryTurbo1CtrlMode 5;
BA_ "SPN" SG_ 2566772222 EngVriableGeometryTurbo1CtrlMode 5457;
BA_ "SigType" SG_ 2566772222 EngFuelCtrlCtrlMode 5;
BA_ "SPN" SG_ 2566772222 EngFuelCtrlCtrlMode 5323;
BA_ "SigType" SG_ 2566772222 EngVrblGmtryTrbArCtrlShtoffValve 5;
BA_ "SPN" SG_ 2566772222 EngVrblGmtryTrbArCtrlShtoffValve 2792;
BA_ "SigType" SG_ 2566772222 EngExhstGsRcirculation1ValveCtrl 1;
BA_ "SPN" SG_ 2566772222 EngExhstGsRcirculation1ValveCtrl 2791;
BA_ "SigType" SG_ 2566772222 EngTrb1ClclatedTurbineOutletTemp 1;
BA_ "SPN" SG_ 2566772222 EngTrb1ClclatedTurbineOutletTemp 2790;
BA_ "SigType" SG_ 2566772222 EngTrb1ClclatedTurbineIntakeTemp 1;
BA_ "SPN" SG_ 2566772222 EngTrb1ClclatedTurbineIntakeTemp 2789;
BA_ "SigType" SG_ 2633940734 PrelubeOilLowPressThreshold 1;
BA_ "SPN" SG_ 2633940734 PrelubeOilLowPressThreshold 8622;
BA_ "SigType" SG_ 2633940734 CrnkAttmptCntOnPrsntStartAttempt 1;
BA_ "SPN" SG_ 2633940734 CrnkAttmptCntOnPrsntStartAttempt 3671;
BA_ "SigType" SG_ 2633940734 EngIntakeManifoldPressCtrlMode 5;
BA_ "SPN" SG_ 2633940734 EngIntakeManifoldPressCtrlMode 5465;
BA_ "SigType" SG_ 2633940734 EngRotationDirection 4;
BA_ "SPN" SG_ 2633940734 EngRotationDirection 3669;
BA_ "SigType" SG_ 2633940734 EngRatedSpeed 1;
BA_ "SPN" SG_ 2633940734 EngRatedSpeed 189;
BA_ "SigType" SG_ 2633940734 EngRatedPower 1;
BA_ "SPN" SG_ 2633940734 EngRatedPower 166;
BA_ "SigType" SG_ 2566840318 A2ExhDewPoint 5;
BA_ "SPN" SG_ 2566840318 A2ExhDewPoint 3240;
BA_ "SigType" SG_ 2566840318 A2InDewPoint 5;
BA_ "SPN" SG_ 2566840318 A2InDewPoint 3239;
BA_ "SigType" SG_ 2566840318 A1ExhDewPoint 5;
BA_ "SPN" SG_ 2566840318 A1ExhDewPoint 3238;
BA_ "SigType" SG_ 2566840318 A1InDewPoint 5;
BA_ "SPN" SG_ 2566840318 A1InDewPoint 3237;
BA_ "SigType" SG_ 2566840318 A1ExhGasMFR 1;
BA_ "SPN" SG_ 2566840318 A1ExhGasMFR 3236;
BA_ "SigType" SG_ 2566840318 EstEngPrsiticLossesPercentTorque 1;
BA_ "GenSigStartValue" SG_ 2566840318 EstEngPrsiticLossesPercentTorque 125;
BA_ "SPN" SG_ 2566840318 EstEngPrsiticLossesPercentTorque 2978;
BA_ "SigType" SG_ 2566840318 EngnsDsrdOprtngSpdAsymmtryAdjstm 1;
BA_ "SPN" SG_ 2566840318 EngnsDsrdOprtngSpdAsymmtryAdjstm 519;
BA_ "SigType" SG_ 2566840318 EnginesDesiredOperatingSpeed 1;
BA_ "SPN" SG_ 2566840318 EnginesDesiredOperatingSpeed 515;
BA_ "SigType" SG_ 2566840318 NominalFrictionPercentTorque 1;
BA_ "SPN" SG_ 2566840318 NominalFrictionPercentTorque 514;
BA_ "SigType" SG_ 2364539902 EstPumpingPercentTorque 1;
BA_ "SPN" SG_ 2364539902 EstPumpingPercentTorque 5398;
BA_ "SigType" SG_ 2364539902 ActlMaxAvailableEngPercentTorque 1;
BA_ "SPN" SG_ 2364539902 ActlMaxAvailableEngPercentTorque 3357;
BA_ "SigType" SG_ 2364539902 SCRThermalManagementActive 5;
BA_ "SPN" SG_ 2364539902 SCRThermalManagementActive 5400;
BA_ "SigType" SG_ 2364539902 DPFThermalManagementActive 5;
BA_ "SPN" SG_ 2364539902 DPFThermalManagementActive 5399;
BA_ "SigType" SG_ 2364539902 MmntaryEngMaxPowerEnableFeedback 5;
BA_ "SPN" SG_ 2364539902 MmntaryEngMaxPowerEnableFeedback 5021;
BA_ "SigType" SG_ 2364539902 VhcleAccelerationRateLimitStatus 5;
BA_ "SPN" SG_ 2364539902 VhcleAccelerationRateLimitStatus 2979;
BA_ "SigType" SG_ 2364539902 AccelPedalPos2 1;
BA_ "SPN" SG_ 2364539902 AccelPedalPos2 29;
BA_ "SigType" SG_ 2364539902 RemoteAccelPedalPos 1;
BA_ "SPN" SG_ 2364539902 RemoteAccelPedalPos 974;
BA_ "SigType" SG_ 2364539902 EngPercentLoadAtCurrentSpeed 1;
BA_ "SPN" SG_ 2364539902 EngPercentLoadAtCurrentSpeed 92;
BA_ "SigType" SG_ 2364539902 AccelPedalPos1 1;
BA_ "SPN" SG_ 2364539902 AccelPedalPos1 91;
BA_ "SigType" SG_ 2364539902 AccelPedal2LowIdleSwitch 4;
BA_ "SPN" SG_ 2364539902 AccelPedal2LowIdleSwitch 2970;
BA_ "SigType" SG_ 2364539902 RoadSpeedLimitStatus 5;
BA_ "SPN" SG_ 2364539902 RoadSpeedLimitStatus 1437;
BA_ "SigType" SG_ 2364539902 AccelPedalKickdownSwitch 4;
BA_ "SPN" SG_ 2364539902 AccelPedalKickdownSwitch 559;
BA_ "SigType" SG_ 2364539902 AccelPedal1LowIdleSwitch 4;
BA_ "SPN" SG_ 2364539902 AccelPedal1LowIdleSwitch 558;
BA_ "SigType" SG_ 2364540158 EngDemandPercentTorque 1;
BA_ "SPN" SG_ 2364540158 EngDemandPercentTorque 2432;
BA_ "SPN" SG_ 2364540158 EngStarterMode 1675;
BA_ "SPN" SG_ 2364540158 SrcAddrssOfCntrllngDvcForEngCtrl 1483;
BA_ "SigType" SG_ 2364540158 EngSpeed 1;
BA_ "SPN" SG_ 2364540158 EngSpeed 190;
BA_ "SigType" SG_ 2364540158 ActualEngPercentTorque 1;
BA_ "GenSigStartValue" SG_ 2364540158 ActualEngPercentTorque 125;
BA_ "SPN" SG_ 2364540158 ActualEngPercentTorque 513;
BA_ "SigType" SG_ 2364540158 DriversDemandEngPercentTorque 1;
BA_ "GenSigStartValue" SG_ 2364540158 DriversDemandEngPercentTorque 125;
BA_ "SPN" SG_ 2364540158 DriversDemandEngPercentTorque 512;
BA_ "SPN" SG_ 2364540158 ActlEngPrcntTorqueHighResolution 4154;
BA_ "SPN" SG_ 2364540158 EngTorqueMode 899;
BA_ "SigType" SG_ 2566768126 DateOfManufacture 8;
BA_ "SPN" SG_ 2566768126 DateOfManufacture 11746;
BA_ "SigType" SG_ 2566768126 ECUHardwareID 8;
BA_ "SPN" SG_ 2566768126 ECUHardwareID 6714;
BA_ "SigType" SG_ 2566768126 ECUManufacturerName 8;
BA_ "SPN" SG_ 2566768126 ECUManufacturerName 4304;
BA_ "SigType" SG_ 2566768126 ECUType 8;
BA_ "SPN" SG_ 2566768126 ECUType 2904;
BA_ "SigType" SG_ 2566768126 ECULocation 8;
BA_ "SPN" SG_ 2566768126 ECULocation 2903;
BA_ "SigType" SG_ 2566768126 ECUSerialNumber 8;
BA_ "SPN" SG_ 2566768126 ECUSerialNumber 2902;
BA_ "SigType" SG_ 2566768126 ECUPartNumber 8;
BA_ "SPN" SG_ 2566768126 ECUPartNumber 2901;
BA_ "SigType" SG_ 2566804734 EngMinContinuousTorque 1;
BA_ "SPN" SG_ 2566804734 EngMinContinuousTorque 1775;
BA_ "SigType" SG_ 2566804734 EngMaxContinuousTorque 1;
BA_ "SPN" SG_ 2566804734 EngMaxContinuousTorque 1774;
BA_ "SigType" SG_ 2566804734 EngMinContinuousRPM 1;
BA_ "SPN" SG_ 2566804734 EngMinContinuousRPM 1773;
BA_ "SigType" SG_ 2566804734 EngMaxContinuousRPM 1;
BA_ "SPN" SG_ 2566804734 EngMaxContinuousRPM 1772;
BA_ "SigType" SG_ 2566804734 EngHghLmtThrshldFrMnCntnsTrqFrmE 1;
BA_ "SPN" SG_ 2566804734 EngHghLmtThrshldFrMnCntnsTrqFrmE 1771;
BA_ "SigType" SG_ 2566804734 EngLwLmtThrshldFrMxTorqueFromEng 1;
BA_ "SPN" SG_ 2566804734 EngLwLmtThrshldFrMxTorqueFromEng 1770;
BA_ "SigType" SG_ 2566804734 EngHghLmtThrshldFrMnCntnusEngRPM 1;
BA_ "SPN" SG_ 2566804734 EngHghLmtThrshldFrMnCntnusEngRPM 1769;
BA_ "SigType" SG_ 2566804734 EngLwLmtThrsholdForMaxRPMFromEng 1;
BA_ "SPN" SG_ 2566804734 EngLwLmtThrsholdForMaxRPMFromEng 1768;
BA_ "SigType" SG_ 2566841342 DefaultIdleTrqLmt 1;
BA_ "GenSigStartValue" SG_ 2566841342 DefaultIdleTrqLmt 125;
BA_ "SPN" SG_ 2566841342 DefaultIdleTrqLmt 7828;
BA_ "SPN" SG_ 2566841342 SupportTSC1CtrlPurposeGroup4 3348;
BA_ "SPN" SG_ 2566841342 SupportTSC1CtrlPurposeGroup3 3347;
BA_ "SPN" SG_ 2566841342 SupportTSC1CtrlPurposeGroup2 3346;
BA_ "SPN" SG_ 2566841342 SupportTSC1CtrlPurposeGroup1 3345;
BA_ "SPN" SG_ 2566841342 SupportVariableRateTSC1Message 3344;
BA_ "SigType" SG_ 2566841342 EngDefaultTorqueLimit 1;
BA_ "SPN" SG_ 2566841342 EngDefaultTorqueLimit 1846;
BA_ "SigType" SG_ 2566841342 EngMomentOfInertia 1;
BA_ "SPN" SG_ 2566841342 EngMomentOfInertia 1794;
BA_ "SigType" SG_ 2566841342 EngExRngRqstdSpdCtrlRngUpprLimit 1;
BA_ "SPN" SG_ 2566841342 EngExRngRqstdSpdCtrlRngUpprLimit 1712;
BA_ "SigType" SG_ 2566841342 EngRqstdTrqueCtrlRangeUpperLimit 1;
BA_ "GenSigStartValue" SG_ 2566841342 EngRqstdTrqueCtrlRangeUpperLimit 125;
BA_ "SPN" SG_ 2566841342 EngRqstdTrqueCtrlRangeUpperLimit 538;
BA_ "SigType" SG_ 2566841342 EngRqstdTrqueCtrlRangeLowerLimit 1;
BA_ "GenSigStartValue" SG_ 2566841342 EngRqstdTrqueCtrlRangeLowerLimit 125;
BA_ "SPN" SG_ 2566841342 EngRqstdTrqueCtrlRangeLowerLimit 537;
BA_ "SigType" SG_ 2566841342 EngRqstdSpeedCtrlRangeUpperLimit 1;
BA_ "SPN" SG_ 2566841342 EngRqstdSpeedCtrlRangeUpperLimit 536;
BA_ "SigType" SG_ 2566841342 EngRqstdSpeedCtrlRangeLowerLimit 1;
BA_ "SPN" SG_ 2566841342 EngRqstdSpeedCtrlRangeLowerLimit 535;
BA_ "SigType" SG_ 2566841342 EngMaxMomentaryOverrideTimeLimit 1;
BA_ "SPN" SG_ 2566841342 EngMaxMomentaryOverrideTimeLimit 534;
BA_ "SigType" SG_ 2566841342 EngMxMmentaryOverrideSpeedPoint7 1;
BA_ "SPN" SG_ 2566841342 EngMxMmentaryOverrideSpeedPoint7 533;
BA_ "SigType" SG_ 2566841342 EngReferenceTorque 1;
BA_ "SPN" SG_ 2566841342 EngReferenceTorque 544;
BA_ "SigType" SG_ 2566841342 EngGain 1;
BA_ "SPN" SG_ 2566841342 EngGain 545;
BA_ "SigType" SG_ 2566841342 EngSpeedAtHighIdlePoint6 1;
BA_ "SPN" SG_ 2566841342 EngSpeedAtHighIdlePoint6 532;
BA_ "SigType" SG_ 2566841342 EngPercentTorqueAtPoint5 1;
BA_ "GenSigStartValue" SG_ 2566841342 EngPercentTorqueAtPoint5 125;
BA_ "SPN" SG_ 2566841342 EngPercentTorqueAtPoint5 543;
BA_ "SigType" SG_ 2566841342 EngSpeedAtPoint5 1;
BA_ "SPN" SG_ 2566841342 EngSpeedAtPoint5 531;
BA_ "SigType" SG_ 2566841342 EngPercentTorqueAtPoint4 1;
BA_ "GenSigStartValue" SG_ 2566841342 EngPercentTorqueAtPoint4 125;
BA_ "SPN" SG_ 2566841342 EngPercentTorqueAtPoint4 542;
BA_ "SigType" SG_ 2566841342 EngSpeedAtPoint4 1;
BA_ "SPN" SG_ 2566841342 EngSpeedAtPoint4 530;
BA_ "SigType" SG_ 2566841342 EngPercentTorqueAtPoint3 1;
BA_ "GenSigStartValue" SG_ 2566841342 EngPercentTorqueAtPoint3 125;
BA_ "SPN" SG_ 2566841342 EngPercentTorqueAtPoint3 541;
BA_ "SigType" SG_ 2566841342 EngSpeedAtPoint3 1;
BA_ "SPN" SG_ 2566841342 EngSpeedAtPoint3 529;
BA_ "SigType" SG_ 2566841342 EngPercentTorqueAtPoint2 1;
BA_ "GenSigStartValue" SG_ 2566841342 EngPercentTorqueAtPoint2 125;
BA_ "SPN" SG_ 2566841342 EngPercentTorqueAtPoint2 540;
BA_ "SigType" SG_ 2566841342 EngSpeedAtPoint2 1;
BA_ "SPN" SG_ 2566841342 EngSpeedAtPoint2 528;
BA_ "SigType" SG_ 2566841342 EngPercentTorqueAtIdlePoint1 1;
BA_ "GenSigStartValue" SG_ 2566841342 EngPercentTorqueAtIdlePoint1 125;
BA_ "SPN" SG_ 2566841342 EngPercentTorqueAtIdlePoint1 539;
BA_ "SigType" SG_ 2566841342 EngSpeedAtIdlePoint1 1;
BA_ "SPN" SG_ 2566841342 EngSpeedAtIdlePoint1 188;
BA_ "SigType" SG_ 2566767870 OverallIntendedBrkAcceleration 1;
BA_ "SPN" SG_ 2566767870 OverallIntendedBrkAcceleration 20784;
BA_ "SigType" SG_ 2566767870 DriverBrkDemand 1;
BA_ "SPN" SG_ 2566767870 DriverBrkDemand 20783;
BA_ "SPN" SG_ 2566767870 XBRBrkHoldMode 15264;
BA_ "SigType" SG_ 2566767870 RailroadMode 5;
BA_ "SPN" SG_ 2566767870 RailroadMode 7942;
BA_ "SigType" SG_ 2566767870 EmergencyBrakingActive 5;
BA_ "SPN" SG_ 2566767870 EmergencyBrakingActive 5847;
BA_ "SigType" SG_ 2566767870 PrkngBrakeActuatorFullyActivated 4;
BA_ "SPN" SG_ 2566767870 PrkngBrakeActuatorFullyActivated 5275;
BA_ "SigType" SG_ 2566767870 XBRAccelerationLimit 1;
BA_ "GenSigStartValue" SG_ 2566767870 XBRAccelerationLimit 25;
BA_ "SPN" SG_ 2566767870 XBRAccelerationLimit 2921;
BA_ "SPN" SG_ 2566767870 XBRActiveCtrlMode 2918;
BA_ "SigType" SG_ 2566767870 XBRSystemState 5;
BA_ "SPN" SG_ 2566767870 XBRSystemState 2917;
BA_ "SigType" SG_ 2566767870 FoundationBrakeUse 5;
BA_ "SPN" SG_ 2566767870 FoundationBrakeUse 2919;
BA_ "SPN" SG_ 2566767870 HillHolderMode 2912;
BA_ "SPN" SG_ 2566767870 HaltBrakeMode 2913;
BA_ "SigType" SG_ 2566767870 BrakeTempWarning 5;
BA_ "SPN" SG_ 2566767870 BrakeTempWarning 3839;
BA_ "SigType" SG_ 2633936126 BrkLnngRmningRearAxle3RightWheel 1;
BA_ "SPN" SG_ 2633936126 BrkLnngRmningRearAxle3RightWheel 1106;
BA_ "SigType" SG_ 2633936126 BrkLnngRminingRearAxle3LeftWheel 1;
BA_ "SPN" SG_ 2633936126 BrkLnngRminingRearAxle3LeftWheel 1105;
BA_ "SigType" SG_ 2633936126 BrkLnngRmningRearAxle2RightWheel 1;
BA_ "SPN" SG_ 2633936126 BrkLnngRmningRearAxle2RightWheel 1104;
BA_ "SigType" SG_ 2633936126 BrkLnngRminingRearAxle2LeftWheel 1;
BA_ "SPN" SG_ 2633936126 BrkLnngRminingRearAxle2LeftWheel 1103;
BA_ "SigType" SG_ 2633936126 BrkLnngRmningRearAxle1RightWheel 1;
BA_ "SPN" SG_ 2633936126 BrkLnngRmningRearAxle1RightWheel 1102;
BA_ "SigType" SG_ 2633936126 BrkLnngRminingRearAxle1LeftWheel 1;
BA_ "SPN" SG_ 2633936126 BrkLnngRminingRearAxle1LeftWheel 1101;
BA_ "SigType" SG_ 2633936126 BrkLnngRmningFrontAxleRightWheel 1;
BA_ "SPN" SG_ 2633936126 BrkLnngRmningFrontAxleRightWheel 1100;
BA_ "SigType" SG_ 2633936126 BrkLnngRminingFrontAxleLeftWheel 1;
BA_ "SPN" SG_ 2633936126 BrkLnngRminingFrontAxleLeftWheel 1099;
BA_ "SigType" SG_ 2566827518 BrkAppPrssHghRngRrAxl3RightWheel 1;
BA_ "SPN" SG_ 2566827518 BrkAppPrssHghRngRrAxl3RightWheel 1098;
BA_ "SigType" SG_ 2566827518 BrkAppPrssHghRngRrAxle3LeftWheel 1;
BA_ "SPN" SG_ 2566827518 BrkAppPrssHghRngRrAxle3LeftWheel 1097;
BA_ "SigType" SG_ 2566827518 BrkAppPrssHghRngRrAxl2RightWheel 1;
BA_ "SPN" SG_ 2566827518 BrkAppPrssHghRngRrAxl2RightWheel 1096;
BA_ "SigType" SG_ 2566827518 BrkAppPrssHghRngRrAxle2LeftWheel 1;
BA_ "SPN" SG_ 2566827518 BrkAppPrssHghRngRrAxle2LeftWheel 1095;
BA_ "SigType" SG_ 2566827518 BrkAppPrssHghRngRrAxle1LeftWheel 1;
BA_ "SPN" SG_ 2566827518 BrkAppPrssHghRngRrAxle1LeftWheel 1093;
BA_ "SigType" SG_ 2566827518 BrkAppPrssHghRngFrntAxlRghtWheel 1;
BA_ "SPN" SG_ 2566827518 BrkAppPrssHghRngFrntAxlRghtWheel 1092;
BA_ "SigType" SG_ 2566827518 BrkAppPrssHghRngFrntAxlLeftWheel 1;
BA_ "SPN" SG_ 2566827518 BrkAppPrssHghRngFrntAxlLeftWheel 1091;
BA_ "SigType" SG_ 2566827518 BrkAppPrssHghRngRrAxl1RightWheel 1;
BA_ "SPN" SG_ 2566827518 BrkAppPrssHghRngRrAxl1RightWheel 1094;
BA_ "SigType" SG_ 2566832126 RelativeSpeedRearAxle2RightWheel 1;
BA_ "SPN" SG_ 2566832126 RelativeSpeedRearAxle2RightWheel 910;
BA_ "SigType" SG_ 2566832126 RelativeSpeedRearAxle2LeftWheel 1;
BA_ "SPN" SG_ 2566832126 RelativeSpeedRearAxle2LeftWheel 909;
BA_ "SigType" SG_ 2566832126 RelativeSpeedRearAxle1RightWheel 1;
BA_ "SPN" SG_ 2566832126 RelativeSpeedRearAxle1RightWheel 908;
BA_ "SigType" SG_ 2566832126 RelativeSpeedRearAxle1LeftWheel 1;
BA_ "SPN" SG_ 2566832126 RelativeSpeedRearAxle1LeftWheel 907;
BA_ "SigType" SG_ 2566832126 RelativeSpeedFrontAxleRightWheel 1;
BA_ "SPN" SG_ 2566832126 RelativeSpeedFrontAxleRightWheel 906;
BA_ "SigType" SG_ 2566832126 RelativeSpeedFrontAxleLeftWheel 1;
BA_ "SPN" SG_ 2566832126 RelativeSpeedFrontAxleLeftWheel 905;
BA_ "SigType" SG_ 2566832126 FrontAxleSpeed 1;
BA_ "SPN" SG_ 2566832126 FrontAxleSpeed 904;
BA_ "SigType" SG_ 2565865982 RailroadModeSw 4;
BA_ "SPN" SG_ 2565865982 RailroadModeSw 7941;
BA_ "SigType" SG_ 2565865982 TrctrMntdTrailerABSWarningSignal 5;
BA_ "SPN" SG_ 2565865982 TrctrMntdTrailerABSWarningSignal 1792;
BA_ "SigType" SG_ 2565865982 TrailerABSStatus 5;
BA_ "SPN" SG_ 2565865982 TrailerABSStatus 1836;
BA_ "SigType" SG_ 2565865982 HaltBrakeSwitch 4;
BA_ "SPN" SG_ 2565865982 HaltBrakeSwitch 2911;
BA_ "SPN" SG_ 2565865982 SrcAddrssOfCntrllngDvcFrBrkeCtrl 1481;
BA_ "SigType" SG_ 2565865982 ATC_ASRInformationSignal 5;
BA_ "SPN" SG_ 2565865982 ATC_ASRInformationSignal 1793;
BA_ "SigType" SG_ 2565865982 ABS_EBSAmberWarningSignal 5;
BA_ "SPN" SG_ 2565865982 ABS_EBSAmberWarningSignal 1438;
BA_ "SigType" SG_ 2565865982 EBSRedWarningSignal 5;
BA_ "SPN" SG_ 2565865982 EBSRedWarningSignal 1439;
BA_ "SigType" SG_ 2565865982 ABSFullyOperational 5;
BA_ "SPN" SG_ 2565865982 ABSFullyOperational 1243;
BA_ "SigType" SG_ 2565865982 EngRetarderSelection 1;
BA_ "SPN" SG_ 2565865982 EngRetarderSelection 973;
BA_ "SigType" SG_ 2565865982 RemoteAccelEnableSwitch 4;
BA_ "SPN" SG_ 2565865982 RemoteAccelEnableSwitch 969;
BA_ "SigType" SG_ 2565865982 EngAuxShutdownSwitch 4;
BA_ "SPN" SG_ 2565865982 EngAuxShutdownSwitch 970;
BA_ "SigType" SG_ 2565865982 EngDerateSwitch 4;
BA_ "SPN" SG_ 2565865982 EngDerateSwitch 971;
BA_ "SigType" SG_ 2565865982 AccelInterlockSwitch 4;
BA_ "SPN" SG_ 2565865982 AccelInterlockSwitch 972;
BA_ "SigType" SG_ 2565865982 TractionCtrlOverrideSwitch 4;
BA_ "SPN" SG_ 2565865982 TractionCtrlOverrideSwitch 1238;
BA_ "SigType" SG_ 2565865982 ASRHillHolderSwitch 4;
BA_ "SPN" SG_ 2565865982 ASRHillHolderSwitch 577;
BA_ "SigType" SG_ 2565865982 ASROffroadSwitch 4;
BA_ "SPN" SG_ 2565865982 ASROffroadSwitch 576;
BA_ "SigType" SG_ 2565865982 ABSOffroadSwitch 4;
BA_ "SPN" SG_ 2565865982 ABSOffroadSwitch 575;
BA_ "SigType" SG_ 2565865982 BrakePedalPos 1;
BA_ "SPN" SG_ 2565865982 BrakePedalPos 521;
BA_ "SigType" SG_ 2565865982 EBSBrakeSwitch 4;
BA_ "SPN" SG_ 2565865982 EBSBrakeSwitch 1121;
BA_ "SigType" SG_ 2565865982 AntiLockBrakingActive 5;
BA_ "SPN" SG_ 2565865982 AntiLockBrakingActive 563;
BA_ "SigType" SG_ 2565865982 ASRBrakeCtrlActive 5;
BA_ "SPN" SG_ 2565865982 ASRBrakeCtrlActive 562;
BA_ "SigType" SG_ 2565865982 ASREngCtrlActive 5;
BA_ "SPN" SG_ 2565865982 ASREngCtrlActive 561;
BA_ "SigType" SG_ 2565867262 DogClutchRearAxle2 4;
BA_ "SPN" SG_ 2565867262 DogClutchRearAxle2 12285;
BA_ "SigType" SG_ 2565867262 DiffLockStRearAxle3 5;
BA_ "SPN" SG_ 2565867262 DiffLockStRearAxle3 7716;
BA_ "SigType" SG_ 2565867262 RearAxleGroupEngagementStatus 5;
BA_ "SPN" SG_ 2565867262 RearAxleGroupEngagementStatus 3820;
BA_ "SigType" SG_ 2565867262 FrontAxleGroupEngagementStatus 5;
BA_ "SPN" SG_ 2565867262 FrontAxleGroupEngagementStatus 3819;
BA_ "SigType" SG_ 2565867262 DiffLockStateCentralRear 5;
BA_ "SPN" SG_ 2565867262 DiffLockStateCentralRear 566;
BA_ "SigType" SG_ 2565867262 DiffLockStateCentralFront 5;
BA_ "SPN" SG_ 2565867262 DiffLockStateCentralFront 565;
BA_ "SigType" SG_ 2565867262 DiffLockStateCentral 5;
BA_ "SPN" SG_ 2565867262 DiffLockStateCentral 564;
BA_ "SigType" SG_ 2565867262 DiffLockStateRearAxle2 5;
BA_ "SPN" SG_ 2565867262 DiffLockStateRearAxle2 570;
BA_ "SigType" SG_ 2565867262 DiffLockStateRearAxle1 5;
BA_ "SPN" SG_ 2565867262 DiffLockStateRearAxle1 569;
BA_ "SigType" SG_ 2565867262 DiffLockStateFrontAxle2 5;
BA_ "SPN" SG_ 2565867262 DiffLockStateFrontAxle2 568;
BA_ "SigType" SG_ 2565867262 DiffLockStateFrontAxle1 5;
BA_ "SPN" SG_ 2565867262 DiffLockStateFrontAxle1 567;
BA_ "SPN" SG_ 2565867262 Location 927;
BA_ "SigType" SG_ 2566821118 AftercoolerCoolantOutPress 1;
BA_ "SPN" SG_ 2566821118 AftercoolerCoolantOutPress 15237;
BA_ "SigType" SG_ 2566821118 SeaWaterPumpOutPress2 1;
BA_ "SPN" SG_ 2566821118 SeaWaterPumpOutPress2 12893;
BA_ "SigType" SG_ 2566821118 CPCoolantOutPress 1;
BA_ "SPN" SG_ 2566821118 CPCoolantOutPress 8473;
BA_ "SigType" SG_ 2566821118 EngCoolantPress2 1;
BA_ "SPN" SG_ 2566821118 EngCoolantPress2 7313;
BA_ "SigType" SG_ 2566821118 EngExRangeCoolantPress 1;
BA_ "SPN" SG_ 2566821118 EngExRangeCoolantPress 20;
BA_ "SigType" SG_ 2566821118 SeaWaterPumpOutletPress 1;
BA_ "SPN" SG_ 2566821118 SeaWaterPumpOutletPress 2435;
BA_ "SigType" SG_ 2566821118 EngAuxCoolantTemp 1;
BA_ "SPN" SG_ 2566821118 EngAuxCoolantTemp 1212;
BA_ "SigType" SG_ 2566821118 EngAuxCoolantPress 1;
BA_ "SPN" SG_ 2566821118 EngAuxCoolantPress 1203;
BA_ "SigType" SG_ 2566810622 Driver2Identification 8;
BA_ "SPN" SG_ 2566810622 Driver2Identification 1626;
BA_ "SigType" SG_ 2566810622 Driver1Identification 8;
BA_ "SPN" SG_ 2566810622 Driver1Identification 1625;
BA_ "SigType" SG_ 2566847742 EngOilFilterDiffPress7471 1;
BA_ "SPN" SG_ 2566847742 EngOilFilterDiffPress7471 7471;
BA_ "SigType" SG_ 2566847742 FuelLevel2 1;
BA_ "SPN" SG_ 2566847742 FuelLevel2 38;
BA_ "SigType" SG_ 2566847742 CargoAmbientTemp 1;
BA_ "SPN" SG_ 2566847742 CargoAmbientTemp 169;
BA_ "SigType" SG_ 2566847742 EngOilFilterDiffPress 1;
BA_ "SPN" SG_ 2566847742 EngOilFilterDiffPress 99;
BA_ "SigType" SG_ 2566847742 EngFuelFilterDiffPress 1;
BA_ "SPN" SG_ 2566847742 EngFuelFilterDiffPress 95;
BA_ "SigType" SG_ 2566847742 FuelLevel1 1;
BA_ "SPN" SG_ 2566847742 FuelLevel1 96;
BA_ "SigType" SG_ 2566847742 WasherFluidLevel 1;
BA_ "SPN" SG_ 2566847742 WasherFluidLevel 80;
BA_ "SigType" SG_ 2498778622 EngCyl8AverageCombustionDuration 1;
BA_ "SPN" SG_ 2498778622 EngCyl8AverageCombustionDuration 6514;
BA_ "SigType" SG_ 2498778622 EngCyl8AvrgCntrOfCmbustionTiming 1;
BA_ "SPN" SG_ 2498778622 EngCyl8AvrgCntrOfCmbustionTiming 6513;
BA_ "SigType" SG_ 2498778622 EngCyl8AvrgStrtOfCmbustionTiming 1;
BA_ "SPN" SG_ 2498778622 EngCyl8AvrgStrtOfCmbustionTiming 6512;
BA_ "SigType" SG_ 2498778622 EngCyl8IndctedMeanEffectivePress 1;
BA_ "SPN" SG_ 2498778622 EngCyl8IndctedMeanEffectivePress 6511;
BA_ "SigType" SG_ 2498778366 EngCyl7AverageCombustionDuration 1;
BA_ "SPN" SG_ 2498778366 EngCyl7AverageCombustionDuration 6510;
BA_ "SigType" SG_ 2498778366 EngCyl7AvrgCntrOfCmbustionTiming 1;
BA_ "SPN" SG_ 2498778366 EngCyl7AvrgCntrOfCmbustionTiming 6509;
BA_ "SigType" SG_ 2498778366 EngCyl7AvrgStrtOfCmbustionTiming 1;
BA_ "SPN" SG_ 2498778366 EngCyl7AvrgStrtOfCmbustionTiming 6508;
BA_ "SigType" SG_ 2498778366 EngCyl7IndctedMeanEffectivePress 1;
BA_ "SPN" SG_ 2498778366 EngCyl7IndctedMeanEffectivePress 6507;
BA_ "SigType" SG_ 2498778110 EngCyl6AverageCombustionDuration 1;
BA_ "SPN" SG_ 2498778110 EngCyl6AverageCombustionDuration 6506;
BA_ "SigType" SG_ 2498778110 EngCyl6AvrgCntrOfCmbustionTiming 1;
BA_ "SPN" SG_ 2498778110 EngCyl6AvrgCntrOfCmbustionTiming 6505;
BA_ "SigType" SG_ 2498778110 EngCyl6AvrgStrtOfCmbustionTiming 1;
BA_ "SPN" SG_ 2498778110 EngCyl6AvrgStrtOfCmbustionTiming 6504;
BA_ "SigType" SG_ 2498778110 EngCyl6IndctedMeanEffectivePress 1;
BA_ "SPN" SG_ 2498778110 EngCyl6IndctedMeanEffectivePress 6503;
BA_ "SigType" SG_ 2498777854 EngCyl5AverageCombustionDuration 1;
BA_ "SPN" SG_ 2498777854 EngCyl5AverageCombustionDuration 6502;
BA_ "SigType" SG_ 2498777854 EngCyl5AvrgCntrOfCmbustionTiming 1;
BA_ "SPN" SG_ 2498777854 EngCyl5AvrgCntrOfCmbustionTiming 6501;
BA_ "SigType" SG_ 2498777854 EngCyl5AvrgStrtOfCmbustionTiming 1;
BA_ "SPN" SG_ 2498777854 EngCyl5AvrgStrtOfCmbustionTiming 6500;
BA_ "SigType" SG_ 2498777854 EngCyl5IndctedMeanEffectivePress 1;
BA_ "SPN" SG_ 2498777854 EngCyl5IndctedMeanEffectivePress 6499;
BA_ "SigType" SG_ 2498777598 EngCyl4AverageCombustionDuration 1;
BA_ "SPN" SG_ 2498777598 EngCyl4AverageCombustionDuration 6498;
BA_ "SigType" SG_ 2498777598 EngCyl4AvrgCntrOfCmbustionTiming 1;
BA_ "SPN" SG_ 2498777598 EngCyl4AvrgCntrOfCmbustionTiming 6497;
BA_ "SigType" SG_ 2498777598 EngCyl4AvrgStrtOfCmbustionTiming 1;
BA_ "SPN" SG_ 2498777598 EngCyl4AvrgStrtOfCmbustionTiming 6496;
BA_ "SigType" SG_ 2498777598 EngCyl4IndctedMeanEffectivePress 1;
BA_ "SPN" SG_ 2498777598 EngCyl4IndctedMeanEffectivePress 6495;
BA_ "SigType" SG_ 2498777342 EngCyl3AverageCombustionDuration 1;
BA_ "SPN" SG_ 2498777342 EngCyl3AverageCombustionDuration 6494;
BA_ "SigType" SG_ 2498777342 EngCyl3AvrgCntrOfCmbustionTiming 1;
BA_ "SPN" SG_ 2498777342 EngCyl3AvrgCntrOfCmbustionTiming 6493;
BA_ "SigType" SG_ 2498777342 EngCyl3AvrgStrtOfCmbustionTiming 1;
BA_ "SPN" SG_ 2498777342 EngCyl3AvrgStrtOfCmbustionTiming 6492;
BA_ "SigType" SG_ 2498777342 EngCyl3IndctedMeanEffectivePress 1;
BA_ "SPN" SG_ 2498777342 EngCyl3IndctedMeanEffectivePress 6491;
BA_ "SigType" SG_ 2566768382 EngCldStrtFlIgniterRelayFeedback 4;
BA_ "SPN" SG_ 2566768382 EngCldStrtFlIgniterRelayFeedback 5550;
BA_ "SigType" SG_ 2566768382 EngColdStartFuelIgniterRelay 5;
BA_ "SPN" SG_ 2566768382 EngColdStartFuelIgniterRelay 5549;
BA_ "SigType" SG_ 2566768382 EngColdStartFuelIgniterCmd 1;
BA_ "SPN" SG_ 2566768382 EngColdStartFuelIgniterCmd 5548;
BA_ "SPN" SG_ 2566768382 EngStartEnableDevice2Config 2898;
BA_ "SPN" SG_ 2566768382 EngStartEnableDevice1Config 2899;
BA_ "SigType" SG_ 2566768382 EngStartEnableDevice2 5;
BA_ "SPN" SG_ 2566768382 EngStartEnableDevice2 1804;
BA_ "SigType" SG_ 2566768382 EngStartEnableDevice1 5;
BA_ "SPN" SG_ 2566768382 EngStartEnableDevice1 626;
BA_ "SigType" SG_ 2566811902 GrossCombinationConf 1;
BA_ "SPN" SG_ 2566811902 GrossCombinationConf 21792;
BA_ "SigType" SG_ 2566811902 PoweredVehicleWeight 1;
BA_ "SPN" SG_ 2566811902 PoweredVehicleWeight 1585;
BA_ "SigType" SG_ 2566811902 GrossCombinationVehicleWeight 1;
BA_ "SPN" SG_ 2566811902 GrossCombinationVehicleWeight 1760;
BA_ "SigType" SG_ 2563768062 MxCntinuousRetarderTorqueLimitRq 1;
BA_ "SPN" SG_ 2563768062 MxCntinuousRetarderTorqueLimitRq 1791;
BA_ "SigType" SG_ 2563768062 MnCntinuousRetarderTorqueLimitRq 1;
BA_ "SPN" SG_ 2563768062 MnCntinuousRetarderTorqueLimitRq 1790;
BA_ "SigType" SG_ 2563768062 MxContinuousRetarderSpeedLimitRq 1;
BA_ "SPN" SG_ 2563768062 MxContinuousRetarderSpeedLimitRq 1789;
BA_ "SigType" SG_ 2563768062 MnContinuousRetarderSpeedLimitRq 1;
BA_ "SPN" SG_ 2563768062 MnContinuousRetarderSpeedLimitRq 1788;
BA_ "SigType" SG_ 2563768062 EngTorqueLimitRqMaxContinuous 1;
BA_ "GenSigStartValue" SG_ 2563768062 EngTorqueLimitRqMaxContinuous 125;
BA_ "SPN" SG_ 2563768062 EngTorqueLimitRqMaxContinuous 1787;
BA_ "SigType" SG_ 2563768062 EngTorqueLimitRqMinContinuous 1;
BA_ "GenSigStartValue" SG_ 2563768062 EngTorqueLimitRqMinContinuous 125;
BA_ "SPN" SG_ 2563768062 EngTorqueLimitRqMinContinuous 1786;
BA_ "SigType" SG_ 2563768062 EngSpeedLimitRqMaxContinuous 1;
BA_ "SPN" SG_ 2563768062 EngSpeedLimitRqMaxContinuous 1785;
BA_ "SigType" SG_ 2563768062 EngSpeedLimitRqMinContinuous 1;
BA_ "SPN" SG_ 2563768062 EngSpeedLimitRqMinContinuous 1784;
BA_ "SigType" SG_ 2633924862 EngAverageCombustionTime 1;
BA_ "SPN" SG_ 2633924862 EngAverageCombustionTime 1465;
BA_ "SigType" SG_ 2633924862 EngDesiredCombustionTime 1;
BA_ "SPN" SG_ 2633924862 EngDesiredCombustionTime 1464;
BA_ "SigType" SG_ 2633924606 EngCyl20CombustionTime 1;
BA_ "SPN" SG_ 2633924606 EngCyl20CombustionTime 1463;
BA_ "SigType" SG_ 2633924606 EngCyl19CombustionTime 1;
BA_ "SPN" SG_ 2633924606 EngCyl19CombustionTime 1462;
BA_ "SigType" SG_ 2633924606 EngCyl18CombustionTime 1;
BA_ "SPN" SG_ 2633924606 EngCyl18CombustionTime 1461;
BA_ "SigType" SG_ 2633924606 EngCyl17CombustionTime 1;
BA_ "SPN" SG_ 2633924606 EngCyl17CombustionTime 1460;
BA_ "SigType" SG_ 2633924350 EngCyl16CombustionTime 1;
BA_ "SPN" SG_ 2633924350 EngCyl16CombustionTime 1459;
BA_ "SigType" SG_ 2633924350 EngCyl15CombustionTime 1;
BA_ "SPN" SG_ 2633924350 EngCyl15CombustionTime 1458;
BA_ "SigType" SG_ 2633924350 EngCyl14CombustionTime 1;
BA_ "SPN" SG_ 2633924350 EngCyl14CombustionTime 1457;
BA_ "SigType" SG_ 2633924350 EngCyl13CombustionTime 1;
BA_ "SPN" SG_ 2633924350 EngCyl13CombustionTime 1456;
BA_ "SigType" SG_ 2633924094 EngCyl12CombustionTime 1;
BA_ "SPN" SG_ 2633924094 EngCyl12CombustionTime 1455;
BA_ "SigType" SG_ 2633924094 EngCyl11CombustionTime 1;
BA_ "SPN" SG_ 2633924094 EngCyl11CombustionTime 1454;
BA_ "SigType" SG_ 2633924094 EngCyl10CombustionTime 1;
BA_ "SPN" SG_ 2633924094 EngCyl10CombustionTime 1453;
BA_ "SigType" SG_ 2633924094 EngCyl9CombustionTime 1;
BA_ "SPN" SG_ 2633924094 EngCyl9CombustionTime 1452;
BA_ "SigType" SG_ 2633923838 EngCyl8CombustionTime 1;
BA_ "SPN" SG_ 2633923838 EngCyl8CombustionTime 1451;
BA_ "SigType" SG_ 2633923838 EngCyl7CombustionTime 1;
BA_ "SPN" SG_ 2633923838 EngCyl7CombustionTime 1450;
BA_ "SigType" SG_ 2633923838 EngCyl6CombustionTime 1;
BA_ "SPN" SG_ 2633923838 EngCyl6CombustionTime 1449;
BA_ "SigType" SG_ 2633923838 EngCyl5CombustionTime 1;
BA_ "SPN" SG_ 2633923838 EngCyl5CombustionTime 1448;
BA_ "SigType" SG_ 2633923582 EngCyl4CombustionTime 1;
BA_ "SPN" SG_ 2633923582 EngCyl4CombustionTime 1447;
BA_ "SigType" SG_ 2633923582 EngCyl3CombustionTime 1;
BA_ "SPN" SG_ 2633923582 EngCyl3CombustionTime 1446;
BA_ "SigType" SG_ 2633923582 EngCyl2CombustionTime 1;
BA_ "SPN" SG_ 2633923582 EngCyl2CombustionTime 1445;
BA_ "SigType" SG_ 2633923582 EngCyl1CombustionTime 1;
BA_ "SPN" SG_ 2633923582 EngCyl1CombustionTime 1444;
BA_ "SigType" SG_ 2633878014 TotalCountOfConfigChangesMade 1;
BA_ "SPN" SG_ 2633878014 TotalCountOfConfigChangesMade 2887;
BA_ "SPN" SG_ 2566771966 RemoteKeyFobFunctionReq 21139;
BA_ "SigType" SG_ 2566771966 OpKeySwOff 5;
BA_ "SPN" SG_ 2566771966 OpKeySwOff 21127;
BA_ "SigType" SG_ 2566771966 OpKeySwSvc 5;
BA_ "SPN" SG_ 2566771966 OpKeySwSvc 21126;
BA_ "SigType" SG_ 2566771966 EngAirShutoffManualSw 4;
BA_ "SPN" SG_ 2566771966 EngAirShutoffManualSw 13364;
BA_ "SigType" SG_ 2566771966 EngAirShutoffTestSw 4;
BA_ "SPN" SG_ 2566771966 EngAirShutoffTestSw 13363;
BA_ "SigType" SG_ 2566771966 HornSw 4;
BA_ "SPN" SG_ 2566771966 HornSw 2641;
BA_ "SigType" SG_ 2566771966 OpKeySwDelayedBatOff 4;
BA_ "SPN" SG_ 2566771966 OpKeySwDelayedBatOff 10147;
BA_ "SigType" SG_ 2566771966 OpKeySwStart 4;
BA_ "SPN" SG_ 2566771966 OpKeySwStart 10146;
BA_ "SigType" SG_ 2566771966 OpKeySwIgntPwr 4;
BA_ "SPN" SG_ 2566771966 OpKeySwIgntPwr 10145;
BA_ "SigType" SG_ 2566771966 OpKeySwAccessoryPwr 4;
BA_ "SPN" SG_ 2566771966 OpKeySwAccessoryPwr 3996;
BA_ "SigType" SG_ 2566771966 OpKeyDetected 4;
BA_ "SPN" SG_ 2566771966 OpKeyDetected 10144;
BA_ "SigType" SG_ 2566771966 MomentaryOpKeySw 4;
BA_ "SPN" SG_ 2566771966 MomentaryOpKeySw 9842;
BA_ "SPN" SG_ 2566771966 AFTSCRDosingModeCmd 9175;
BA_ "SigType" SG_ 2566771966 VehTrailerStatus 4;
BA_ "SPN" SG_ 2566771966 VehTrailerStatus 7711;
BA_ "SigType" SG_ 2566771966 TransOilLevelRq 5;
BA_ "SPN" SG_ 2566771966 TransOilLevelRq 3809;
BA_ "SigType" SG_ 2566771966 FifthWheelReleaseCtrl 4;
BA_ "SPN" SG_ 2566771966 FifthWheelReleaseCtrl 3314;
BA_ "SigType" SG_ 2566771966 FfthWhlRleaseCtrlSecurityLockout 4;
BA_ "SPN" SG_ 2566771966 FfthWhlRleaseCtrlSecurityLockout 3315;
BA_ "SPN" SG_ 2566771966 TransferCaseSelectorSwitch 2796;
BA_ "SigType" SG_ 2564882174 SelectedMaxVehicleSpeedLimit 1;
BA_ "SPN" SG_ 2564882174 SelectedMaxVehicleSpeedLimit 2596;
BA_ "SigType" SG_ 2564882174 RqCabZoneHeating 5;
BA_ "SPN" SG_ 2564882174 RqCabZoneHeating 1686;
BA_ "SigType" SG_ 2564882174 RqEngZoneHeating 5;
BA_ "SPN" SG_ 2564882174 RqEngZoneHeating 1685;
BA_ "SPN" SG_ 2564882174 AuxHeaterModeRq 1683;
BA_ "SigType" SG_ 2564882174 EngAutomaticStartEnableSwitch 4;
BA_ "SPN" SG_ 2564882174 EngAutomaticStartEnableSwitch 1656;
BA_ "SigType" SG_ 2564882174 AtomaticGearShiftingEnableSwitch 4;
BA_ "SPN" SG_ 2564882174 AtomaticGearShiftingEnableSwitch 1666;
BA_ "SigType" SG_ 2564882174 AFTRegenForceSw 4;
BA_ "SPN" SG_ 2564882174 AFTRegenForceSw 3696;
BA_ "SigType" SG_ 2564882174 AFTRegenInhSw 4;
BA_ "SPN" SG_ 2564882174 AFTRegenInhSw 3695;
BA_ "SigType" SG_ 2564882174 VhclLmtngSpdGovernorEnableSwitch 4;
BA_ "SPN" SG_ 2564882174 VhclLmtngSpdGovernorEnableSwitch 1653;
BA_ "SigType" SG_ 2564882174 VhclLmtngSpdGvrnrIncrementSwitch 4;
BA_ "SPN" SG_ 2564882174 VhclLmtngSpdGvrnrIncrementSwitch 1654;
BA_ "SigType" SG_ 2564882174 VhclLmtngSpdGvrnrDecrementSwitch 4;
BA_ "SPN" SG_ 2564882174 VhclLmtngSpdGvrnrDecrementSwitch 1655;
BA_ "SigType" SG_ 2564882174 ParkBrakeCmd 5;
BA_ "SPN" SG_ 2564882174 ParkBrakeCmd 5630;
BA_ "SigType" SG_ 2564882174 SeatBeltSwitch 4;
BA_ "SPN" SG_ 2564882174 SeatBeltSwitch 1856;
BA_ "SigType" SG_ 2564882174 OperatorSeatDirectionSwitch 4;
BA_ "SPN" SG_ 2564882174 OperatorSeatDirectionSwitch 1714;
BA_ "SigType" SG_ 2564882174 BatteryMainSwitchHoldRq 5;
BA_ "SPN" SG_ 2564882174 BatteryMainSwitchHoldRq 1682;
BA_ "SigType" SG_ 2564882174 AuxHeaterCoolantPumpRq 5;
BA_ "SPN" SG_ 2564882174 AuxHeaterCoolantPumpRq 1684;
BA_ "SigType" SG_ 2564882174 CabInteriorTempCmd 1;
BA_ "SPN" SG_ 2564882174 CabInteriorTempCmd 1691;
BA_ "SigType" SG_ 2564882174 RequestedPercentFanSpeed 1;
BA_ "SPN" SG_ 2564882174 RequestedPercentFanSpeed 986;
BA_ "SPN" SG_ 2563833598 OpDesDisplayModeCmd2 13080;
BA_ "SPN" SG_ 2563833598 OpDesDisplayModeCmd1 13079;
BA_ "SigType" SG_ 2563833598 SwtchBcklghtIllmntnBrghtnssPrcnt 1;
BA_ "SPN" SG_ 2563833598 SwtchBcklghtIllmntnBrghtnssPrcnt 5532;
BA_ "SigType" SG_ 2563833598 IlluminationBrightnessPercent 1;
BA_ "SPN" SG_ 2563833598 IlluminationBrightnessPercent 1487;
BA_ "SigType" SG_ 2563833598 SwtchIndctnIllmntnBrghtnssPrcent 1;
BA_ "SPN" SG_ 2563833598 SwtchIndctnIllmntnBrghtnssPrcent 6820;
BA_ "SigType" SG_ 2566843390 UnitNumber 8;
BA_ "SPN" SG_ 2566843390 UnitNumber 233;
BA_ "SigType" SG_ 2566843390 SerialNumber 8;
BA_ "SPN" SG_ 2566843390 SerialNumber 588;
BA_ "SigType" SG_ 2566843390 Model 8;
BA_ "SPN" SG_ 2566843390 Model 587;
BA_ "SigType" SG_ 2566843390 Make 8;
BA_ "SPN" SG_ 2566843390 Make 586;
BA_ "SigType" SG_ 2566844926 EngShutdownOverrideSwitch 4;
BA_ "SPN" SG_ 2566844926 EngShutdownOverrideSwitch 1237;
BA_ "SigType" SG_ 2566844926 EngTestModeSwitch 4;
BA_ "SPN" SG_ 2566844926 EngTestModeSwitch 966;
BA_ "SigType" SG_ 2566844926 EngIdleDecrementSwitch 4;
BA_ "SPN" SG_ 2566844926 EngIdleDecrementSwitch 967;
BA_ "SigType" SG_ 2566844926 EngIdleIncrementSwitch 4;
BA_ "SPN" SG_ 2566844926 EngIdleIncrementSwitch 968;
BA_ "SPN" SG_ 2566844926 CruiseCtrlStates 527;
BA_ "SPN" SG_ 2566844926 PTOGovernorState 976;
BA_ "SigType" SG_ 2566844926 CruiseCtrlSetSpeed 1;
BA_ "SPN" SG_ 2566844926 CruiseCtrlSetSpeed 86;
BA_ "SigType" SG_ 2566844926 CruiseCtrlAccelerateSwitch 4;
BA_ "SPN" SG_ 2566844926 CruiseCtrlAccelerateSwitch 602;
BA_ "SigType" SG_ 2566844926 CruiseCtrlResumeSwitch 4;
BA_ "SPN" SG_ 2566844926 CruiseCtrlResumeSwitch 601;
BA_ "SigType" SG_ 2566844926 CruiseCtrlCoastSwitch 4;
BA_ "SPN" SG_ 2566844926 CruiseCtrlCoastSwitch 600;
BA_ "SigType" SG_ 2566844926 CruiseCtrlSetSwitch 4;
BA_ "SPN" SG_ 2566844926 CruiseCtrlSetSwitch 599;
BA_ "SigType" SG_ 2566844926 ClutchSwitch 4;
BA_ "SPN" SG_ 2566844926 ClutchSwitch 598;
BA_ "SigType" SG_ 2566844926 BrakeSwitch 4;
BA_ "SPN" SG_ 2566844926 BrakeSwitch 597;
BA_ "SigType" SG_ 2566844926 CruiseCtrlEnableSwitch 4;
BA_ "SPN" SG_ 2566844926 CruiseCtrlEnableSwitch 596;
BA_ "SigType" SG_ 2566844926 CruiseCtrlActive 4;
BA_ "SPN" SG_ 2566844926 CruiseCtrlActive 595;
BA_ "SigType" SG_ 2566844926 WheelBasedVehicleSpeed 1;
BA_ "SPN" SG_ 2566844926 WheelBasedVehicleSpeed 84;
BA_ "SigType" SG_ 2566844926 ParkBrakeReleaseInhibitRq 5;
BA_ "SPN" SG_ 2566844926 ParkBrakeReleaseInhibitRq 3807;
BA_ "SigType" SG_ 2566844926 CruiseCtrlPauseSwitch 4;
BA_ "SPN" SG_ 2566844926 CruiseCtrlPauseSwitch 1633;
BA_ "SigType" SG_ 2566844926 ParkingBrakeSwitch 4;
BA_ "SPN" SG_ 2566844926 ParkingBrakeSwitch 70;
BA_ "SigType" SG_ 2566844926 TwoSpeedAxleSwitch 4;
BA_ "SPN" SG_ 2566844926 TwoSpeedAxleSwitch 69;
BA_ "SPN" SG_ 2566843902 PowertrainAdaptiveCCType 10294;
BA_ "SigType" SG_ 2566843902 CtrlSetCmdSupport 5;
BA_ "SPN" SG_ 2566843902 CtrlSetCmdSupport 10293;
BA_ "SigType" SG_ 2566843902 CtrlPauseCmdSupport 5;
BA_ "SPN" SG_ 2566843902 CtrlPauseCmdSupport 10292;
BA_ "SigType" SG_ 2566843902 CtrlResumeCmdSupport 5;
BA_ "SPN" SG_ 2566843902 CtrlResumeCmdSupport 10291;
BA_ "SigType" SG_ 2566843902 CtrlDisCmdSupport 5;
BA_ "SPN" SG_ 2566843902 CtrlDisCmdSupport 10290;
BA_ "SigType" SG_ 2566843902 CtrlSysLowSetLmtSpd 1;
BA_ "SPN" SG_ 2566843902 CtrlSysLowSetLmtSpd 10289;
BA_ "SigType" SG_ 2566843902 MaxVehicleSpeedLimit6808 1;
BA_ "SPN" SG_ 2566843902 MaxVehicleSpeedLimit6808 6808;
BA_ "SigType" SG_ 2566843902 CruiseCtrlLowSetLimitSpeed 1;
BA_ "SPN" SG_ 2566843902 CruiseCtrlLowSetLimitSpeed 88;
BA_ "SigType" SG_ 2566843902 CruiseCtrlHighSetLimitSpeed 1;
BA_ "SPN" SG_ 2566843902 CruiseCtrlHighSetLimitSpeed 87;
BA_ "SigType" SG_ 2566843902 MaxVehicleSpeedLimit 1;
BA_ "SPN" SG_ 2566843902 MaxVehicleSpeedLimit 74;
BA_ "SigType" SG_ 2566809598 AuxHeaterMaxOutputPower 1;
BA_ "SPN" SG_ 2566809598 AuxHeaterMaxOutputPower 1690;
BA_ "SigType" SG_ 2633940222 TripServiceBrakeApplications 1;
BA_ "SPN" SG_ 2633940222 TripServiceBrakeApplications 993;
BA_ "SigType" SG_ 2633940222 TripServiceBrakeDistance 1;
BA_ "SPN" SG_ 2633940222 TripServiceBrakeDistance 992;
BA_ "SigType" SG_ 2633940222 TripCompressionBrakeDistance 1;
BA_ "SPN" SG_ 2633940222 TripCompressionBrakeDistance 991;
BA_ "SigType" SG_ 2633940222 TotalCompressionBrakeDistance 1;
BA_ "SPN" SG_ 2633940222 TotalCompressionBrakeDistance 990;
VAL_ 2365446142 Joystick1Button13PressedStatus 3 "Not Available" 2 "Error Indicator" 1 "Button pressed" 0 "Button not pressed" ;
VAL_ 2365446142 Joystick1Button14PressedStatus 3 "Not Available" 2 "Error Indicator" 1 "Button pressed" 0 "Button not pressed" ;
VAL_ 2365446142 Joystick1Button15PressedStatus 3 "Not Available" 2 "Error Indicator" 1 "Button pressed" 0 "Button not pressed" ;
VAL_ 2365446142 Joystick1Button16PressedStatus 3 "Not Available" 2 "Error Indicator" 1 "Button pressed" 0 "Button not pressed" ;
VAL_ 2365446142 Jystick1GripXAxisDetentPosStatus 3 "Not Available" 2 "Error Indicator" 1 "In the Detent Position" 0 "Not in the Detent Position" ;
VAL_ 2365446142 Jystick1GripYAxisDetentPosStatus 3 "Not Available" 2 "Error Indicator" 1 "In the Detent Position" 0 "Not in the Detent Position" ;
VAL_ 2365446142 Jystick1ThetaAxisDetentPosStatus 3 "Not Available" 2 "Error Indicator" 1 "In the Detent Position" 0 "Not in the Detent Position" ;
VAL_ 2365446142 Jystck1ThtAxsClckwsPstvPosStatus 3 "Not Available" 2 "Error Indicator" 1 "On positive side of Neutral" 0 "Not on Positive side of Neutral" ;
VAL_ 2365446142 Jystck1ThetaAxisNeutralPosStatus 3 "Not Available" 2 "Error Indicator" 1 "In Neutral Position" 0 "Not in Neutral Position" ;
VAL_ 2365446142 Jystck1GrpYAxsLvrFrwrdPstvPsStts 3 "Not Available" 2 "Error Indicator" 1 "On positive side of Neutral" 0 "Not on Positive side of Neutral" ;
VAL_ 2365446142 Jystck1GrpYAxsLvrBckNgtvPsStatus 3 "Not Available" 2 "Error Indicator" 1 "On negative side of Neutral" 0 "Not on negative side of Neutral" ;
VAL_ 2365446142 Aftrtrtmnt1DslExhstFldPrprtsPrlm 3 "Not Available" 2 "Error Indicator" 1 "In Neutral Position" 0 "Not in Neutral Position" ;
VAL_ 2365446142 Jystck1GrpXAxsLvrRghtPstvPsSttus 3 "Not Available" 2 "Error Indicator" 1 "On positive side of Neutral" 0 "Not on Positive side of Neutral" ;
VAL_ 2365446142 Jystck1GrpXAxsLvrLftNgtvPsStatus 3 "Not Available" 2 "Error Indicator" 1 "On negative side of Neutral" 0 "Not on negative side of Neutral" ;
VAL_ 2365446142 Jystck1GripXAxisNeutralPosStatus 3 "Not Available" 2 "Error Indicator" 1 "In Neutral Position" 0 "Not in Neutral Position" ;
VAL_ 2365446142 Jystck1ThtAxsCntrClckwsNgtvPsStt 3 "Not Available" 2 "Error Indicator" 1 "On negative side of Neutral" 0 "Not on negative side of Neutral" ;
VAL_ 2566810366 FuelPrimingSt 3 "Not available or not installed" 2 "Unable to determine if sufficiently primed" 1 "Sufficiently primed" 0 "Not sufficiently primed" ;
VAL_ 2566810366 FuelPumpPrimerStatus 3 "Unavailable" 2 "Error" 1 "On" 0 "Off" ;
VAL_ 2566810366 EngVentilationStatus 7 "Not available or not installe" 6 "Not able to determine if sufficiently vented" 5 "Reserved for SAE assignment" 4 "Reserved for SAE assignment" 3 "Currently venting" 2 "Ventilation delay" 1 "Ventilation needed" 0 "Sufficiently vented" ;
VAL_ 2566810366 EngCoolantPreheatedState 3 "Not available or not installed" 2 "Unable to determine  engine coolant pre-heated sufficiently" 1 "Sufficiently pre-heated" 0 "Not sufficiently pre-heated" ;
VAL_ 2566810366 EngOilPreHeatedState 1 "Sufficiently pre-heated" 3 "Not available or not installed" 2 "Unable to determine if engine oil is pre-heated sufficiently" 0 "Not sufficiently pre-heated" ;
VAL_ 2566810366 EngOilPrimingState 3 "Not available or not installed" 2 "Unable to determine if sufficiently lubricated" 1 "Sufficiently lubricated" 0 "Not sufficiently lubricated" ;
VAL_ 2566810366 EngOilPrimingPumpSwitch 3 "Not available or not installed" 2 "Error" 1 "On" 0 "Off" ;
VAL_ 2633929726 SafetyWireStatus 3 "Not available" 2 "Error" 1 "Safety wire has been activated" 0 "Safety wire has not been activated" ;
VAL_ 2566772222 EngVriableGeometryTurbo1CtrlMode 3 "not available" 2 "SAE reserved" 1 "closed loop" 0 "open loop" ;
VAL_ 2566772222 EngFuelCtrlCtrlMode 3 "Not available" 2 "SAE reserved" 1 "Closed loop" 0 "Open loop" ;
VAL_ 2566772222 EngVrblGmtryTrbArCtrlShtoffValve 3 "Not available" 2 "Reserved" 1 "VGT Air Control Shutoff Valve is On" 0 "VGT Air Control Shutoff Valve is Off" ;
VAL_ 2633940734 EngIntakeManifoldPressCtrlMode 3 "Not available" 2 "SAE reserved" 1 "Closed loop" 0 "Open loop" ;
VAL_ 2633940734 EngRotationDirection 3 "Not Available" 2 "Unknown " 1 "ClockWise" 0 "CounterClockWise" ;
VAL_ 2566840318 A2ExhDewPoint 3 "Not available" 2 "Error" 1 "Exceeded the dew point" 0 "Not exceeded the dew point" ;
VAL_ 2566840318 A2InDewPoint 3 "Not available" 2 "Error" 1 "Exceeded the dew point" 0 "Not exceeded the dew point" ;
VAL_ 2566840318 A1ExhDewPoint 3 "Not available" 2 "Error" 1 "Exceeded the dew point" 0 "Not exceeded the dew point" ;
VAL_ 2566840318 A1InDewPoint 3 "Not available" 2 "Error" 1 "Exceeded the dew point" 0 "Not exceeded the dew point" ;
VAL_ 2364539902 SCRThermalManagementActive 3 "Don't care" 2 "Reserved" 1 "SCR Thermal Management is active" 0 "SCR Thermal Management is not active" ;
VAL_ 2364539902 DPFThermalManagementActive 3 "Don't care" 2 "Reserved" 1 "DPF Thermal Management is active" 0 "DPF Thermal Management is not active" ;
VAL_ 2364539902 MmntaryEngMaxPowerEnableFeedback 3 "don't care" 2 "reserved" 1 "supported" 0 "disabled" ;
VAL_ 2364539902 VhcleAccelerationRateLimitStatus 3 "Not available" 2 "Reserved" 1 "Limit active" 0 "Limit not active" ;
VAL_ 2364539902 AccelPedal2LowIdleSwitch 3 "Not available" 2 "Error" 1 "Accelerator pedal 2 in low idle condition" 0 "Accelerator pedal 2 not in low idle condition" ;
VAL_ 2364539902 RoadSpeedLimitStatus 3 "Not available" 2 "Error" 1 "Not Active" 0 "Active" ;
VAL_ 2364539902 AccelPedalKickdownSwitch 3 "Not available" 2 "Error" 1 "Kickdown active" 0 "Kickdown passive" ;
VAL_ 2364539902 AccelPedal1LowIdleSwitch 3 "Not available" 2 "Error" 1 "Accelerator pedal 1 in low idle condition" 0 "Accelerator pedal 1 not in low idle condition" ;
VAL_ 2364540158 EngStarterMode 15 "not available" 14 "error" 13 "error, legacy implementation only" 12 "starter inhibited" 11 "starter inhibited due to ignition key cycle required" 10 "starter inhibited due to active emissions control system condition" 9 "starter inhibited due to intake air shutoff valve being active" 8 "starter inhibited due to starter over-temp" 7 "starter inhibited due to active immobilizer" 6 "starter inhibited due to driveline engaged or other transmission inhibit" 5 "starter inhibited due to engine not ready for start" 4 "starter inhibited due to engine already running" 3 "start finished" 2 "starter active and engaged" 1 "starter active but not engaged" 0 "start not requested" ;
VAL_ 2364540158 ActlEngPrcntTorqueHighResolution 7 "+0.875%" 1 "+0.125%" 0 "+0.000%" ;
VAL_ 2566767870 XBRBrkHoldMode 15 "Not available" 14 "XBR Brake Hold not functional/error" 13 "Reserved" 12 "Reserved" 11 "Reserved" 10 "Reserved" 9 "Reserved" 8 "Reserved" 7 "Reserved" 6 "Reserved" 5 "XBR Brake Hold Request is not accepted due to boundary conditions not met" 4 "Active but restricted functionality due to faults detected" 3 "Active but may activate parking brake if needed" 2 "Active but will change to inactive in a short time" 1 "Active" 0 "Inactive" ;
VAL_ 2566767870 RailroadMode 3 "Not available" 2 "Error" 1 "Active" 0 "Inactive" ;
VAL_ 2566767870 EmergencyBrakingActive 3 "not available" 2 "reserved" 1 "active" 0 "inactive" ;
VAL_ 2566767870 PrkngBrakeActuatorFullyActivated 3 "Not available" 2 "Error" 1 "Parking Brake Actuator fully activated" 0 "Parking Brake Actuator not fully activated" ;
VAL_ 2566767870 XBRActiveCtrlMode 15 "Not available" 14 "Reserved for SAE assignment" 13 "Reserved for SAE assignment" 12 "Reserved for SAE assignment" 11 "Reserved for SAE assignment" 10 "Reserved for SAE assignment" 9 "Reserved for SAE assignment" 8 "Reserved for SAE assignment" 7 "Reserved for SAE assignment" 6 "Reserved for SAE assignment" 5 "Reserved for SAE assignment" 4 "XBR Brake Hold is being executed to hold the vehicle still based on XBR Brake Hold Request" 3 "Maximum mode of XBR acceleration control being executed" 2 "Addition mode of XBR acceleration control being executed" 1 "Driver's brake demand being executed" 0 "No brake demand being executed" ;
VAL_ 2566767870 XBRSystemState 3 "not available" 2 "No external brake demand will be accepted" 1 "Only external brake demand of highest XBR Priority" 0 "Any external brake demand will be accepted" ;
VAL_ 2566767870 FoundationBrakeUse 3 "Not available" 2 "Reserved" 1 "Foundation brakes in use" 0 "Foundation brakes not in use" ;
VAL_ 2566767870 HillHolderMode 7 "Not available" 6 "Hill holder not functional" 5 "Reserved" 4 "Reserved" 3 "Active,  but may activate parking brake if needed." 2 "Active,  but will change to inactive in a short time" 1 "Active" 0 "Inactive" ;
VAL_ 2566767870 HaltBrakeMode 7 "Not available" 6 "Halt brake not functional" 2 "Active,  but not functioning properly" 1 "Active" 0 "Inactive" ;
VAL_ 2566767870 BrakeTempWarning 3 "not available" 2 "Reserved" 1 "Active" 0 "Not Active" ;
VAL_ 2565865982 RailroadModeSw 3 "Not available" 2 "Error" 1 "Railroad mode switch active" 0 "Railroad mode switch passive" ;
VAL_ 2565865982 TrctrMntdTrailerABSWarningSignal 3 "Take no action" 2 "Reserved" 1 "On" 0 "Off" ;
VAL_ 2565865982 TrailerABSStatus 3 "Trailer ABS Status Information Not Available or Parameter Not Supported" 2 "Reserved" 1 "Trailer ABS Active" 0 "Trailer ABS Status Information Available But Not Active" ;
VAL_ 2565865982 HaltBrakeSwitch 3 "Not available" 2 "Error" 1 "Halt brake switch active" 0 "Halt brake switch passive" ;
VAL_ 2565865982 ATC_ASRInformationSignal 3 "Take no action" 2 "Reserved" 1 "On" 0 "Off" ;
VAL_ 2565865982 ABS_EBSAmberWarningSignal 3 "Take no action" 2 "Reserved" 1 "On" 0 "Off" ;
VAL_ 2565865982 EBSRedWarningSignal 3 "Take no action" 2 "Reserved" 1 "On" 0 "Off" ;
VAL_ 2565865982 ABSFullyOperational 3 "Not available" 2 "Reserved" 1 "Fully Operational" 0 "Not Fully Operational" ;
VAL_ 2565865982 RemoteAccelEnableSwitch 3 "Not available" 2 "Error" 1 "On" 0 "Off" ;
VAL_ 2565865982 EngAuxShutdownSwitch 3 "Not available" 2 "Error" 1 "On" 0 "Off" ;
VAL_ 2565865982 EngDerateSwitch 3 "Not available" 2 "Error" 1 "On" 0 "Off" ;
VAL_ 2565865982 AccelInterlockSwitch 3 "Not available" 2 "Error" 1 "On" 0 "Off" ;
VAL_ 2565865982 TractionCtrlOverrideSwitch 3 "Not available or not installed" 2 "Error" 1 "On" 0 "Off" ;
VAL_ 2565865982 ASRHillHolderSwitch 3 "Not available" 2 "Error" 1 "ASR 'hill holder' switch active" 0 "ASR 'hill holder' switch passive" ;
VAL_ 2565865982 ASROffroadSwitch 3 "Not available" 2 "Error" 1 "ASR off-road switch active" 0 "ASR off-road switch passive" ;
VAL_ 2565865982 ABSOffroadSwitch 3 "Not available" 2 "Error" 1 "ABS off-road switch active" 0 "ABS off-road switch passive" ;
VAL_ 2565865982 EBSBrakeSwitch 3 "Not available" 2 "Error" 1 "Brake pedal is being pressed" 0 "Brake pedal is not being pressed" ;
VAL_ 2565865982 AntiLockBrakingActive 3 "Not available" 2 "Reserved" 1 "ABS active" 0 "ABS passive but installed" ;
VAL_ 2565865982 ASRBrakeCtrlActive 3 "Not available" 2 "Reserved" 1 "ASR brake control active" 0 "ASR brake control passive but installed" ;
VAL_ 2565865982 ASREngCtrlActive 3 "Not available" 2 "Reserved" 1 "ASR engine control active" 0 "ASR engine control passive but installed" ;
VAL_ 2565867262 DogClutchRearAxle2 3 "Not Available" 2 "Error" 1 "Dog Clutch Rear Axle 2 Engaged" 0 "Dog Clutch Rear Axle 2 Disengaged" ;
VAL_ 2565867262 DiffLockStRearAxle3 1 "Differential lock engaged" 0 "Differential lock disengaged" 3 "Not available" 2 "Error" ;
VAL_ 2565867262 RearAxleGroupEngagementStatus 3 "not available" 2 "error" 1 "rear axle group engaged" 0 "rear axle group disengaged" ;
VAL_ 2565867262 FrontAxleGroupEngagementStatus 3 "not available" 2 "error" 1 "front axle group engaged" 0 "front axle group disengaged" ;
VAL_ 2565867262 DiffLockStateCentralRear 3 "Not available" 2 "Error" 1 "Differential lock engaged" 0 "Differential lock disengaged" ;
VAL_ 2565867262 DiffLockStateCentralFront 3 "Not available" 2 "Error" 1 "Differential lock engaged" 0 "Differential lock disengaged" ;
VAL_ 2565867262 DiffLockStateCentral 3 "Not available" 2 "Error" 1 "Differential lock engaged" 0 "Differential lock disengaged" ;
VAL_ 2565867262 DiffLockStateRearAxle2 3 "Not available" 2 "Error" 1 "Differential lock engaged" 0 "Differential lock disengaged" ;
VAL_ 2565867262 DiffLockStateRearAxle1 3 "Not available" 2 "Error" 1 "Differential lock engaged" 0 "Differential lock disengaged" ;
VAL_ 2565867262 DiffLockStateFrontAxle2 3 "Not available" 2 "Error" 1 "Differential lock engaged" 0 "Differential lock disengaged" ;
VAL_ 2565867262 DiffLockStateFrontAxle1 3 "Not available" 2 "Error" 1 "Differential lock engaged" 0 "Differential lock disengaged" ;
VAL_ 2566768382 EngCldStrtFlIgniterRelayFeedback 3 "Not available" 2 "Error" 1 "On" 0 "Off" ;
VAL_ 2566768382 EngColdStartFuelIgniterRelay 3 "Don't care/take no action" 2 "Reserved" 1 "On" 0 "Off" ;
VAL_ 2566768382 EngStartEnableDevice2Config 15 "not available" 4 "electric intake air heater installed" 3 "ether injection installed" 2 "fuelled start installed" 1 "glow plugs installed" 0 "no start enable device 2 installed" ;
VAL_ 2566768382 EngStartEnableDevice1Config 15 "not available" 4 "electric intake air heater installed" 3 "ether injection installed" 2 "fuelled start installed" 1 "glow plugs installed" 0 "no start enable device 1 installed" ;
VAL_ 2566768382 EngStartEnableDevice2 3 "not available" 2 "reserved" 1 "start enable ON" 0 "start enable OFF" ;
VAL_ 2566768382 EngStartEnableDevice1 3 "not available" 2 "reserved" 1 "start enable ON" 0 "start enable OFF" ;
VAL_ 2566771966 RemoteKeyFobFunctionReq 31 "Not Available" 30 "Error" 29 "Reserved" 28 "Reserved" 27 "Reserved" 26 "Reserved" 25 "Reserved" 24 "Reserved" 23 "Reserved" 22 "Reserved" 21 "Reserved" 20 "Locator Alarm" 19 "Panic Alarm" 18 "Power Top Stop" 17 "Power Top Pause" 16 "Power Top Close" 15 "Power Top Open" 14 "Window Close Request" 13 "Window Open Request" 12 "Mirror Fold Request" 11 "Mirror Unfold Request" 10 "Fuel Operated Heater Request On" 9 "Fuel Operated Heater Request Off" 8 "Power Rear Closure Stop Request" 7 "Power Rear Closure Start Request" 6 "Rear Closure Release Request" 5 "Front Closure Release Request" 4 "Stop Request" 3 "Start Request" 2 "Door Lock Request" 1 "Door Unlock Request" 0 "No Request" ;
VAL_ 2566771966 OpKeySwOff 3 "Not Available" 2 "Error" 1 "Off State" 0 "Non-Off State" ;
VAL_ 2566771966 OpKeySwSvc 3 "Not Available" 2 "Error" 1 "Service state is active" 0 "Service state is not active" ;
VAL_ 2566771966 EngAirShutoffManualSw 3 "Not available" 2 "Error" 1 "On" 0 "Off" ;
VAL_ 2566771966 EngAirShutoffTestSw 3 "Not available" 2 "Error" 1 "On" 0 "Off" ;
VAL_ 2566771966 HornSw 3 "Not Available" 2 "Error" 1 "Horn switch is on" 0 "Horn switch is off" ;
VAL_ 2566771966 OpKeySwDelayedBatOff 3 "Not Available" 2 "Error" 1 "Battery power will be removed after delay" 0 "Delayed battery off state not active" ;
VAL_ 2566771966 OpKeySwStart 3 "Not Available" 2 "Error" 1 "Start state is active" 0 "Start state is not active" ;
VAL_ 2566771966 OpKeySwIgntPwr 3 "Not Available" 2 "Error" 1 "Ignition state is active" 0 "Ignition state is not active" ;
VAL_ 2566771966 OpKeySwAccessoryPwr 3 "Not Available" 2 "Error" 1 "Accessory power state active" 0 "Accessory power state is not active" ;
VAL_ 2566771966 OpKeyDetected 3 "Not Available" 2 "Error" 1 "Key is detected" 0 "No key detected" ;
VAL_ 2566771966 MomentaryOpKeySw 3 "Not Available" 2 "Error" 1 "Button is depressed by the operator" 0 "Button is not depressed by the operator" ;
VAL_ 2566771966 AFTSCRDosingModeCmd 7 "Don't care/Take no Action" 6 "Reserved for status error value" 5 "Reserved" 4 "Reserved" 3 "Reserved" 2 "Reserved" 1 "Reduced SCR Dosing Mode" 0 "Standard SCR Dosing Mode" ;
VAL_ 2566771966 VehTrailerStatus 3 "Not available" 2 "Error" 1 "Trailer is detected" 0 "Trailer is not detected" ;
VAL_ 2566771966 TransOilLevelRq 3 "Don't care / take no action" 2 "Reserved" 1 "Transmission oil level reading desired" 0 "No transmission oil level reading desired" ;
VAL_ 2566771966 FifthWheelReleaseCtrl 3 "Not Available" 2 "Error" 1 "Coupler Unlocked" 0 "Coupler Locked" ;
VAL_ 2566771966 FfthWhlRleaseCtrlSecurityLockout 3 "Not Available" 2 "Error" 1 "Fifth wheel release Enabled" 0 "Fifth wheel release Disabled" ;
VAL_ 2566771966 TransferCaseSelectorSwitch 7 "Not available" 6 "Error indicator" 5 "Reserved for SAE assignment" 4 "4 wheel low" 3 "2 wheel low" 2 "Neutral" 1 "4 wheel high" 0 "2 wheel high" ;
VAL_ 2564882174 RqCabZoneHeating 3 "Don't care/take no action" 2 "Reserved" 1 "Heat cab zone" 0 "Do not heat cab engine zone" ;
VAL_ 2564882174 RqEngZoneHeating 3 "Don't care/take no action" 2 "Reserved" 1 "Heat engine zone" 0 "Do not heat engine zone" ;
VAL_ 2564882174 AuxHeaterModeRq 15 "Don't care/take no action" 14 "Reserved" 4 "Heater pump up-keep" 3 "Normal mode" 2 "Economy mode" 1 "Off due to ADR per European Regulations for Transport of hazardous materials" 0 "De-activate auxiliary heater" ;
VAL_ 2564882174 EngAutomaticStartEnableSwitch 3 "Not available" 2 "Error" 1 "Switch in the on state" 0 "Switch in the off state" ;
VAL_ 2564882174 AtomaticGearShiftingEnableSwitch 3 "Not available" 2 "Error" 1 "Automated Gear Shifting is enabled" 0 "Automated Gear Shifting is disabled" ;
VAL_ 2564882174 AFTRegenForceSw 3 "not available" 2 "error" 1 "active" 0 "not active" ;
VAL_ 2564882174 AFTRegenInhSw 3 "not available" 2 "error" 1 "active" 0 "not active" ;
VAL_ 2564882174 VhclLmtngSpdGovernorEnableSwitch 3 "Not available" 2 "Error" 1 "Switched enabled" 0 "Switch disabled" ;
VAL_ 2564882174 VhclLmtngSpdGvrnrIncrementSwitch 3 "Not available" 2 "Error" 1 "Switch in the on state" 0 "Switch in the off state" ;
VAL_ 2564882174 VhclLmtngSpdGvrnrDecrementSwitch 2 "Error" 1 "Switch in the on state" 0 "Switch in the off state" 3 "Not available" ;
VAL_ 2564882174 ParkBrakeCmd 3 "Don't care/Take no action" 2 "SAE Reserved" 1 "Park Brake apply requested" 0 "Park Brake apply not requested" ;
VAL_ 2564882174 SeatBeltSwitch 3 "Not Available" 2 "Error" 1 "OK" 0 "NOT Buckled" ;
VAL_ 2564882174 OperatorSeatDirectionSwitch 3 "Not Available" 2 "Error" 1 "Operator seat is facing forward" 0 "Operator seat not facing forward" ;
VAL_ 2564882174 BatteryMainSwitchHoldRq 3 "Don't care/take no action" 2 "undefined" 1 "Hold Battery Main Switch" 0 "Release Battery Main Switch" ;
VAL_ 2564882174 AuxHeaterCoolantPumpRq 3 "Don't care/take no action" 2 "Reserved" 1 "Activate water pump" 0 "Deactivate water pump" ;
VAL_ 2563833598 OpDesDisplayModeCmd2 15 "Not available" 14 "Error" 13 "Reserved" 12 "Reserved" 11 "Reserved" 10 "Reserved" 9 "Reserved" 8 "Reserved" 7 "Reserved" 6 "Reserved" 5 "Reserved" 4 "Reserved" 3 "Mode 4" 2 "Mode 3" 1 "Mode 2" 0 "Mode 1" ;
VAL_ 2563833598 OpDesDisplayModeCmd1 15 "Not available" 14 "Error" 13 "Reserved" 12 "Reserved" 11 "Reserved" 10 "Reserved" 9 "Reserved" 8 "Reserved" 7 "Reserved" 6 "Reserved" 5 "Reserved" 4 "Reserved" 3 "Mode 4" 2 "Mode 3" 1 "Mode 2" 0 "Mode 1" ;
VAL_ 2566844926 EngShutdownOverrideSwitch 3 "Not available" 2 "Error" 1 "On" 0 "Off" ;
VAL_ 2566844926 EngTestModeSwitch 3 "Not available" 2 "Error" 1 "On" 0 "Off" ;
VAL_ 2566844926 EngIdleDecrementSwitch 3 "Not available" 2 "Error" 1 "On" 0 "Off" ;
VAL_ 2566844926 EngIdleIncrementSwitch 3 "Not available" 2 "Error" 1 "On" 0 "Off" ;
VAL_ 2566844926 CruiseCtrlStates 7 "Not available" 6 "Accelerator Override" 5 "Set" 4 "Resume" 3 "Decelerate" 2 "Accelerate" 1 "Hold" 0 "Off/Disabled" ;
VAL_ 2566844926 PTOGovernorState 31 "Not available" 30 "Reseerved" 29 "Reserved" 28 "Reserved" 27 "Reserved" 26 "Reserved" 25 "Reserved" 24 "Reserved" 23 "Reserved" 22 "Reserved" 21 "Reserved" 20 "PTO set speed memory 3" 19 "PTO set speed memory 2" 18 "PTO set speed memory 1" 17 "Preprogrammed set speed 8" 16 "Preprogrammed set speed 7" 15 "Preprogrammed set speed 6" 14 "Preprogrammed set speed 5" 13 "Preprogrammed set speed 4" 12 "Preprogrammed set speed 3" 11 "Preprogrammed set speed 2" 10 "Preprogrammed set speed 1" 9 "Accelerator Override" 8 "Accelerate" 7 "Resume" 6 "Decelerate/Coast" 5 "Set" 4 "Remote Standby" 3 "Standby" 2 "Remote Hold" 1 "Hold" 0 "Off/Disabled" ;
VAL_ 2566844926 CruiseCtrlAccelerateSwitch 3 "Not available" 2 "Error" 1 "Cruise control activator in position 'accelerate'" 0 "Cruise control activator not in the position 'accelerate'" ;
VAL_ 2566844926 CruiseCtrlResumeSwitch 3 "Not available" 2 "Error" 1 "Cruise control activator in position 'resume'" 0 "Cruise control activator not in the position 'resume'" ;
VAL_ 2566844926 CruiseCtrlCoastSwitch 3 "Not available" 2 "Error" 1 "Cruise control activator in position 'coast'" 0 "Cruise control activator not in the position 'coast'" ;
VAL_ 2566844926 CruiseCtrlSetSwitch 3 "Not available" 2 "Error" 1 "Cruise control activator in position 'set'" 0 "Cruise control activator not in the position 'set'" ;
VAL_ 2566844926 ClutchSwitch 3 "Not available" 2 "Error" 1 "Clutch pedal depressed" 0 "Clutch pedal released" ;
VAL_ 2566844926 BrakeSwitch 3 "Not Available" 2 "Error" 1 "Brake pedal depressed" 0 "Brake pedal released" ;
VAL_ 2566844926 CruiseCtrlEnableSwitch 3 "Not available" 2 "Error" 1 "Cruise control enabled" 0 "Cruise control disabled" ;
VAL_ 2566844926 CruiseCtrlActive 3 "Not available" 2 "Error" 1 "Cruise control switched on" 0 "Cruise control switched off" ;
VAL_ 2566844926 ParkBrakeReleaseInhibitRq 3 "Unavailable" 2 "SAE reserved" 1 "Park Brake Release Inhibit requested" 0 "Park Brake Release Inhibit not requested" ;
VAL_ 2566844926 CruiseCtrlPauseSwitch 3 "Take No Action" 2 "Error Indicator" 1 "On" 0 "Off" ;
VAL_ 2566844926 ParkingBrakeSwitch 3 "Not available" 2 "Error" 1 "Parking brake set" 0 "Parking brake not set" ;
VAL_ 2566844926 TwoSpeedAxleSwitch 3 "Not available" 2 "Error" 1 "High speed range" 0 "Low speed range" ;
VAL_ 2566843902 PowertrainAdaptiveCCType 15 "Not Available" 14 "Reserved" 13 "Reserved" 12 "Reserved" 11 "Reserved" 10 "Reserved" 9 "Reserved" 8 "Reserved" 7 "Reserved" 6 "Reserved" 5 "Reserved" 4 "Reserved" 3 "Stop and Auto Go" 2 "Stop and Operator Go" 1 "Auto Resume" 0 "Controller does not support system based cruise control Pause/Resume" ;
VAL_ 2566843902 CtrlSetCmdSupport 3 "Not available" 2 "Error" 1 "System does support the 'Cruise Control Set Command' feature" 0 "System does not support the 'Cruise Control Set Command' feature" ;
VAL_ 2566843902 CtrlPauseCmdSupport 3 "Not available" 2 "Error" 1 "System does support the 'Cruise Control Pause Command' feature" 0 "System does not support the 'Cruise Control Pause Command' feature" ;
VAL_ 2566843902 CtrlResumeCmdSupport 3 "Not available" 2 "Error" 1 "System does support the 'Cruise Control Resume Command' feature" 0 "System does not support the 'Cruise Control Resume Command' feature" ;
VAL_ 2566843902 CtrlDisCmdSupport 3 "Not available" 2 "Reserved" 1 "System does support the 'Cruise Control Disable Command' feature" 0 "System does not support the 'Cruise Control Disable Command'" ;
